[part 1 of 2: package /STELLANTIS/EPT/COMSWCs]
AUTOSAR XML (schema 4-2-2)
package /STELLANTIS/EPT/COMSWCs
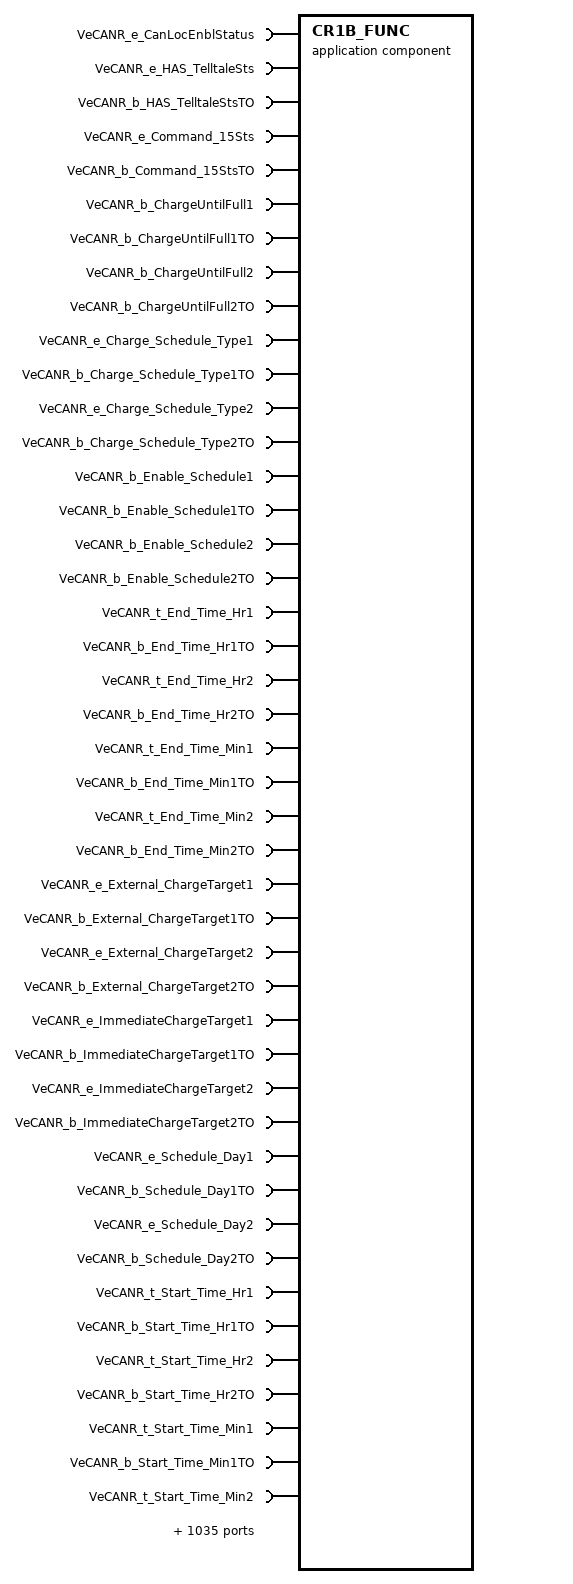
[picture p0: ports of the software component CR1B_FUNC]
  application sw component type CR1B_FUNC
    1085 x require port:
      VeCANR_e_CanLocEnblStatus: nonqueued-receiver-com-spec{data-element=VeCANR_e_CanLocEnblStatus, init-value=0}, required-interface=VeCANR_e_CanLocEnblStatus
      VeCANR_e_HAS_TelltaleSts: nonqueued-receiver-com-spec{data-element=VeCANR_e_HAS_TelltaleSts, handle-never-received=true, init-value=0}, required-interface=VeCANR_e_HAS_TelltaleSts
      VeCANR_b_HAS_TelltaleStsTO: nonqueued-receiver-com-spec{data-element=VeCANR_b_HAS_TelltaleStsTO, init-value=0}, required-interface=VeCANR_b_HAS_TelltaleStsTO
      VeCANR_e_Command_15Sts: nonqueued-receiver-com-spec{data-element=VeCANR_e_Command_15Sts, handle-never-received=true, init-value=0}, required-interface=VeCANR_e_Command_15Sts
      VeCANR_b_Command_15StsTO: nonqueued-receiver-com-spec{data-element=VeCANR_b_Command_15StsTO, init-value=0}, required-interface=VeCANR_b_Command_15StsTO
      VeCANR_b_ChargeUntilFull1: nonqueued-receiver-com-spec{data-element=VeCANR_b_ChargeUntilFull1, handle-never-received=true, init-value=0}, required-interface=VeCANR_b_ChargeUntilFull1
      VeCANR_b_ChargeUntilFull1TO: nonqueued-receiver-com-spec{data-element=VeCANR_b_ChargeUntilFull1TO, init-value=0}, required-interface=VeCANR_b_ChargeUntilFull1TO
      VeCANR_b_ChargeUntilFull2: nonqueued-receiver-com-spec{data-element=VeCANR_b_ChargeUntilFull2, handle-never-received=true, init-value=0}, required-interface=VeCANR_b_ChargeUntilFull2
      VeCANR_b_ChargeUntilFull2TO: nonqueued-receiver-com-spec{data-element=VeCANR_b_ChargeUntilFull2TO, init-value=0}, required-interface=VeCANR_b_ChargeUntilFull2TO
      VeCANR_e_Charge_Schedule_Type1: nonqueued-receiver-com-spec{data-element=VeCANR_e_Charge_Schedule_Type1, handle-never-received=true, init-value=0}, required-interface=VeCANR_e_Charge_Schedule_Type1
      VeCANR_b_Charge_Schedule_Type1TO: nonqueued-receiver-com-spec{data-element=VeCANR_b_Charge_Schedule_Type1TO, init-value=0}, required-interface=VeCANR_b_Charge_Schedule_Type1TO
      VeCANR_e_Charge_Schedule_Type2: nonqueued-receiver-com-spec{data-element=VeCANR_e_Charge_Schedule_Type2, handle-never-received=true, init-value=0}, required-interface=VeCANR_e_Charge_Schedule_Type2
      VeCANR_b_Charge_Schedule_Type2TO: nonqueued-receiver-com-spec{data-element=VeCANR_b_Charge_Schedule_Type2TO, init-value=0}, required-interface=VeCANR_b_Charge_Schedule_Type2TO
      VeCANR_b_Enable_Schedule1: nonqueued-receiver-com-spec{data-element=VeCANR_b_Enable_Schedule1, handle-never-received=true, init-value=0}, required-interface=VeCANR_b_Enable_Schedule1
      VeCANR_b_Enable_Schedule1TO: nonqueued-receiver-com-spec{data-element=VeCANR_b_Enable_Schedule1TO, init-value=0}, required-interface=VeCANR_b_Enable_Schedule1TO
      VeCANR_b_Enable_Schedule2: nonqueued-receiver-com-spec{data-element=VeCANR_b_Enable_Schedule2, handle-never-received=true, init-value=0}, required-interface=VeCANR_b_Enable_Schedule2
      VeCANR_b_Enable_Schedule2TO: nonqueued-receiver-com-spec{data-element=VeCANR_b_Enable_Schedule2TO, init-value=0}, required-interface=VeCANR_b_Enable_Schedule2TO
      VeCANR_t_End_Time_Hr1: nonqueued-receiver-com-spec{data-element=VeCANR_t_End_Time_Hr1, handle-never-received=true, init-value=0}, required-interface=VeCANR_t_End_Time_Hr1
      VeCANR_b_End_Time_Hr1TO: nonqueued-receiver-com-spec{data-element=VeCANR_b_End_Time_Hr1TO, init-value=0}, required-interface=VeCANR_b_End_Time_Hr1TO
      VeCANR_t_End_Time_Hr2: nonqueued-receiver-com-spec{data-element=VeCANR_t_End_Time_Hr2, handle-never-received=true, init-value=0}, required-interface=VeCANR_t_End_Time_Hr2
      VeCANR_b_End_Time_Hr2TO: nonqueued-receiver-com-spec{data-element=VeCANR_b_End_Time_Hr2TO, init-value=0}, required-interface=VeCANR_b_End_Time_Hr2TO
      VeCANR_t_End_Time_Min1: nonqueued-receiver-com-spec{data-element=VeCANR_t_End_Time_Min1, handle-never-received=true, init-value=0}, required-interface=VeCANR_t_End_Time_Min1
      VeCANR_b_End_Time_Min1TO: nonqueued-receiver-com-spec{data-element=VeCANR_b_End_Time_Min1TO, init-value=0}, required-interface=VeCANR_b_End_Time_Min1TO
      VeCANR_t_End_Time_Min2: nonqueued-receiver-com-spec{data-element=VeCANR_t_End_Time_Min2, handle-never-received=true, init-value=0}, required-interface=VeCANR_t_End_Time_Min2
      VeCANR_b_End_Time_Min2TO: nonqueued-receiver-com-spec{data-element=VeCANR_b_End_Time_Min2TO, init-value=0}, required-interface=VeCANR_b_End_Time_Min2TO
      VeCANR_e_External_ChargeTarget1: nonqueued-receiver-com-spec{data-element=VeCANR_e_External_ChargeTarget1, handle-never-received=true, init-value=0}, required-interface=VeCANR_e_External_ChargeTarget1
      VeCANR_b_External_ChargeTarget1TO: nonqueued-receiver-com-spec{data-element=VeCANR_b_External_ChargeTarget1TO, init-value=0}, required-interface=VeCANR_b_External_ChargeTarget1TO
      VeCANR_e_External_ChargeTarget2: nonqueued-receiver-com-spec{data-element=VeCANR_e_External_ChargeTarget2, handle-never-received=true, init-value=0}, required-interface=VeCANR_e_External_ChargeTarget2
      VeCANR_b_External_ChargeTarget2TO: nonqueued-receiver-com-spec{data-element=VeCANR_b_External_ChargeTarget2TO, init-value=0}, required-interface=VeCANR_b_External_ChargeTarget2TO
      VeCANR_e_ImmediateChargeTarget1: nonqueued-receiver-com-spec{data-element=VeCANR_e_ImmediateChargeTarget1, handle-never-received=true, init-value=0}, required-interface=VeCANR_e_ImmediateChargeTarget1
      VeCANR_b_ImmediateChargeTarget1TO: nonqueued-receiver-com-spec{data-element=VeCANR_b_ImmediateChargeTarget1TO, init-value=0}, required-interface=VeCANR_b_ImmediateChargeTarget1TO
      VeCANR_e_ImmediateChargeTarget2: nonqueued-receiver-com-spec{data-element=VeCANR_e_ImmediateChargeTarget2, handle-never-received=true, init-value=0}, required-interface=VeCANR_e_ImmediateChargeTarget2
      VeCANR_b_ImmediateChargeTarget2TO: nonqueued-receiver-com-spec{data-element=VeCANR_b_ImmediateChargeTarget2TO, init-value=0}, required-interface=VeCANR_b_ImmediateChargeTarget2TO
      VeCANR_e_Schedule_Day1: nonqueued-receiver-com-spec{data-element=VeCANR_e_Schedule_Day1, handle-never-received=true, init-value=0}, required-interface=VeCANR_e_Schedule_Day1
      VeCANR_b_Schedule_Day1TO: nonqueued-receiver-com-spec{data-element=VeCANR_b_Schedule_Day1TO, init-value=0}, required-interface=VeCANR_b_Schedule_Day1TO
      VeCANR_e_Schedule_Day2: nonqueued-receiver-com-spec{data-element=VeCANR_e_Schedule_Day2, handle-never-received=true, init-value=0}, required-interface=VeCANR_e_Schedule_Day2
      VeCANR_b_Schedule_Day2TO: nonqueued-receiver-com-spec{data-element=VeCANR_b_Schedule_Day2TO, init-value=0}, required-interface=VeCANR_b_Schedule_Day2TO
      VeCANR_t_Start_Time_Hr1: nonqueued-receiver-com-spec{data-element=VeCANR_t_Start_Time_Hr1, handle-never-received=true, init-value=0}, required-interface=VeCANR_t_Start_Time_Hr1
      VeCANR_b_Start_Time_Hr1TO: nonqueued-receiver-com-spec{data-element=VeCANR_b_Start_Time_Hr1TO, init-value=0}, required-interface=VeCANR_b_Start_Time_Hr1TO
      VeCANR_t_Start_Time_Hr2: nonqueued-receiver-com-spec{data-element=VeCANR_t_Start_Time_Hr2, handle-never-received=true, init-value=0}, required-interface=VeCANR_t_Start_Time_Hr2
      VeCANR_b_Start_Time_Hr2TO: nonqueued-receiver-com-spec{data-element=VeCANR_b_Start_Time_Hr2TO, init-value=0}, required-interface=VeCANR_b_Start_Time_Hr2TO
      VeCANR_t_Start_Time_Min1: nonqueued-receiver-com-spec{data-element=VeCANR_t_Start_Time_Min1, handle-never-received=true, init-value=0}, required-interface=VeCANR_t_Start_Time_Min1
      VeCANR_b_Start_Time_Min1TO: nonqueued-receiver-com-spec{data-element=VeCANR_b_Start_Time_Min1TO, init-value=0}, required-interface=VeCANR_b_Start_Time_Min1TO
      VeCANR_t_Start_Time_Min2: nonqueued-receiver-com-spec{data-element=VeCANR_t_Start_Time_Min2, handle-never-received=true, init-value=0}, required-interface=VeCANR_t_Start_Time_Min2
      VeCANR_b_Start_Time_Min2TO: nonqueued-receiver-com-spec{data-element=VeCANR_b_Start_Time_Min2TO, init-value=0}, required-interface=VeCANR_b_Start_Time_Min2TO
      VeCANR_b_Submit_Schedule1: nonqueued-receiver-com-spec{data-element=VeCANR_b_Submit_Schedule1, handle-never-received=true, init-value=0}, required-interface=VeCANR_b_Submit_Schedule1
      VeCANR_b_Submit_Schedule1TO: nonqueued-receiver-com-spec{data-element=VeCANR_b_Submit_Schedule1TO, init-value=0}, required-interface=VeCANR_b_Submit_Schedule1TO
      VeCANR_b_Submit_Schedule2: nonqueued-receiver-com-spec{data-element=VeCANR_b_Submit_Schedule2, handle-never-received=true, init-value=0}, required-interface=VeCANR_b_Submit_Schedule2
      VeCANR_b_Submit_Schedule2TO: nonqueued-receiver-com-spec{data-element=VeCANR_b_Submit_Schedule2TO, init-value=0}, required-interface=VeCANR_b_Submit_Schedule2TO
      VeCANR_e_AllowClimateSchd1: nonqueued-receiver-com-spec{data-element=VeCANR_e_AllowClimateSchd1, handle-never-received=true, init-value=0}, required-interface=VeCANR_e_AllowClimateSchd1
      VeCANR_b_AllowClimateSchd1TO: nonqueued-receiver-com-spec{data-element=VeCANR_b_AllowClimateSchd1TO, init-value=0}, required-interface=VeCANR_b_AllowClimateSchd1TO
      VeCANR_e_AllowClimateSchd2: nonqueued-receiver-com-spec{data-element=VeCANR_e_AllowClimateSchd2, handle-never-received=true, init-value=0}, required-interface=VeCANR_e_AllowClimateSchd2
      VeCANR_b_AllowClimateSchd2TO: nonqueued-receiver-com-spec{data-element=VeCANR_b_AllowClimateSchd2TO, init-value=0}, required-interface=VeCANR_b_AllowClimateSchd2TO
      VeCANR_e_ClimateSchd1_Day: nonqueued-receiver-com-spec{data-element=VeCANR_e_ClimateSchd1_Day, handle-never-received=true, init-value=0}, required-interface=VeCANR_e_ClimateSchd1_Day
      VeCANR_b_ClimateSchd1_DayTO: nonqueued-receiver-com-spec{data-element=VeCANR_b_ClimateSchd1_DayTO, init-value=0}, required-interface=VeCANR_b_ClimateSchd1_DayTO
      VeCANR_t_ClimateSchd1_Dprtr_Hr: nonqueued-receiver-com-spec{data-element=VeCANR_t_ClimateSchd1_Dprtr_Hr, handle-never-received=true, init-value=0}, required-interface=VeCANR_t_ClimateSchd1_Dprtr_Hr
      VeCANR_b_ClimateSchd1_Dprtr_HrTO: nonqueued-receiver-com-spec{data-element=VeCANR_b_ClimateSchd1_Dprtr_HrTO, init-value=0}, required-interface=VeCANR_b_ClimateSchd1_Dprtr_HrTO
      VeCANR_t_ClimateSchd1_Dprtr_Min: nonqueued-receiver-com-spec{data-element=VeCANR_t_ClimateSchd1_Dprtr_Min, handle-never-received=true, init-value=0}, required-interface=VeCANR_t_ClimateSchd1_Dprtr_Min
      VeCANR_b_ClimateSchd1_Dprtr_MinTO: nonqueued-receiver-com-spec{data-element=VeCANR_b_ClimateSchd1_Dprtr_MinTO, init-value=0}, required-interface=VeCANR_b_ClimateSchd1_Dprtr_MinTO
      VeCANR_e_ClimateSchd2_Day: nonqueued-receiver-com-spec{data-element=VeCANR_e_ClimateSchd2_Day, handle-never-received=true, init-value=0}, required-interface=VeCANR_e_ClimateSchd2_Day
      VeCANR_b_ClimateSchd2_DayTO: nonqueued-receiver-com-spec{data-element=VeCANR_b_ClimateSchd2_DayTO, init-value=0}, required-interface=VeCANR_b_ClimateSchd2_DayTO
      VeCANR_t_ClimateSchd2_Dprtr_Hr: nonqueued-receiver-com-spec{data-element=VeCANR_t_ClimateSchd2_Dprtr_Hr, handle-never-received=true, init-value=0}, required-interface=VeCANR_t_ClimateSchd2_Dprtr_Hr
      VeCANR_b_ClimateSchd2_Dprtr_HrTO: nonqueued-receiver-com-spec{data-element=VeCANR_b_ClimateSchd2_Dprtr_HrTO, init-value=0}, required-interface=VeCANR_b_ClimateSchd2_Dprtr_HrTO
      VeCANR_t_ClimateSchd2_Dprtr_Min: nonqueued-receiver-com-spec{data-element=VeCANR_t_ClimateSchd2_Dprtr_Min, handle-never-received=true, init-value=0}, required-interface=VeCANR_t_ClimateSchd2_Dprtr_Min
      VeCANR_b_ClimateSchd2_Dprtr_MinTO: nonqueued-receiver-com-spec{data-element=VeCANR_b_ClimateSchd2_Dprtr_MinTO, init-value=0}, required-interface=VeCANR_b_ClimateSchd2_Dprtr_MinTO
      VeCANR_T_Climate_Cabin_Temp1: nonqueued-receiver-com-spec{data-element=VeCANR_T_Climate_Cabin_Temp1, handle-never-received=true, init-value=0}, required-interface=VeCANR_T_Climate_Cabin_Temp1
      VeCANR_b_Climate_Cabin_Temp1TO: nonqueued-receiver-com-spec{data-element=VeCANR_b_Climate_Cabin_Temp1TO, init-value=0}, required-interface=VeCANR_b_Climate_Cabin_Temp1TO
      VeCANR_T_Climate_Cabin_Temp2: nonqueued-receiver-com-spec{data-element=VeCANR_T_Climate_Cabin_Temp2, handle-never-received=true, init-value=0}, required-interface=VeCANR_T_Climate_Cabin_Temp2
      VeCANR_b_Climate_Cabin_Temp2TO: nonqueued-receiver-com-spec{data-element=VeCANR_b_Climate_Cabin_Temp2TO, init-value=0}, required-interface=VeCANR_b_Climate_Cabin_Temp2TO
      VeCANR_b_Enable_ClimateSchd1: nonqueued-receiver-com-spec{data-element=VeCANR_b_Enable_ClimateSchd1, handle-never-received=true, init-value=0}, required-interface=VeCANR_b_Enable_ClimateSchd1
      VeCANR_b_Enable_ClimateSchd1TO: nonqueued-receiver-com-spec{data-element=VeCANR_b_Enable_ClimateSchd1TO, init-value=0}, required-interface=VeCANR_b_Enable_ClimateSchd1TO
      VeCANR_b_Enable_ClimateSchd2: nonqueued-receiver-com-spec{data-element=VeCANR_b_Enable_ClimateSchd2, handle-never-received=true, init-value=0}, required-interface=VeCANR_b_Enable_ClimateSchd2
      VeCANR_b_Enable_ClimateSchd2TO: nonqueued-receiver-com-spec{data-element=VeCANR_b_Enable_ClimateSchd2TO, init-value=0}, required-interface=VeCANR_b_Enable_ClimateSchd2TO
      VeCANR_b_Submit_ClimateSchd1: nonqueued-receiver-com-spec{data-element=VeCANR_b_Submit_ClimateSchd1, handle-never-received=true, init-value=0}, required-interface=VeCANR_b_Submit_ClimateSchd1
      VeCANR_b_Submit_ClimateSchd1TO: nonqueued-receiver-com-spec{data-element=VeCANR_b_Submit_ClimateSchd1TO, init-value=0}, required-interface=VeCANR_b_Submit_ClimateSchd1TO
      VeCANR_b_Submit_ClimateSchd2: nonqueued-receiver-com-spec{data-element=VeCANR_b_Submit_ClimateSchd2, handle-never-received=true, init-value=0}, required-interface=VeCANR_b_Submit_ClimateSchd2
      VeCANR_b_Submit_ClimateSchd2TO: nonqueued-receiver-com-spec{data-element=VeCANR_b_Submit_ClimateSchd2TO, init-value=0}, required-interface=VeCANR_b_Submit_ClimateSchd2TO
      VeCANR_T_Climate_TBM_CabinTemp1: nonqueued-receiver-com-spec{data-element=VeCANR_T_Climate_TBM_CabinTemp1, handle-never-received=true, init-value=0}, required-interface=VeCANR_T_Climate_TBM_CabinTemp1
      VeCANR_b_Climate_TBM_CabinTemp1TO: nonqueued-receiver-com-spec{data-element=VeCANR_b_Climate_TBM_CabinTemp1TO, init-value=0}, required-interface=VeCANR_b_Climate_TBM_CabinTemp1TO
      VeCANR_T_Climate_TBM_CabinTemp2: nonqueued-receiver-com-spec{data-element=VeCANR_T_Climate_TBM_CabinTemp2, handle-never-received=true, init-value=0}, required-interface=VeCANR_T_Climate_TBM_CabinTemp2
      VeCANR_b_Climate_TBM_CabinTemp2TO: nonqueued-receiver-com-spec{data-element=VeCANR_b_Climate_TBM_CabinTemp2TO, init-value=0}, required-interface=VeCANR_b_Climate_TBM_CabinTemp2TO
      VeCANR_e_TBM_AllowClimateSchd1: nonqueued-receiver-com-spec{data-element=VeCANR_e_TBM_AllowClimateSchd1, handle-never-received=true, init-value=0}, required-interface=VeCANR_e_TBM_AllowClimateSchd1
      VeCANR_b_TBM_AllowClimateSchd1TO: nonqueued-receiver-com-spec{data-element=VeCANR_b_TBM_AllowClimateSchd1TO, init-value=0}, required-interface=VeCANR_b_TBM_AllowClimateSchd1TO
      VeCANR_e_TBM_AllowClimateSchd2: nonqueued-receiver-com-spec{data-element=VeCANR_e_TBM_AllowClimateSchd2, handle-never-received=true, init-value=0}, required-interface=VeCANR_e_TBM_AllowClimateSchd2
      VeCANR_b_TBM_AllowClimateSchd2TO: nonqueued-receiver-com-spec{data-element=VeCANR_b_TBM_AllowClimateSchd2TO, init-value=0}, required-interface=VeCANR_b_TBM_AllowClimateSchd2TO
      VeCANR_e_TBM_ClimateSchd1_Day: nonqueued-receiver-com-spec{data-element=VeCANR_e_TBM_ClimateSchd1_Day, handle-never-received=true, init-value=0}, required-interface=VeCANR_e_TBM_ClimateSchd1_Day
      VeCANR_b_TBM_ClimateSchd1_DayTO: nonqueued-receiver-com-spec{data-element=VeCANR_b_TBM_ClimateSchd1_DayTO, init-value=0}, required-interface=VeCANR_b_TBM_ClimateSchd1_DayTO
      VeCANR_t_TBM_ClimSchd1DprtrHr: nonqueued-receiver-com-spec{data-element=VeCANR_t_TBM_ClimSchd1DprtrHr, handle-never-received=true, init-value=0}, required-interface=VeCANR_t_TBM_ClimSchd1DprtrHr
      VeCANR_b_TBM_ClimSchd1DprtrHrTO: nonqueued-receiver-com-spec{data-element=VeCANR_b_TBM_ClimSchd1DprtrHrTO, init-value=0}, required-interface=VeCANR_b_TBM_ClimSchd1DprtrHrTO
      VeCANR_t_TBM_ClimSchd1DprtrMin: nonqueued-receiver-com-spec{data-element=VeCANR_t_TBM_ClimSchd1DprtrMin, handle-never-received=true, init-value=0}, required-interface=VeCANR_t_TBM_ClimSchd1DprtrMin
      VeCANR_b_TBM_ClimSchd1DprtrMinTO: nonqueued-receiver-com-spec{data-element=VeCANR_b_TBM_ClimSchd1DprtrMinTO, init-value=0}, required-interface=VeCANR_b_TBM_ClimSchd1DprtrMinTO
      VeCANR_e_TBM_ClimateSchd2_Day: nonqueued-receiver-com-spec{data-element=VeCANR_e_TBM_ClimateSchd2_Day, handle-never-received=true, init-value=0}, required-interface=VeCANR_e_TBM_ClimateSchd2_Day
      VeCANR_b_TBM_ClimateSchd2_DayTO: nonqueued-receiver-com-spec{data-element=VeCANR_b_TBM_ClimateSchd2_DayTO, init-value=0}, required-interface=VeCANR_b_TBM_ClimateSchd2_DayTO
      VeCANR_t_TBM_ClimSchd2DprtrHr: nonqueued-receiver-com-spec{data-element=VeCANR_t_TBM_ClimSchd2DprtrHr, handle-never-received=true, init-value=0}, required-interface=VeCANR_t_TBM_ClimSchd2DprtrHr
      VeCANR_b_TBM_ClimSchd2DprtrHrTO: nonqueued-receiver-com-spec{data-element=VeCANR_b_TBM_ClimSchd2DprtrHrTO, init-value=0}, required-interface=VeCANR_b_TBM_ClimSchd2DprtrHrTO
      VeCANR_t_TBM_ClimSchd2DprtrMin: nonqueued-receiver-com-spec{data-element=VeCANR_t_TBM_ClimSchd2DprtrMin, handle-never-received=true, init-value=0}, required-interface=VeCANR_t_TBM_ClimSchd2DprtrMin
      VeCANR_b_TBM_ClimSchd2DprtrMinTO: nonqueued-receiver-com-spec{data-element=VeCANR_b_TBM_ClimSchd2DprtrMinTO, init-value=0}, required-interface=VeCANR_b_TBM_ClimSchd2DprtrMinTO
      VeCANR_b_TBM_EnableClimateSchd1: nonqueued-receiver-com-spec{data-element=VeCANR_b_TBM_EnableClimateSchd1, handle-never-received=true, init-value=0}, required-interface=VeCANR_b_TBM_EnableClimateSchd1
      VeCANR_b_TBM_EnableClimateSchd1TO: nonqueued-receiver-com-spec{data-element=VeCANR_b_TBM_EnableClimateSchd1TO, init-value=0}, required-interface=VeCANR_b_TBM_EnableClimateSchd1TO
      VeCANR_b_TBM_EnableClimateSchd2: nonqueued-receiver-com-spec{data-element=VeCANR_b_TBM_EnableClimateSchd2, handle-never-received=true, init-value=0}, required-interface=VeCANR_b_TBM_EnableClimateSchd2
      VeCANR_b_TBM_EnableClimateSchd2TO: nonqueued-receiver-com-spec{data-element=VeCANR_b_TBM_EnableClimateSchd2TO, init-value=0}, required-interface=VeCANR_b_TBM_EnableClimateSchd2TO
      VeCANR_b_TBM_SubmitClimateSchd1: nonqueued-receiver-com-spec{data-element=VeCANR_b_TBM_SubmitClimateSchd1, handle-never-received=true, init-value=0}, required-interface=VeCANR_b_TBM_SubmitClimateSchd1
      VeCANR_b_TBM_SubmitClimateSchd1TO: nonqueued-receiver-com-spec{data-element=VeCANR_b_TBM_SubmitClimateSchd1TO, init-value=0}, required-interface=VeCANR_b_TBM_SubmitClimateSchd1TO
      VeCANR_b_TBM_SubmitClimateSchd2: nonqueued-receiver-com-spec{data-element=VeCANR_b_TBM_SubmitClimateSchd2, handle-never-received=true, init-value=0}, required-interface=VeCANR_b_TBM_SubmitClimateSchd2
      VeCANR_b_TBM_SubmitClimateSchd2TO: nonqueued-receiver-com-spec{data-element=VeCANR_b_TBM_SubmitClimateSchd2TO, init-value=0}, required-interface=VeCANR_b_TBM_SubmitClimateSchd2TO
      VeCANR_b_CooperativeVehclLocatn: nonqueued-receiver-com-spec{data-element=VeCANR_b_CooperativeVehclLocatn, handle-never-received=true, init-value=0}, required-interface=VeCANR_b_CooperativeVehclLocatn
      VeCANR_b_CooperativeVehclLocatnTO: nonqueued-receiver-com-spec{data-element=VeCANR_b_CooperativeVehclLocatnTO, init-value=0}, required-interface=VeCANR_b_CooperativeVehclLocatnTO
      VeCANR_e_Remote_Chargeport_Cmnd: nonqueued-receiver-com-spec{data-element=VeCANR_e_Remote_Chargeport_Cmnd, handle-never-received=true, init-value=0}, required-interface=VeCANR_e_Remote_Chargeport_Cmnd
      VeCANR_b_Remote_Chargeport_CmndTO: nonqueued-receiver-com-spec{data-element=VeCANR_b_Remote_Chargeport_CmndTO, init-value=0}, required-interface=VeCANR_b_Remote_Chargeport_CmndTO
      VeCANR_e_TBMCooperativeChrgCmnd: nonqueued-receiver-com-spec{data-element=VeCANR_e_TBMCooperativeChrgCmnd, handle-never-received=true, init-value=0}, required-interface=VeCANR_e_TBMCooperativeChrgCmnd
      VeCANR_b_TBMCooperativeChrgCmndTO: nonqueued-receiver-com-spec{data-element=VeCANR_b_TBMCooperativeChrgCmndTO, init-value=0}, required-interface=VeCANR_b_TBMCooperativeChrgCmndTO
      VeCANR_b_TBM_StopCharge: nonqueued-receiver-com-spec{data-element=VeCANR_b_TBM_StopCharge, handle-never-received=true, init-value=0}, required-interface=VeCANR_b_TBM_StopCharge
      VeCANR_b_TBM_StopChargeTO: nonqueued-receiver-com-spec{data-element=VeCANR_b_TBM_StopChargeTO, init-value=0}, required-interface=VeCANR_b_TBM_StopChargeTO
      VeCANR_e_TBMChrgSchedulType1Req: nonqueued-receiver-com-spec{data-element=VeCANR_e_TBMChrgSchedulType1Req, handle-never-received=true, init-value=0}, required-interface=VeCANR_e_TBMChrgSchedulType1Req
      VeCANR_b_TBMChrgSchedulType1ReqTO: nonqueued-receiver-com-spec{data-element=VeCANR_b_TBMChrgSchedulType1ReqTO, init-value=0}, required-interface=VeCANR_b_TBMChrgSchedulType1ReqTO
      VeCANR_e_TBMChrgSchedulType2Req: nonqueued-receiver-com-spec{data-element=VeCANR_e_TBMChrgSchedulType2Req, handle-never-received=true, init-value=0}, required-interface=VeCANR_e_TBMChrgSchedulType2Req
      VeCANR_b_TBMChrgSchedulType2ReqTO: nonqueued-receiver-com-spec{data-element=VeCANR_b_TBMChrgSchedulType2ReqTO, init-value=0}, required-interface=VeCANR_b_TBMChrgSchedulType2ReqTO
      VeCANR_b_TBM_ChargeUntilFull1: nonqueued-receiver-com-spec{data-element=VeCANR_b_TBM_ChargeUntilFull1, handle-never-received=true, init-value=0}, required-interface=VeCANR_b_TBM_ChargeUntilFull1
      VeCANR_b_TBM_ChargeUntilFull1TO: nonqueued-receiver-com-spec{data-element=VeCANR_b_TBM_ChargeUntilFull1TO, init-value=0}, required-interface=VeCANR_b_TBM_ChargeUntilFull1TO
      VeCANR_b_TBM_ChargeUntilFull2: nonqueued-receiver-com-spec{data-element=VeCANR_b_TBM_ChargeUntilFull2, handle-never-received=true, init-value=0}, required-interface=VeCANR_b_TBM_ChargeUntilFull2
      VeCANR_b_TBM_ChargeUntilFull2TO: nonqueued-receiver-com-spec{data-element=VeCANR_b_TBM_ChargeUntilFull2TO, init-value=0}, required-interface=VeCANR_b_TBM_ChargeUntilFull2TO
      VeCANR_b_TBM_Charge_Now: nonqueued-receiver-com-spec{data-element=VeCANR_b_TBM_Charge_Now, handle-never-received=true, init-value=0}, required-interface=VeCANR_b_TBM_Charge_Now
      VeCANR_b_TBM_Charge_NowTO: nonqueued-receiver-com-spec{data-element=VeCANR_b_TBM_Charge_NowTO, init-value=0}, required-interface=VeCANR_b_TBM_Charge_NowTO
      VeCANR_b_TBM_Enable_Schedule1: nonqueued-receiver-com-spec{data-element=VeCANR_b_TBM_Enable_Schedule1, handle-never-received=true, init-value=0}, required-interface=VeCANR_b_TBM_Enable_Schedule1
      VeCANR_b_TBM_Enable_Schedule1TO: nonqueued-receiver-com-spec{data-element=VeCANR_b_TBM_Enable_Schedule1TO, init-value=0}, required-interface=VeCANR_b_TBM_Enable_Schedule1TO
      VeCANR_b_TBM_Enable_Schedule2: nonqueued-receiver-com-spec{data-element=VeCANR_b_TBM_Enable_Schedule2, handle-never-received=true, init-value=0}, required-interface=VeCANR_b_TBM_Enable_Schedule2
      VeCANR_b_TBM_Enable_Schedule2TO: nonqueued-receiver-com-spec{data-element=VeCANR_b_TBM_Enable_Schedule2TO, init-value=0}, required-interface=VeCANR_b_TBM_Enable_Schedule2TO
      VeCANR_t_TBM_End_Time_Hr1: nonqueued-receiver-com-spec{data-element=VeCANR_t_TBM_End_Time_Hr1, handle-never-received=true, init-value=0}, required-interface=VeCANR_t_TBM_End_Time_Hr1
      VeCANR_b_TBM_End_Time_Hr1TO: nonqueued-receiver-com-spec{data-element=VeCANR_b_TBM_End_Time_Hr1TO, init-value=0}, required-interface=VeCANR_b_TBM_End_Time_Hr1TO
      VeCANR_t_TBM_End_Time_Hr2: nonqueued-receiver-com-spec{data-element=VeCANR_t_TBM_End_Time_Hr2, handle-never-received=true, init-value=0}, required-interface=VeCANR_t_TBM_End_Time_Hr2
      VeCANR_b_TBM_End_Time_Hr2TO: nonqueued-receiver-com-spec{data-element=VeCANR_b_TBM_End_Time_Hr2TO, init-value=0}, required-interface=VeCANR_b_TBM_End_Time_Hr2TO
      VeCANR_t_TBM_End_Time_Min1: nonqueued-receiver-com-spec{data-element=VeCANR_t_TBM_End_Time_Min1, handle-never-received=true, init-value=0}, required-interface=VeCANR_t_TBM_End_Time_Min1
      VeCANR_b_TBM_End_Time_Min1TO: nonqueued-receiver-com-spec{data-element=VeCANR_b_TBM_End_Time_Min1TO, init-value=0}, required-interface=VeCANR_b_TBM_End_Time_Min1TO
      VeCANR_t_TBM_End_Time_Min2: nonqueued-receiver-com-spec{data-element=VeCANR_t_TBM_End_Time_Min2, handle-never-received=true, init-value=0}, required-interface=VeCANR_t_TBM_End_Time_Min2
      VeCANR_b_TBM_End_Time_Min2TO: nonqueued-receiver-com-spec{data-element=VeCANR_b_TBM_End_Time_Min2TO, init-value=0}, required-interface=VeCANR_b_TBM_End_Time_Min2TO
      VeCANR_e_TBMExtrnlChrgTarget1: nonqueued-receiver-com-spec{data-element=VeCANR_e_TBMExtrnlChrgTarget1, handle-never-received=true, init-value=0}, required-interface=VeCANR_e_TBMExtrnlChrgTarget1
      VeCANR_b_TBMExtrnlChrgTarget1TO: nonqueued-receiver-com-spec{data-element=VeCANR_b_TBMExtrnlChrgTarget1TO, init-value=0}, required-interface=VeCANR_b_TBMExtrnlChrgTarget1TO
      VeCANR_e_TBM_ExtrnlChargTarget2: nonqueued-receiver-com-spec{data-element=VeCANR_e_TBM_ExtrnlChargTarget2, handle-never-received=true, init-value=0}, required-interface=VeCANR_e_TBM_ExtrnlChargTarget2
      VeCANR_b_TBM_ExtrnlChargTarget2TO: nonqueued-receiver-com-spec{data-element=VeCANR_b_TBM_ExtrnlChargTarget2TO, init-value=0}, required-interface=VeCANR_b_TBM_ExtrnlChargTarget2TO
      VeCANR_e_TBMImmediatChrgTarget1: nonqueued-receiver-com-spec{data-element=VeCANR_e_TBMImmediatChrgTarget1, handle-never-received=true, init-value=0}, required-interface=VeCANR_e_TBMImmediatChrgTarget1
      VeCANR_b_TBMImmediatChrgTarget1TO: nonqueued-receiver-com-spec{data-element=VeCANR_b_TBMImmediatChrgTarget1TO, init-value=0}, required-interface=VeCANR_b_TBMImmediatChrgTarget1TO
      VeCANR_e_TBMImmediatChrgTarget2: nonqueued-receiver-com-spec{data-element=VeCANR_e_TBMImmediatChrgTarget2, handle-never-received=true, init-value=0}, required-interface=VeCANR_e_TBMImmediatChrgTarget2
      VeCANR_b_TBMImmediatChrgTarget2TO: nonqueued-receiver-com-spec{data-element=VeCANR_b_TBMImmediatChrgTarget2TO, init-value=0}, required-interface=VeCANR_b_TBMImmediatChrgTarget2TO
      VeCANR_e_TBM_Schedule_Day1: nonqueued-receiver-com-spec{data-element=VeCANR_e_TBM_Schedule_Day1, handle-never-received=true, init-value=0}, required-interface=VeCANR_e_TBM_Schedule_Day1
      VeCANR_b_TBM_Schedule_Day1TO: nonqueued-receiver-com-spec{data-element=VeCANR_b_TBM_Schedule_Day1TO, init-value=0}, required-interface=VeCANR_b_TBM_Schedule_Day1TO
      VeCANR_e_TBM_Schedule_Day2: nonqueued-receiver-com-spec{data-element=VeCANR_e_TBM_Schedule_Day2, handle-never-received=true, init-value=0}, required-interface=VeCANR_e_TBM_Schedule_Day2
      VeCANR_b_TBM_Schedule_Day2TO: nonqueued-receiver-com-spec{data-element=VeCANR_b_TBM_Schedule_Day2TO, init-value=0}, required-interface=VeCANR_b_TBM_Schedule_Day2TO
      VeCANR_t_TBM_Start_Time_Hr1: nonqueued-receiver-com-spec{data-element=VeCANR_t_TBM_Start_Time_Hr1, handle-never-received=true, init-value=0}, required-interface=VeCANR_t_TBM_Start_Time_Hr1
      VeCANR_b_TBM_Start_Time_Hr1TO: nonqueued-receiver-com-spec{data-element=VeCANR_b_TBM_Start_Time_Hr1TO, init-value=0}, required-interface=VeCANR_b_TBM_Start_Time_Hr1TO
      VeCANR_t_TBM_Start_Time_Hr2: nonqueued-receiver-com-spec{data-element=VeCANR_t_TBM_Start_Time_Hr2, handle-never-received=true, init-value=0}, required-interface=VeCANR_t_TBM_Start_Time_Hr2
      VeCANR_b_TBM_Start_Time_Hr2TO: nonqueued-receiver-com-spec{data-element=VeCANR_b_TBM_Start_Time_Hr2TO, init-value=0}, required-interface=VeCANR_b_TBM_Start_Time_Hr2TO
      VeCANR_t_TBM_Start_Time_Min1: nonqueued-receiver-com-spec{data-element=VeCANR_t_TBM_Start_Time_Min1, handle-never-received=true, init-value=0}, required-interface=VeCANR_t_TBM_Start_Time_Min1
      VeCANR_b_TBM_Start_Time_Min1TO: nonqueued-receiver-com-spec{data-element=VeCANR_b_TBM_Start_Time_Min1TO, init-value=0}, required-interface=VeCANR_b_TBM_Start_Time_Min1TO
      VeCANR_t_TBM_Start_Time_Min2: nonqueued-receiver-com-spec{data-element=VeCANR_t_TBM_Start_Time_Min2, handle-never-received=true, init-value=0}, required-interface=VeCANR_t_TBM_Start_Time_Min2
      VeCANR_b_TBM_Start_Time_Min2TO: nonqueued-receiver-com-spec{data-element=VeCANR_b_TBM_Start_Time_Min2TO, init-value=0}, required-interface=VeCANR_b_TBM_Start_Time_Min2TO
      VeCANR_b_TBM_Submit_Schedule1: nonqueued-receiver-com-spec{data-element=VeCANR_b_TBM_Submit_Schedule1, handle-never-received=true, init-value=0}, required-interface=VeCANR_b_TBM_Submit_Schedule1
      VeCANR_b_TBM_Submit_Schedule1TO: nonqueued-receiver-com-spec{data-element=VeCANR_b_TBM_Submit_Schedule1TO, init-value=0}, required-interface=VeCANR_b_TBM_Submit_Schedule1TO
      VeCANR_b_TBM_Submit_Schedule2: nonqueued-receiver-com-spec{data-element=VeCANR_b_TBM_Submit_Schedule2, handle-never-received=true, init-value=0}, required-interface=VeCANR_b_TBM_Submit_Schedule2
      VeCANR_b_TBM_Submit_Schedule2TO: nonqueued-receiver-com-spec{data-element=VeCANR_b_TBM_Submit_Schedule2TO, init-value=0}, required-interface=VeCANR_b_TBM_Submit_Schedule2TO
      VeCANR_y_Day1_TLM: nonqueued-receiver-com-spec{data-element=VeCANR_y_Day1_TLM, handle-never-received=true, init-value=0}, required-interface=VeCANR_y_Day1_TLM
      VeCANR_b_Day1_TLM_TO: nonqueued-receiver-com-spec{data-element=VeCANR_b_Day1_TLM_TO, init-value=0}, required-interface=VeCANR_b_Day1_TLM_TO
      VeCANR_y_Day2_TLM: nonqueued-receiver-com-spec{data-element=VeCANR_y_Day2_TLM, handle-never-received=true, init-value=0}, required-interface=VeCANR_y_Day2_TLM
      VeCANR_b_Day2_TLM_TO: nonqueued-receiver-com-spec{data-element=VeCANR_b_Day2_TLM_TO, init-value=0}, required-interface=VeCANR_b_Day2_TLM_TO
      VeCANR_t_GPS_Date_Day: nonqueued-receiver-com-spec{data-element=VeCANR_t_GPS_Date_Day, handle-never-received=true, init-value=0}, required-interface=VeCANR_t_GPS_Date_Day
      VeCANR_b_GPS_Date_DayTO: nonqueued-receiver-com-spec{data-element=VeCANR_b_GPS_Date_DayTO, init-value=0}, required-interface=VeCANR_b_GPS_Date_DayTO
      VeCANR_cmp_GPS_Date_Month: nonqueued-receiver-com-spec{data-element=VeCANR_cmp_GPS_Date_Month, handle-never-received=true, init-value=0}, required-interface=VeCANR_cmp_GPS_Date_Month
      VeCANR_b_GPS_Date_MonthTO: nonqueued-receiver-com-spec{data-element=VeCANR_b_GPS_Date_MonthTO, init-value=0}, required-interface=VeCANR_b_GPS_Date_MonthTO
      VeCANR_t_GPS_Date_Year: nonqueued-receiver-com-spec{data-element=VeCANR_t_GPS_Date_Year, handle-never-received=true, init-value=0}, required-interface=VeCANR_t_GPS_Date_Year
      VeCANR_b_GPS_Date_YearTO: nonqueued-receiver-com-spec{data-element=VeCANR_b_GPS_Date_YearTO, init-value=0}, required-interface=VeCANR_b_GPS_Date_YearTO
      VeCANR_t_GPS_UTC_Hour: nonqueued-receiver-com-spec{data-element=VeCANR_t_GPS_UTC_Hour, handle-never-received=true, init-value=0}, required-interface=VeCANR_t_GPS_UTC_Hour
      VeCANR_b_GPS_UTC_HourTO: nonqueued-receiver-com-spec{data-element=VeCANR_b_GPS_UTC_HourTO, init-value=0}, required-interface=VeCANR_b_GPS_UTC_HourTO
      VeCANR_t_GPS_UTC_Minute: nonqueued-receiver-com-spec{data-element=VeCANR_t_GPS_UTC_Minute, handle-never-received=true, init-value=0}, required-interface=VeCANR_t_GPS_UTC_Minute
      VeCANR_b_GPS_UTC_MinuteTO: nonqueued-receiver-com-spec{data-element=VeCANR_b_GPS_UTC_MinuteTO, init-value=0}, required-interface=VeCANR_b_GPS_UTC_MinuteTO
      VeCANR_t_GPS_UTC_Second: nonqueued-receiver-com-spec{data-element=VeCANR_t_GPS_UTC_Second, handle-never-received=true, init-value=0}, required-interface=VeCANR_t_GPS_UTC_Second
      VeCANR_b_GPS_UTC_SecondTO: nonqueued-receiver-com-spec{data-element=VeCANR_b_GPS_UTC_SecondTO, init-value=0}, required-interface=VeCANR_b_GPS_UTC_SecondTO
      VeCANR_y_Hour1_TLM: nonqueued-receiver-com-spec{data-element=VeCANR_y_Hour1_TLM, handle-never-received=true, init-value=0}, required-interface=VeCANR_y_Hour1_TLM
      VeCANR_b_Hour1_TLM_TO: nonqueued-receiver-com-spec{data-element=VeCANR_b_Hour1_TLM_TO, init-value=0}, required-interface=VeCANR_b_Hour1_TLM_TO
      VeCANR_y_Hour2_TLM: nonqueued-receiver-com-spec{data-element=VeCANR_y_Hour2_TLM, handle-never-received=true, init-value=0}, required-interface=VeCANR_y_Hour2_TLM
      VeCANR_b_Hour2_TLM_TO: nonqueued-receiver-com-spec{data-element=VeCANR_b_Hour2_TLM_TO, init-value=0}, required-interface=VeCANR_b_Hour2_TLM_TO
      VeCANR_y_Minute1_TLM: nonqueued-receiver-com-spec{data-element=VeCANR_y_Minute1_TLM, handle-never-received=true, init-value=0}, required-interface=VeCANR_y_Minute1_TLM
      VeCANR_b_Minute1_TLM_TO: nonqueued-receiver-com-spec{data-element=VeCANR_b_Minute1_TLM_TO, init-value=0}, required-interface=VeCANR_b_Minute1_TLM_TO
      VeCANR_y_Minute2_TLM: nonqueued-receiver-com-spec{data-element=VeCANR_y_Minute2_TLM, handle-never-received=true, init-value=0}, required-interface=VeCANR_y_Minute2_TLM
      VeCANR_b_Minute2_TLM_TO: nonqueued-receiver-com-spec{data-element=VeCANR_b_Minute2_TLM_TO, init-value=0}, required-interface=VeCANR_b_Minute2_TLM_TO
      VeCANR_y_Month1_TLM: nonqueued-receiver-com-spec{data-element=VeCANR_y_Month1_TLM, handle-never-received=true, init-value=0}, required-interface=VeCANR_y_Month1_TLM
      VeCANR_b_Month1_TLM_TO: nonqueued-receiver-com-spec{data-element=VeCANR_b_Month1_TLM_TO, init-value=0}, required-interface=VeCANR_b_Month1_TLM_TO
      VeCANR_y_Month2_TLM: nonqueued-receiver-com-spec{data-element=VeCANR_y_Month2_TLM, handle-never-received=true, init-value=0}, required-interface=VeCANR_y_Month2_TLM
      VeCANR_b_Month2_TLM_TO: nonqueued-receiver-com-spec{data-element=VeCANR_b_Month2_TLM_TO, init-value=0}, required-interface=VeCANR_b_Month2_TLM_TO
      VeCANR_y_Year1_TLM: nonqueued-receiver-com-spec{data-element=VeCANR_y_Year1_TLM, handle-never-received=true, init-value=0}, required-interface=VeCANR_y_Year1_TLM
      VeCANR_b_Year1_TLM_TO: nonqueued-receiver-com-spec{data-element=VeCANR_b_Year1_TLM_TO, init-value=0}, required-interface=VeCANR_b_Year1_TLM_TO
      VeCANR_y_Year2_TLM: nonqueued-receiver-com-spec{data-element=VeCANR_y_Year2_TLM, handle-never-received=true, init-value=0}, required-interface=VeCANR_y_Year2_TLM
      VeCANR_b_Year2_TLM_TO: nonqueued-receiver-com-spec{data-element=VeCANR_b_Year2_TLM_TO, init-value=0}, required-interface=VeCANR_b_Year2_TLM_TO
      VeCANR_y_Year3_TLM: nonqueued-receiver-com-spec{data-element=VeCANR_y_Year3_TLM, handle-never-received=true, init-value=0}, required-interface=VeCANR_y_Year3_TLM
      VeCANR_b_Year3_TLM_TO: nonqueued-receiver-com-spec{data-element=VeCANR_b_Year3_TLM_TO, init-value=0}, required-interface=VeCANR_b_Year3_TLM_TO
      VeCANR_y_Year4_TLM: nonqueued-receiver-com-spec{data-element=VeCANR_y_Year4_TLM, handle-never-received=true, init-value=0}, required-interface=VeCANR_y_Year4_TLM
      VeCANR_b_Year4_TLM_TO: nonqueued-receiver-com-spec{data-element=VeCANR_b_Year4_TLM_TO, init-value=0}, required-interface=VeCANR_b_Year4_TLM_TO
      VeCANR_y_AUD_LVL: nonqueued-receiver-com-spec{data-element=VeCANR_y_AUD_LVL, handle-never-received=true, init-value=0}, required-interface=VeCANR_y_AUD_LVL
      VeCANR_b_AUD_LVL_TO: nonqueued-receiver-com-spec{data-element=VeCANR_b_AUD_LVL_TO, init-value=0}, required-interface=VeCANR_b_AUD_LVL_TO
      VeCANR_b_RACE_CLDWN_ON_OFF_REQ: variation-point={short-label=vpVeCANR_b_RACE_CLDWN_ON_OFF_REQ, sw-syscond=1}, nonqueued-receiver-com-spec{data-element=VeCANR_b_RACE_CLDWN_ON_OFF_REQ, handle-never-received=true, init-value=0}, required-interface=VeCANR_b_RACE_CLDWN_ON_OFF_REQ
      VeCANR_b_RACE_CLDWN_ON_OFF_REQ_TO: variation-point={short-label=vpVeCANR_b_RACE_CLDWN_ON_OFF_REQ_TO, sw-syscond=1}, nonqueued-receiver-com-spec{data-element=VeCANR_b_RACE_CLDWN_ON_OFF_REQ_TO, init-value=0}, required-interface=VeCANR_b_RACE_CLDWN_ON_OFF_REQ_TO
      VeCANR_e_Trns_DrvMdReq: nonqueued-receiver-com-spec{data-element=VeCANR_e_Trns_DrvMdReq, handle-never-received=true, init-value=0}, required-interface=VeCANR_e_Trns_DrvMdReq
      VeCANR_b_Trns_DrvMdReqTO: nonqueued-receiver-com-spec{data-element=VeCANR_b_Trns_DrvMdReqTO, init-value=0}, required-interface=VeCANR_b_Trns_DrvMdReqTO
      VeCANR_b_V2H_Mode_Req: nonqueued-receiver-com-spec{data-element=VeCANR_b_V2H_Mode_Req, handle-never-received=true, init-value=0}, required-interface=VeCANR_b_V2H_Mode_Req
      VeCANR_b_V2H_Mode_ReqTO: nonqueued-receiver-com-spec{data-element=VeCANR_b_V2H_Mode_ReqTO, init-value=0}, required-interface=VeCANR_b_V2H_Mode_ReqTO
      VeCANR_b_V2H_Req: nonqueued-receiver-com-spec{data-element=VeCANR_b_V2H_Req, handle-never-received=true, init-value=0}, required-interface=VeCANR_b_V2H_Req
      VeCANR_b_V2H_ReqTO: nonqueued-receiver-com-spec{data-element=VeCANR_b_V2H_ReqTO, init-value=0}, required-interface=VeCANR_b_V2H_ReqTO
      VeCANR_Pct_V2H_Reserve_Battery: nonqueued-receiver-com-spec{data-element=VeCANR_Pct_V2H_Reserve_Battery, handle-never-received=true, init-value=0}, required-interface=VeCANR_Pct_V2H_Reserve_Battery
      VeCANR_b_V2H_Reserve_BatteryTO: nonqueued-receiver-com-spec{data-element=VeCANR_b_V2H_Reserve_BatteryTO, init-value=0}, required-interface=VeCANR_b_V2H_Reserve_BatteryTO
      VeCANR_b_V2H_Submit: nonqueued-receiver-com-spec{data-element=VeCANR_b_V2H_Submit, handle-never-received=true, init-value=0}, required-interface=VeCANR_b_V2H_Submit
      VeCANR_b_V2H_SubmitTO: nonqueued-receiver-com-spec{data-element=VeCANR_b_V2H_SubmitTO, init-value=0}, required-interface=VeCANR_b_V2H_SubmitTO
      VeCANR_b_V2L_All_Req: nonqueued-receiver-com-spec{data-element=VeCANR_b_V2L_All_Req, handle-never-received=true, init-value=0}, required-interface=VeCANR_b_V2L_All_Req
      VeCANR_b_V2L_All_ReqTO: nonqueued-receiver-com-spec{data-element=VeCANR_b_V2L_All_ReqTO, init-value=0}, required-interface=VeCANR_b_V2L_All_ReqTO
      VeCANR_b_V2L_Frunk_Req: nonqueued-receiver-com-spec{data-element=VeCANR_b_V2L_Frunk_Req, handle-never-received=true, init-value=0}, required-interface=VeCANR_b_V2L_Frunk_Req
      VeCANR_b_V2L_Frunk_ReqTO: nonqueued-receiver-com-spec{data-element=VeCANR_b_V2L_Frunk_ReqTO, init-value=0}, required-interface=VeCANR_b_V2L_Frunk_ReqTO
      VeCANR_b_V2L_Mode_Req: nonqueued-receiver-com-spec{data-element=VeCANR_b_V2L_Mode_Req, handle-never-received=true, init-value=0}, required-interface=VeCANR_b_V2L_Mode_Req
      VeCANR_b_V2L_Mode_ReqTO: nonqueued-receiver-com-spec{data-element=VeCANR_b_V2L_Mode_ReqTO, init-value=0}, required-interface=VeCANR_b_V2L_Mode_ReqTO
      VeCANR_Pct_V2L_Reserve_Battery: nonqueued-receiver-com-spec{data-element=VeCANR_Pct_V2L_Reserve_Battery, handle-never-received=true, init-value=0}, required-interface=VeCANR_Pct_V2L_Reserve_Battery
      VeCANR_b_V2L_Reserve_BatteryTO: nonqueued-receiver-com-spec{data-element=VeCANR_b_V2L_Reserve_BatteryTO, init-value=0}, required-interface=VeCANR_b_V2L_Reserve_BatteryTO
      VeCANR_b_V2L_Submit: nonqueued-receiver-com-spec{data-element=VeCANR_b_V2L_Submit, handle-never-received=true, init-value=0}, required-interface=VeCANR_b_V2L_Submit
      VeCANR_b_V2L_SubmitTO: nonqueued-receiver-com-spec{data-element=VeCANR_b_V2L_SubmitTO, init-value=0}, required-interface=VeCANR_b_V2L_SubmitTO
      VeCANR_b_V2L_Trunk_Req: nonqueued-receiver-com-spec{data-element=VeCANR_b_V2L_Trunk_Req, handle-never-received=true, init-value=0}, required-interface=VeCANR_b_V2L_Trunk_Req
      VeCANR_b_V2L_Trunk_ReqTO: nonqueued-receiver-com-spec{data-element=VeCANR_b_V2L_Trunk_ReqTO, init-value=0}, required-interface=VeCANR_b_V2L_Trunk_ReqTO
      VeCANR_b_V2V_Mode_Req: nonqueued-receiver-com-spec{data-element=VeCANR_b_V2V_Mode_Req, handle-never-received=true, init-value=0}, required-interface=VeCANR_b_V2V_Mode_Req
      VeCANR_b_V2V_Mode_ReqTO: nonqueued-receiver-com-spec{data-element=VeCANR_b_V2V_Mode_ReqTO, init-value=0}, required-interface=VeCANR_b_V2V_Mode_ReqTO
      VeCANR_b_V2V_Req: nonqueued-receiver-com-spec{data-element=VeCANR_b_V2V_Req, handle-never-received=true, init-value=0}, required-interface=VeCANR_b_V2V_Req
      VeCANR_b_V2V_ReqTO: nonqueued-receiver-com-spec{data-element=VeCANR_b_V2V_ReqTO, init-value=0}, required-interface=VeCANR_b_V2V_ReqTO
      VeCANR_Pct_V2V_Reserve_Battery: nonqueued-receiver-com-spec{data-element=VeCANR_Pct_V2V_Reserve_Battery, handle-never-received=true, init-value=0}, required-interface=VeCANR_Pct_V2V_Reserve_Battery
      VeCANR_b_V2V_Reserve_BatteryTO: nonqueued-receiver-com-spec{data-element=VeCANR_b_V2V_Reserve_BatteryTO, init-value=0}, required-interface=VeCANR_b_V2V_Reserve_BatteryTO
      VeCANR_b_V2V_Submit: nonqueued-receiver-com-spec{data-element=VeCANR_b_V2V_Submit, handle-never-received=true, init-value=0}, required-interface=VeCANR_b_V2V_Submit
      VeCANR_b_V2V_SubmitTO: nonqueued-receiver-com-spec{data-element=VeCANR_b_V2V_SubmitTO, init-value=0}, required-interface=VeCANR_b_V2V_SubmitTO
      VeSR1B_y_AEB_Systemsts: nonqueued-receiver-com-spec{data-element=Value, handle-never-received=true, init-value=0}, required-interface=VeSR1B_y_AEB_Systemsts
      VeSR1B_y_AEB_Systemsts_SigSts: nonqueued-receiver-com-spec{data-element=Value, init-value=0}, required-interface=VeSR1B_y_AEB_Systemsts_SigSts
      VeSR1B_y_MRM_STATUS_FD3: nonqueued-receiver-com-spec{data-element=Value, handle-never-received=true, init-value=0}, required-interface=VeSR1B_y_MRM_STATUS_FD3
      VeSR1B_y_MRM_STATUS_FD3_SigSts: nonqueued-receiver-com-spec{data-element=Value, init-value=0}, required-interface=VeSR1B_y_MRM_STATUS_FD3_SigSts
      VeSR1B_y_TSRSts: nonqueued-receiver-com-spec{data-element=Value, handle-never-received=true, init-value=0}, required-interface=VeSR1B_y_TSRSts
      VeSR1B_y_TSRSts_SigSts: nonqueued-receiver-com-spec{data-element=Value, init-value=0}, required-interface=VeSR1B_y_TSRSts_SigSts
      VeSR1B_y_MRM_STATUS_C2: nonqueued-receiver-com-spec{data-element=Value, handle-never-received=true, init-value=0}, required-interface=VeSR1B_y_MRM_STATUS_C2
      VeSR1B_y_MRM_STATUS_C2_SigSts: nonqueued-receiver-com-spec{data-element=Value, init-value=0}, required-interface=VeSR1B_y_MRM_STATUS_C2_SigSts
      VeSR1B_y_APCM_Stat_FD3: nonqueued-receiver-com-spec{data-element=Value, handle-never-received=true, init-value=0}, required-interface=VeSR1B_y_APCM_Stat_FD3
      VeSR1B_y_APCM_Stat_FD3_SigSts: nonqueued-receiver-com-spec{data-element=Value, init-value=0}, required-interface=VeSR1B_y_APCM_Stat_FD3_SigSts
      VeSR1B_b_PRNDFailSts_FD3: nonqueued-receiver-com-spec{data-element=Value, handle-never-received=true, init-value=0}, required-interface=VeSR1B_b_PRNDFailSts_FD3
      VeSR1B_y_PRNDFailSts_FD3_SigSts: nonqueued-receiver-com-spec{data-element=Value, init-value=0}, required-interface=VeSR1B_y_PRNDFailSts_FD3_SigSts
      VeSR1B_b_PRNDdisplayFailSts_FD3: nonqueued-receiver-com-spec{data-element=Value, handle-never-received=true, init-value=0}, required-interface=VeSR1B_b_PRNDdisplayFailSts_FD3
      VeSR1B_y_PRNDdisplayFailSts_FD3_SigSts: nonqueued-receiver-com-spec{data-element=Value, init-value=0}, required-interface=VeSR1B_y_PRNDdisplayFailSts_FD3_SigSts
      VeSR1B_y_ShiftLeverPositionReq_FD3: nonqueued-receiver-com-spec{data-element=Value, handle-never-received=true, init-value=0}, required-interface=VeSR1B_y_ShiftLeverPositionReq_FD3
      VeSR1B_y_ShiftLeverPositionReq_FD3_SigSts: nonqueued-receiver-com-spec{data-element=Value, init-value=0}, required-interface=VeSR1B_y_ShiftLeverPositionReq_FD3_SigSts
      VeSR1B_b_ShiftLockFailSts: nonqueued-receiver-com-spec{data-element=Value, handle-never-received=true, init-value=0}, required-interface=VeSR1B_b_ShiftLockFailSts
      VeSR1B_y_ShiftLockFailSts_SigSts: nonqueued-receiver-com-spec{data-element=Value, init-value=0}, required-interface=VeSR1B_y_ShiftLockFailSts_SigSts
      VeSR1B_y_CmdIgnSts: nonqueued-receiver-com-spec{data-element=Value, handle-never-received=true, init-value=0}, required-interface=VeSR1B_y_CmdIgnSts
      VeSR1B_y_CmdIgnSts_SigSts: nonqueued-receiver-com-spec{data-element=Value, init-value=0}, required-interface=VeSR1B_y_CmdIgnSts_SigSts
      VeSR1B_b_CompressorACReqSts: nonqueued-receiver-com-spec{data-element=Value, handle-never-received=true, init-value=0}, required-interface=VeSR1B_b_CompressorACReqSts
      VeSR1B_y_CompressorACReqSts_SigSts: nonqueued-receiver-com-spec{data-element=Value, init-value=0}, required-interface=VeSR1B_y_CompressorACReqSts_SigSts
      VeSR1B_b_DAY_LGT_MD: nonqueued-receiver-com-spec{data-element=Value, handle-never-received=true, init-value=0}, required-interface=VeSR1B_b_DAY_LGT_MD
      VeSR1B_y_DAY_LGT_MD_SigSts: nonqueued-receiver-com-spec{data-element=Value, init-value=0}, required-interface=VeSR1B_y_DAY_LGT_MD_SigSts
      VeSR1B_b_PN14_LS_Actv: nonqueued-receiver-com-spec{data-element=Value, handle-never-received=true, init-value=0}, required-interface=VeSR1B_b_PN14_LS_Actv
      VeSR1B_y_PN14_LS_Actv_SigSts: nonqueued-receiver-com-spec{data-element=Value, init-value=0}, required-interface=VeSR1B_y_PN14_LS_Actv_SigSts
      VeSR1B_y_StopStartClimateInfo: nonqueued-receiver-com-spec{data-element=Value, handle-never-received=true, init-value=0}, required-interface=VeSR1B_y_StopStartClimateInfo
      VeSR1B_y_StopStartClimateInfo_SigSts: nonqueued-receiver-com-spec{data-element=Value, init-value=0}, required-interface=VeSR1B_y_StopStartClimateInfo_SigSts
      VeSR1B_b_DrvSeatDPFaultSts: nonqueued-receiver-com-spec{data-element=Value, handle-never-received=true, init-value=0}, required-interface=VeSR1B_b_DrvSeatDPFaultSts
      VeSR1B_y_DrvSeatDPFaultSts_SigSts: nonqueued-receiver-com-spec{data-element=Value, init-value=0}, required-interface=VeSR1B_y_DrvSeatDPFaultSts_SigSts
      VeSR1B_y_DrvSeatDPSts: nonqueued-receiver-com-spec{data-element=Value, handle-never-received=true, init-value=0}, required-interface=VeSR1B_y_DrvSeatDPSts
      VeSR1B_y_DrvSeatDPSts_SigSts: nonqueued-receiver-com-spec{data-element=Value, init-value=0}, required-interface=VeSR1B_y_DrvSeatDPSts_SigSts
      VeSR1B_y_GlobDrvMdRq_BCM: nonqueued-receiver-com-spec{data-element=Value, handle-never-received=true, init-value=0}, required-interface=VeSR1B_y_GlobDrvMdRq_BCM
      VeSR1B_y_GlobDrvMdRq_BCM_SigSts: nonqueued-receiver-com-spec{data-element=Value, init-value=0}, required-interface=VeSR1B_y_GlobDrvMdRq_BCM_SigSts
      VeSR1B_y_Launch_Hard_Btn: variation-point={short-label=vpVeSR1B_y_Launch_Hard_Btn, sw-syscond=1}, nonqueued-receiver-com-spec{data-element=Value, handle-never-received=true, init-value=0}, required-interface=VeSR1B_y_Launch_Hard_Btn
      VeSR1B_y_Launch_Hard_Btn_SigSts: variation-point={short-label=vpVeSR1B_y_Launch_Hard_Btn_SigSts, sw-syscond=1}, nonqueued-receiver-com-spec{data-element=Value, init-value=0}, required-interface=VeSR1B_y_Launch_Hard_Btn_SigSts
      VeSR1B_y_Left_Button_BCM: nonqueued-receiver-com-spec{data-element=Value, handle-never-received=true, init-value=0}, required-interface=VeSR1B_y_Left_Button_BCM
      VeSR1B_y_Left_Button_BCM_SigSts: nonqueued-receiver-com-spec{data-element=Value, init-value=0}, required-interface=VeSR1B_y_Left_Button_BCM_SigSts
      VeSR1B_y_PowerShot_BCM: variation-point={short-label=vpVeSR1B_y_PowerShot_BCM, sw-syscond=1}, nonqueued-receiver-com-spec{data-element=Value, handle-never-received=true, init-value=0}, required-interface=VeSR1B_y_PowerShot_BCM
      VeSR1B_y_PowerShot_BCM_SigSts: variation-point={short-label=vpVeSR1B_y_PowerShot_BCM_SigSts, sw-syscond=1}, nonqueued-receiver-com-spec{data-element=Value, init-value=0}, required-interface=VeSR1B_y_PowerShot_BCM_SigSts
      VeSR1B_y_PreCondCabinSts: nonqueued-receiver-com-spec{data-element=Value, handle-never-received=true, init-value=0}, required-interface=VeSR1B_y_PreCondCabinSts
      VeSR1B_y_PreCondCabinSts_SigSts: nonqueued-receiver-com-spec{data-element=Value, init-value=0}, required-interface=VeSR1B_y_PreCondCabinSts_SigSts
      VeSR1B_y_RearHVACBlower_Sts: nonqueued-receiver-com-spec{data-element=Value, handle-never-received=true, init-value=0}, required-interface=VeSR1B_y_RearHVACBlower_Sts
      VeSR1B_y_RearHVACBlower_Sts_SigSts: nonqueued-receiver-com-spec{data-element=Value, init-value=0}, required-interface=VeSR1B_y_RearHVACBlower_Sts_SigSts
      VeSR1B_y_Right_Button_BCM: nonqueued-receiver-com-spec{data-element=Value, handle-never-received=true, init-value=0}, required-interface=VeSR1B_y_Right_Button_BCM
      VeSR1B_y_Right_Button_BCM_SigSts: nonqueued-receiver-com-spec{data-element=Value, init-value=0}, required-interface=VeSR1B_y_Right_Button_BCM_SigSts
      VeSR1B_y_Switch_2WD_Rq: variation-point={short-label=vpVeSR1B_y_Switch_2WD_Rq, sw-syscond=1}, nonqueued-receiver-com-spec{data-element=Value, handle-never-received=true, init-value=0}, required-interface=VeSR1B_y_Switch_2WD_Rq
      VeSR1B_y_Switch_2WD_Rq_SigSts: variation-point={short-label=vpVeSR1B_y_Switch_2WD_Rq_SigSts, sw-syscond=1}, nonqueued-receiver-com-spec{data-element=Value, init-value=0}, required-interface=VeSR1B_y_Switch_2WD_Rq_SigSts
      VeSR1B_y_TerrModIntrfcButnBCM: variation-point={short-label=vpVeSR1B_y_TerrModIntrfcButnBCM, sw-syscond=1}, nonqueued-receiver-com-spec{data-element=Value, handle-never-received=true, init-value=0}, required-interface=VeSR1B_y_TerrModIntrfcButnBCM
      VeSR1B_y_TerrModIntrfcButnBCM_SigSts: variation-point={short-label=vpVeSR1B_y_TerrModIntrfcButnBCM_SigSts, sw-syscond=1}, nonqueued-receiver-com-spec{data-element=Value, init-value=0}, required-interface=VeSR1B_y_TerrModIntrfcButnBCM_SigSts
      VeSR1B_y_TerrainSwStat: nonqueued-receiver-com-spec{data-element=Value, handle-never-received=true, init-value=0}, required-interface=VeSR1B_y_TerrainSwStat
      VeSR1B_y_TerrainSwStat_SigSts: nonqueued-receiver-com-spec{data-element=Value, init-value=0}, required-interface=VeSR1B_y_TerrainSwStat_SigSts
      VeSR1B_b_ACC_On: nonqueued-receiver-com-spec{data-element=Value, handle-never-received=true, init-value=0}, required-interface=VeSR1B_b_ACC_On
      VeSR1B_y_ACC_On_SigSts: nonqueued-receiver-com-spec{data-element=Value, init-value=0}, required-interface=VeSR1B_y_ACC_On_SigSts
      VeSR1B_b_AcceleratorSts: nonqueued-receiver-com-spec{data-element=Value, handle-never-received=true, init-value=0}, required-interface=VeSR1B_b_AcceleratorSts
      VeSR1B_y_AcceleratorSts_SigSts: nonqueued-receiver-com-spec{data-element=Value, init-value=0}, required-interface=VeSR1B_y_AcceleratorSts_SigSts
      VeSR1B_b_CruiseControlFailSts: nonqueued-receiver-com-spec{data-element=Value, handle-never-received=true, init-value=0}, required-interface=VeSR1B_b_CruiseControlFailSts
      VeSR1B_y_CruiseControlFailSts_SigSts: nonqueued-receiver-com-spec{data-element=Value, init-value=0}, required-interface=VeSR1B_y_CruiseControlFailSts_SigSts
      VeSR1B_b_CruiseControlOnOffSts: nonqueued-receiver-com-spec{data-element=Value, handle-never-received=true, init-value=0}, required-interface=VeSR1B_b_CruiseControlOnOffSts
      VeSR1B_y_CruiseControlOnOffSts_SigSts: nonqueued-receiver-com-spec{data-element=Value, init-value=0}, required-interface=VeSR1B_y_CruiseControlOnOffSts_SigSts
      VeSR1B_b_CrusCnclSwitch: nonqueued-receiver-com-spec{data-element=Value, handle-never-received=true, init-value=0}, required-interface=VeSR1B_b_CrusCnclSwitch
      VeSR1B_y_CrusCnclSwitch_SigSts: nonqueued-receiver-com-spec{data-element=Value, init-value=0}, required-interface=VeSR1B_y_CrusCnclSwitch_SigSts
      VeSR1B_b_DeceleratorSts: nonqueued-receiver-com-spec{data-element=Value, handle-never-received=true, init-value=0}, required-interface=VeSR1B_b_DeceleratorSts
      VeSR1B_y_DeceleratorSts_SigSts: nonqueued-receiver-com-spec{data-element=Value, init-value=0}, required-interface=VeSR1B_y_DeceleratorSts_SigSts
      VeSR1B_b_ResumeSwitch: nonqueued-receiver-com-spec{data-element=Value, handle-never-received=true, init-value=0}, required-interface=VeSR1B_b_ResumeSwitch
      VeSR1B_y_ResumeSwitch_SigSts: nonqueued-receiver-com-spec{data-element=Value, init-value=0}, required-interface=VeSR1B_y_ResumeSwitch_SigSts
      VeSR1B_b_SpeedLimiterOnOffSts: nonqueued-receiver-com-spec{data-element=Value, handle-never-received=true, init-value=0}, required-interface=VeSR1B_b_SpeedLimiterOnOffSts
      VeSR1B_y_SpeedLimiterOnOffSts_SigSts: nonqueued-receiver-com-spec{data-element=Value, init-value=0}, required-interface=VeSR1B_y_SpeedLimiterOnOffSts_SigSts
      VeSR1B_U_BonnetAjarRawValSts_8: nonqueued-receiver-com-spec{data-element=Value, handle-never-received=true, init-value=0}, required-interface=VeSR1B_U_BonnetAjarRawValSts_8
      VeSR1B_y_BonnetAjarRawValSts_8_SigSts: nonqueued-receiver-com-spec{data-element=Value, init-value=0}, required-interface=VeSR1B_y_BonnetAjarRawValSts_8_SigSts
      VeSR1B_b_DRV_DR_UNLOCKING: nonqueued-receiver-com-spec{data-element=Value, handle-never-received=true, init-value=0}, required-interface=VeSR1B_b_DRV_DR_UNLOCKING
      VeSR1B_y_DRV_DR_UNLOCKING_SigSts: nonqueued-receiver-com-spec{data-element=Value, init-value=0}, required-interface=VeSR1B_y_DRV_DR_UNLOCKING_SigSts
      VeSR1B_y_KeyInIgnSts: nonqueued-receiver-com-spec{data-element=Value, handle-never-received=true, init-value=0}, required-interface=VeSR1B_y_KeyInIgnSts
      VeSR1B_y_KeyInIgnSts_SigSts: nonqueued-receiver-com-spec{data-element=Value, init-value=0}, required-interface=VeSR1B_y_KeyInIgnSts_SigSts
      VeSR1B_b_RemStActvSts_R: nonqueued-receiver-com-spec{data-element=Value, handle-never-received=true, init-value=0}, required-interface=VeSR1B_b_RemStActvSts_R
      VeSR1B_y_RemStActvSts_R_SigSts: nonqueued-receiver-com-spec{data-element=Value, init-value=0}, required-interface=VeSR1B_y_RemStActvSts_R_SigSts
      VeSR1B_b_SCCActvSts: nonqueued-receiver-com-spec{data-element=Value, handle-never-received=true, init-value=0}, required-interface=VeSR1B_b_SCCActvSts
      VeSR1B_y_SCCActvSts_SigSts: nonqueued-receiver-com-spec{data-element=Value, init-value=0}, required-interface=VeSR1B_y_SCCActvSts_SigSts
      VeSR1B_b_FL_HS_STATFailSts: nonqueued-receiver-com-spec{data-element=Value, handle-never-received=true, init-value=0}, required-interface=VeSR1B_b_FL_HS_STATFailSts
      VeSR1B_y_FL_HS_STATFailSts_SigSts: nonqueued-receiver-com-spec{data-element=Value, init-value=0}, required-interface=VeSR1B_y_FL_HS_STATFailSts_SigSts
      VeSR1B_y_FL_HS_STATSts: nonqueued-receiver-com-spec{data-element=Value, handle-never-received=true, init-value=0}, required-interface=VeSR1B_y_FL_HS_STATSts
      VeSR1B_y_FL_HS_STATSts_SigSts: nonqueued-receiver-com-spec{data-element=Value, init-value=0}, required-interface=VeSR1B_y_FL_HS_STATSts_SigSts
      VeSR1B_b_FR_HS_STATFailSts: nonqueued-receiver-com-spec{data-element=Value, handle-never-received=true, init-value=0}, required-interface=VeSR1B_b_FR_HS_STATFailSts
      VeSR1B_y_FR_HS_STATFailSts_SigSts: nonqueued-receiver-com-spec{data-element=Value, init-value=0}, required-interface=VeSR1B_y_FR_HS_STATFailSts_SigSts
      VeSR1B_y_FR_HS_STATSts: nonqueued-receiver-com-spec{data-element=Value, handle-never-received=true, init-value=0}, required-interface=VeSR1B_y_FR_HS_STATSts
      VeSR1B_y_FR_HS_STATSts_SigSts: nonqueued-receiver-com-spec{data-element=Value, init-value=0}, required-interface=VeSR1B_y_FR_HS_STATSts_SigSts
      VeSR1B_y_HiBmLvr_Stat: nonqueued-receiver-com-spec{data-element=Value, handle-never-received=true, init-value=0}, required-interface=VeSR1B_y_HiBmLvr_Stat
      VeSR1B_y_HiBmLvr_Stat_SigSts: nonqueued-receiver-com-spec{data-element=Value, init-value=0}, required-interface=VeSR1B_y_HiBmLvr_Stat_SigSts
      VeSR1B_y_AHP_EnblReq: nonqueued-receiver-com-spec{data-element=Value, handle-never-received=true, init-value=0}, required-interface=VeSR1B_y_AHP_EnblReq
      VeSR1B_y_AHP_EnblReq_SigSts: nonqueued-receiver-com-spec{data-element=Value, init-value=0}, required-interface=VeSR1B_y_AHP_EnblReq_SigSts
      VeSR1B_b_DEFROST_SEL: nonqueued-receiver-com-spec{data-element=Value, handle-never-received=true, init-value=0}, required-interface=VeSR1B_b_DEFROST_SEL
      VeSR1B_y_DEFROST_SEL_SigSts: nonqueued-receiver-com-spec{data-element=Value, init-value=0}, required-interface=VeSR1B_y_DEFROST_SEL_SigSts
      VeSR1B_Pct_DRV_TEMP_DR_POS: nonqueued-receiver-com-spec{data-element=Value, handle-never-received=true, init-value=0}, required-interface=VeSR1B_Pct_DRV_TEMP_DR_POS
      VeSR1B_y_DRV_TEMP_DR_POS_SigSts: nonqueued-receiver-com-spec{data-element=Value, init-value=0}, required-interface=VeSR1B_y_DRV_TEMP_DR_POS_SigSts
      VeSR1B_T_EvapTempTar: nonqueued-receiver-com-spec{data-element=Value, handle-never-received=true, init-value=0}, required-interface=VeSR1B_T_EvapTempTar
      VeSR1B_y_EvapTempTar_SigSts: nonqueued-receiver-com-spec{data-element=Value, init-value=0}, required-interface=VeSR1B_y_EvapTempTar_SigSts
      VeSR1B_b_HAS_OnOffSts: nonqueued-receiver-com-spec{data-element=Value, handle-never-received=true, init-value=0}, required-interface=VeSR1B_b_HAS_OnOffSts
      VeSR1B_y_HAS_OnOffSts_SigSts: nonqueued-receiver-com-spec{data-element=Value, init-value=0}, required-interface=VeSR1B_y_HAS_OnOffSts_SigSts
      VeSR1B_Pct_HVAC_Blwr_Perct: nonqueued-receiver-com-spec{data-element=Value, handle-never-received=true, init-value=0}, required-interface=VeSR1B_Pct_HVAC_Blwr_Perct
      VeSR1B_y_HVAC_Blwr_Perct_SigSts: nonqueued-receiver-com-spec{data-element=Value, init-value=0}, required-interface=VeSR1B_y_HVAC_Blwr_Perct_SigSts
      VeSR1B_T_HtrCorTmp_InTgt: nonqueued-receiver-com-spec{data-element=Value, handle-never-received=true, init-value=0}, required-interface=VeSR1B_T_HtrCorTmp_InTgt
      VeSR1B_y_HtrCorTmp_InTgt_SigSts: nonqueued-receiver-com-spec{data-element=Value, init-value=0}, required-interface=VeSR1B_y_HtrCorTmp_InTgt_SigSts
      VeSR1B_Pct_PAS_TEMP_DR_POS: nonqueued-receiver-com-spec{data-element=Value, handle-never-received=true, init-value=0}, required-interface=VeSR1B_Pct_PAS_TEMP_DR_POS
      VeSR1B_y_PAS_TEMP_DR_POS_SigSts: nonqueued-receiver-com-spec{data-element=Value, init-value=0}, required-interface=VeSR1B_y_PAS_TEMP_DR_POS_SigSts
      VeSR1B_Pct_RearAirHtrPwrTgt: nonqueued-receiver-com-spec{data-element=Value, handle-never-received=true, init-value=0}, required-interface=VeSR1B_Pct_RearAirHtrPwrTgt
      VeSR1B_y_RearAirHtrPwrTgt_SigSts: nonqueued-receiver-com-spec{data-element=Value, init-value=0}, required-interface=VeSR1B_y_RearAirHtrPwrTgt_SigSts
      VeSR1B_y_Tri_Level_HSW_StatSts: nonqueued-receiver-com-spec{data-element=Value, handle-never-received=true, init-value=0}, required-interface=VeSR1B_y_Tri_Level_HSW_StatSts
      VeSR1B_y_Tri_Level_HSW_StatSts_SigSts: nonqueued-receiver-com-spec{data-element=Value, init-value=0}, required-interface=VeSR1B_y_Tri_Level_HSW_StatSts_SigSts
      VeSR1B_T_VEH_INT_TEMP: nonqueued-receiver-com-spec{data-element=Value, handle-never-received=true, init-value=0}, required-interface=VeSR1B_T_VEH_INT_TEMP
      VeSR1B_y_VEH_INT_TEMP_SigSts: nonqueued-receiver-com-spec{data-element=Value, init-value=0}, required-interface=VeSR1B_y_VEH_INT_TEMP_SigSts
      VeSR1B_y_EBL_Stat: nonqueued-receiver-com-spec{data-element=Value, handle-never-received=true, init-value=0}, required-interface=VeSR1B_y_EBL_Stat
      VeSR1B_y_EBL_Stat_SigSts: nonqueued-receiver-com-spec{data-element=Value, init-value=0}, required-interface=VeSR1B_y_EBL_Stat_SigSts
      VeSR1B_T_EVAP_TEMP_P1C: nonqueued-receiver-com-spec{data-element=Value, handle-never-received=true, init-value=0}, required-interface=VeSR1B_T_EVAP_TEMP_P1C
      VeSR1B_y_EVAP_TEMP_P1C_SigSts: nonqueued-receiver-com-spec{data-element=Value, init-value=0}, required-interface=VeSR1B_y_EVAP_TEMP_P1C_SigSts
      VeSR1B_U_ExtTemperatureAD_Volt: nonqueued-receiver-com-spec{data-element=Value, handle-never-received=true, init-value=0}, required-interface=VeSR1B_U_ExtTemperatureAD_Volt
      VeSR1B_y_ExtTemperatureAD_Volt_SigSts: nonqueued-receiver-com-spec{data-element=Value, init-value=0}, required-interface=VeSR1B_y_ExtTemperatureAD_Volt_SigSts
      VeSR1B_b_FL_VS_STATFailSts: nonqueued-receiver-com-spec{data-element=Value, handle-never-received=true, init-value=0}, required-interface=VeSR1B_b_FL_VS_STATFailSts
      VeSR1B_y_FL_VS_STATFailSts_SigSts: nonqueued-receiver-com-spec{data-element=Value, init-value=0}, required-interface=VeSR1B_y_FL_VS_STATFailSts_SigSts
      VeSR1B_y_FL_VS_STATSts: nonqueued-receiver-com-spec{data-element=Value, handle-never-received=true, init-value=0}, required-interface=VeSR1B_y_FL_VS_STATSts
      VeSR1B_y_FL_VS_STATSts_SigSts: nonqueued-receiver-com-spec{data-element=Value, init-value=0}, required-interface=VeSR1B_y_FL_VS_STATSts_SigSts
      VeSR1B_b_FR_VS_STATFailSts: nonqueued-receiver-com-spec{data-element=Value, handle-never-received=true, init-value=0}, required-interface=VeSR1B_b_FR_VS_STATFailSts
      VeSR1B_y_FR_VS_STATFailSts_SigSts: nonqueued-receiver-com-spec{data-element=Value, init-value=0}, required-interface=VeSR1B_y_FR_VS_STATFailSts_SigSts
      VeSR1B_y_FR_VS_STATSts: nonqueued-receiver-com-spec{data-element=Value, handle-never-received=true, init-value=0}, required-interface=VeSR1B_y_FR_VS_STATSts
      VeSR1B_y_FR_VS_STATSts_SigSts: nonqueued-receiver-com-spec{data-element=Value, init-value=0}, required-interface=VeSR1B_y_FR_VS_STATSts_SigSts
      VeSR1B_b_HSW_StatFailSts: nonqueued-receiver-com-spec{data-element=Value, handle-never-received=true, init-value=0}, required-interface=VeSR1B_b_HSW_StatFailSts
      VeSR1B_y_HSW_StatFailSts_SigSts: nonqueued-receiver-com-spec{data-element=Value, init-value=0}, required-interface=VeSR1B_y_HSW_StatFailSts_SigSts
      VeSR1B_y_RL_HS_STAT: nonqueued-receiver-com-spec{data-element=Value, handle-never-received=true, init-value=0}, required-interface=VeSR1B_y_RL_HS_STAT
      VeSR1B_y_RL_HS_STAT_SigSts: nonqueued-receiver-com-spec{data-element=Value, init-value=0}, required-interface=VeSR1B_y_RL_HS_STAT_SigSts
      VeSR1B_b_RL_HS_STATFailSts: nonqueued-receiver-com-spec{data-element=Value, handle-never-received=true, init-value=0}, required-interface=VeSR1B_b_RL_HS_STATFailSts
      VeSR1B_y_RL_HS_STATFailSts_SigSts: nonqueued-receiver-com-spec{data-element=Value, init-value=0}, required-interface=VeSR1B_y_RL_HS_STATFailSts_SigSts
      VeSR1B_y_RL_VS_STAT: nonqueued-receiver-com-spec{data-element=Value, handle-never-received=true, init-value=0}, required-interface=VeSR1B_y_RL_VS_STAT
      VeSR1B_y_RL_VS_STAT_SigSts: nonqueued-receiver-com-spec{data-element=Value, init-value=0}, required-interface=VeSR1B_y_RL_VS_STAT_SigSts
      VeSR1B_b_RL_VS_STATFailSts: nonqueued-receiver-com-spec{data-element=Value, handle-never-received=true, init-value=0}, required-interface=VeSR1B_b_RL_VS_STATFailSts
      VeSR1B_y_RL_VS_STATFailSts_SigSts: nonqueued-receiver-com-spec{data-element=Value, init-value=0}, required-interface=VeSR1B_y_RL_VS_STATFailSts_SigSts
      VeSR1B_y_RR_HS_STAT: nonqueued-receiver-com-spec{data-element=Value, handle-never-received=true, init-value=0}, required-interface=VeSR1B_y_RR_HS_STAT
      VeSR1B_y_RR_HS_STAT_SigSts: nonqueued-receiver-com-spec{data-element=Value, init-value=0}, required-interface=VeSR1B_y_RR_HS_STAT_SigSts
      VeSR1B_b_RR_HS_STATFailSts: nonqueued-receiver-com-spec{data-element=Value, handle-never-received=true, init-value=0}, required-interface=VeSR1B_b_RR_HS_STATFailSts
      VeSR1B_y_RR_HS_STATFailSts_SigSts: nonqueued-receiver-com-spec{data-element=Value, init-value=0}, required-interface=VeSR1B_y_RR_HS_STATFailSts_SigSts
      VeSR1B_y_RR_VS_STAT: nonqueued-receiver-com-spec{data-element=Value, handle-never-received=true, init-value=0}, required-interface=VeSR1B_y_RR_VS_STAT
      VeSR1B_y_RR_VS_STAT_SigSts: nonqueued-receiver-com-spec{data-element=Value, init-value=0}, required-interface=VeSR1B_y_RR_VS_STAT_SigSts
      VeSR1B_b_RR_VS_STATFailSts: nonqueued-receiver-com-spec{data-element=Value, handle-never-received=true, init-value=0}, required-interface=VeSR1B_b_RR_VS_STATFailSts
      VeSR1B_y_RR_VS_STATFailSts_SigSts: nonqueued-receiver-com-spec{data-element=Value, init-value=0}, required-interface=VeSR1B_y_RR_VS_STATFailSts_SigSts
      VeSR1B_y_DriverDoorOnOffSts: nonqueued-receiver-com-spec{data-element=Value, handle-never-received=true, init-value=0}, required-interface=VeSR1B_y_DriverDoorOnOffSts
      VeSR1B_y_DriverDoorOnOffSts_SigSts: nonqueued-receiver-com-spec{data-element=Value, init-value=0}, required-interface=VeSR1B_y_DriverDoorOnOffSts_SigSts
      VeSR1B_b_BonnetSts: nonqueued-receiver-com-spec{data-element=Value, handle-never-received=true, init-value=0}, required-interface=VeSR1B_b_BonnetSts
      VeSR1B_y_BonnetSts_SigSts: nonqueued-receiver-com-spec{data-element=Value, init-value=0}, required-interface=VeSR1B_y_BonnetSts_SigSts
      VeSR1B_y_DoorLockLastElSts: nonqueued-receiver-com-spec{data-element=Value, handle-never-received=true, init-value=0}, required-interface=VeSR1B_y_DoorLockLastElSts
      VeSR1B_y_DoorLockLastElSts_SigSts: nonqueued-receiver-com-spec{data-element=Value, init-value=0}, required-interface=VeSR1B_y_DoorLockLastElSts_SigSts
      VeSR1B_b_DriverDoorSts: nonqueued-receiver-com-spec{data-element=Value, handle-never-received=true, init-value=0}, required-interface=VeSR1B_b_DriverDoorSts
      VeSR1B_y_DriverDoorSts_SigSts: nonqueued-receiver-com-spec{data-element=Value, init-value=0}, required-interface=VeSR1B_y_DriverDoorSts_SigSts
      VeSR1B_b_LHRDoorSts: nonqueued-receiver-com-spec{data-element=Value, handle-never-received=true, init-value=0}, required-interface=VeSR1B_b_LHRDoorSts
      VeSR1B_y_LHRDoorSts_SigSts: nonqueued-receiver-com-spec{data-element=Value, init-value=0}, required-interface=VeSR1B_y_LHRDoorSts_SigSts
      VeSR1B_b_ParkBrakeSts: nonqueued-receiver-com-spec{data-element=Value, handle-never-received=true, init-value=0}, required-interface=VeSR1B_b_ParkBrakeSts
      VeSR1B_y_ParkBrakeSts_SigSts: nonqueued-receiver-com-spec{data-element=Value, init-value=0}, required-interface=VeSR1B_y_ParkBrakeSts_SigSts
      VeSR1B_y_PowerModeSts: nonqueued-receiver-com-spec{data-element=Value, handle-never-received=true, init-value=0}, required-interface=VeSR1B_y_PowerModeSts
      VeSR1B_y_PowerModeSts_SigSts: nonqueued-receiver-com-spec{data-element=Value, init-value=0}, required-interface=VeSR1B_y_PowerModeSts_SigSts
      VeSR1B_b_PsngrDoorSts: nonqueued-receiver-com-spec{data-element=Value, handle-never-received=true, init-value=0}, required-interface=VeSR1B_b_PsngrDoorSts
      VeSR1B_y_PsngrDoorSts_SigSts: nonqueued-receiver-com-spec{data-element=Value, init-value=0}, required-interface=VeSR1B_y_PsngrDoorSts_SigSts
      VeSR1B_b_RHRDoorSts: nonqueued-receiver-com-spec{data-element=Value, handle-never-received=true, init-value=0}, required-interface=VeSR1B_b_RHRDoorSts
      VeSR1B_y_RHRDoorSts_SigSts: nonqueued-receiver-com-spec{data-element=Value, init-value=0}, required-interface=VeSR1B_y_RHRDoorSts_SigSts
      VeSR1B_b_RHatchSts: nonqueued-receiver-com-spec{data-element=Value, handle-never-received=true, init-value=0}, required-interface=VeSR1B_b_RHatchSts
      VeSR1B_y_RHatchSts_SigSts: nonqueued-receiver-com-spec{data-element=Value, init-value=0}, required-interface=VeSR1B_y_RHatchSts_SigSts
      VeSR1B_b_RearFogLightSts: nonqueued-receiver-com-spec{data-element=Value, handle-never-received=true, init-value=0}, required-interface=VeSR1B_b_RearFogLightSts
      VeSR1B_y_RearFogLightSts_SigSts: nonqueued-receiver-com-spec{data-element=Value, init-value=0}, required-interface=VeSR1B_y_RearFogLightSts_SigSts
      VeSR1B_M_BrkTrq_FD3: nonqueued-receiver-com-spec{data-element=Value, handle-never-received=true, init-value=0}, required-interface=VeSR1B_M_BrkTrq_FD3
      VeSR1B_y_BrkTrq_FD3_SigSts: nonqueued-receiver-com-spec{data-element=Value, init-value=0}, required-interface=VeSR1B_y_BrkTrq_FD3_SigSts
      VeSR1B_M_BrkTrq_Driver_FD3: nonqueued-receiver-com-spec{data-element=Value, handle-never-received=true, init-value=0}, required-interface=VeSR1B_M_BrkTrq_Driver_FD3
      VeSR1B_y_BrkTrq_Driver_FD3_SigSts: nonqueued-receiver-com-spec{data-element=Value, init-value=0}, required-interface=VeSR1B_y_BrkTrq_Driver_FD3_SigSts
      VeSR1B_b_Brk_Thermdl: variation-point={short-label=vpVeSR1B_b_Brk_Thermdl, sw-syscond=1}, nonqueued-receiver-com-spec{data-element=Value, handle-never-received=true, init-value=0}, required-interface=VeSR1B_b_Brk_Thermdl
      VeSR1B_y_Brk_Thermdl_SigSts: variation-point={short-label=vpVeSR1B_y_Brk_Thermdl_SigSts, sw-syscond=1}, nonqueued-receiver-com-spec{data-element=Value, init-value=0}, required-interface=VeSR1B_y_Brk_Thermdl_SigSts
      VeSR1B_y_ExternalBrkReqsDsbld: nonqueued-receiver-com-spec{data-element=Value, handle-never-received=true, init-value=0}, required-interface=VeSR1B_y_ExternalBrkReqsDsbld
      VeSR1B_y_ExternalBrkReqsDsbld_SigSts: nonqueued-receiver-com-spec{data-element=Value, init-value=0}, required-interface=VeSR1B_y_ExternalBrkReqsDsbld_SigSts
      VeSR1B_y_HILL_DES_STAT: nonqueued-receiver-com-spec{data-element=Value, handle-never-received=true, init-value=0}, required-interface=VeSR1B_y_HILL_DES_STAT
      VeSR1B_y_HILL_DES_STAT_SigSts: nonqueued-receiver-com-spec{data-element=Value, init-value=0}, required-interface=VeSR1B_y_HILL_DES_STAT_SigSts
      VeSR1B_y_SelectSpdSts: nonqueued-receiver-com-spec{data-element=Value, handle-never-received=true, init-value=0}, required-interface=VeSR1B_y_SelectSpdSts
      VeSR1B_y_SelectSpdSts_SigSts: nonqueued-receiver-com-spec{data-element=Value, init-value=0}, required-interface=VeSR1B_y_SelectSpdSts_SigSts
      VeSR1B_y_VehicleStandStillSts: variation-point={short-label=vpVeSR1B_y_VehicleStandStillSts, sw-syscond=1}, nonqueued-receiver-com-spec{data-element=Value, handle-never-received=true, init-value=0}, required-interface=VeSR1B_y_VehicleStandStillSts
      VeSR1B_y_VehicleStandStillSts_SigSts: variation-point={short-label=vpVeSR1B_y_VehicleStandStillSts_SigSts, sw-syscond=1}, nonqueued-receiver-com-spec{data-element=Value, init-value=0}, required-interface=VeSR1B_y_VehicleStandStillSts_SigSts
      VeSR1B_y_eBurn_Stages: nonqueued-receiver-com-spec{data-element=Value, handle-never-received=true, init-value=0}, required-interface=VeSR1B_y_eBurn_Stages
      VeSR1B_y_eBurn_Stages_SigSts: nonqueued-receiver-com-spec{data-element=Value, init-value=0}, required-interface=VeSR1B_y_eBurn_Stages_SigSts
      VeSR1B_b_ABSActive_FD3: nonqueued-receiver-com-spec{data-element=Value, handle-never-received=true, init-value=0}, required-interface=VeSR1B_b_ABSActive_FD3
      VeSR1B_y_ABSActive_FD3_SigSts: nonqueued-receiver-com-spec{data-element=Value, init-value=0}, required-interface=VeSR1B_y_ABSActive_FD3_SigSts
      VeSR1B_y_AHH_Ready_Status: nonqueued-receiver-com-spec{data-element=Value, handle-never-received=true, init-value=0}, required-interface=VeSR1B_y_AHH_Ready_Status
      VeSR1B_y_AHH_Ready_Status_SigSts: nonqueued-receiver-com-spec{data-element=Value, init-value=0}, required-interface=VeSR1B_y_AHH_Ready_Status_SigSts
      VeSR1B_pbar_BrakeBoostPressureFD3: nonqueued-receiver-com-spec{data-element=Value, handle-never-received=true, init-value=0}, required-interface=VeSR1B_pbar_BrakeBoostPressureFD3
      VeSR1B_y_BrakeBoostPressureFD3_SigSts: nonqueued-receiver-com-spec{data-element=Value, init-value=0}, required-interface=VeSR1B_y_BrakeBoostPressureFD3_SigSts
      VeSR1B_b_BrakeInterventionSts: nonqueued-receiver-com-spec{data-element=Value, handle-never-received=true, init-value=0}, required-interface=VeSR1B_b_BrakeInterventionSts
      VeSR1B_y_BrakeInterventionSts_SigSts: nonqueued-receiver-com-spec{data-element=Value, init-value=0}, required-interface=VeSR1B_y_BrakeInterventionSts_SigSts
      VeSR1B_pbar_BrakePedalPressure_FD3: nonqueued-receiver-com-spec{data-element=Value, handle-never-received=true, init-value=0}, required-interface=VeSR1B_pbar_BrakePedalPressure_FD3
      VeSR1B_y_BrakePedalPressure_FD3_SigSts: nonqueued-receiver-com-spec{data-element=Value, init-value=0}, required-interface=VeSR1B_y_BrakePedalPressure_FD3_SigSts
      VeSR1B_y_Brake_MaxRegen_Ready_FD3: nonqueued-receiver-com-spec{data-element=Value, handle-never-received=true, init-value=0}, required-interface=VeSR1B_y_Brake_MaxRegen_Ready_FD3
      VeSR1B_y_Brake_MaxRegen_Ready_FD3_SigSts: nonqueued-receiver-com-spec{data-element=Value, init-value=0}, required-interface=VeSR1B_y_Brake_MaxRegen_Ready_FD3_SigSts
      VeSR1B_b_ESCActive_FD3: nonqueued-receiver-com-spec{data-element=Value, handle-never-received=true, init-value=0}, required-interface=VeSR1B_b_ESCActive_FD3
      VeSR1B_y_ESCActive_FD3_SigSts: nonqueued-receiver-com-spec{data-element=Value, init-value=0}, required-interface=VeSR1B_y_ESCActive_FD3_SigSts
      VeSR1B_b_ImpendingSkid: nonqueued-receiver-com-spec{data-element=Value, handle-never-received=true, init-value=0}, required-interface=VeSR1B_b_ImpendingSkid
      VeSR1B_y_ImpendingSkid_SigSts: nonqueued-receiver-com-spec{data-element=Value, init-value=0}, required-interface=VeSR1B_y_ImpendingSkid_SigSts
      VeSR1B_a_LatAcceleration_BSM_FD3: nonqueued-receiver-com-spec{data-element=Value, handle-never-received=true, init-value=0}, required-interface=VeSR1B_a_LatAcceleration_BSM_FD3
      VeSR1B_y_LatAcceleration_BSM_FD3_SigSts: nonqueued-receiver-com-spec{data-element=Value, init-value=0}, required-interface=VeSR1B_y_LatAcceleration_BSM_FD3_SigSts
      VeSR1B_a_LongAcceleration_BSM_FD3: nonqueued-receiver-com-spec{data-element=Value, handle-never-received=true, init-value=0}, required-interface=VeSR1B_a_LongAcceleration_BSM_FD3
      VeSR1B_y_LongAcceleration_BSM_FD3_SigSts: nonqueued-receiver-com-spec{data-element=Value, init-value=0}, required-interface=VeSR1B_y_LongAcceleration_BSM_FD3_SigSts
      VeSR1B_y_ParkingGearShiftReq_BSM: nonqueued-receiver-com-spec{data-element=Value, handle-never-received=true, init-value=0}, required-interface=VeSR1B_y_ParkingGearShiftReq_BSM
      VeSR1B_y_ParkingGearShiftReq_BSM_SigSts: nonqueued-receiver-com-spec{data-element=Value, init-value=0}, required-interface=VeSR1B_y_ParkingGearShiftReq_BSM_SigSts
      VeSR1B_Pct_Slope: nonqueued-receiver-com-spec{data-element=Value, handle-never-received=true, init-value=0}, required-interface=VeSR1B_Pct_Slope
      VeSR1B_y_Slope_SigSts: nonqueued-receiver-com-spec{data-element=Value, init-value=0}, required-interface=VeSR1B_y_Slope_SigSts
      VeSR1B_v_VehicleSpeedVSOSig_FD3: nonqueued-receiver-com-spec{data-element=Value, handle-never-received=true, init-value=0}, required-interface=VeSR1B_v_VehicleSpeedVSOSig_FD3
      VeSR1B_y_VehicleSpeedVSOSig_FD3_SigSts: nonqueued-receiver-com-spec{data-element=Value, init-value=0}, required-interface=VeSR1B_y_VehicleSpeedVSOSig_FD3_SigSts
      VeSR1B_v_LHFWheelSpeed_FD3: nonqueued-receiver-com-spec{data-element=Value, handle-never-received=true, init-value=0}, required-interface=VeSR1B_v_LHFWheelSpeed_FD3
      VeSR1B_y_LHFWheelSpeed_FD3_SigSts: nonqueued-receiver-com-spec{data-element=Value, init-value=0}, required-interface=VeSR1B_y_LHFWheelSpeed_FD3_SigSts
      VeSR1B_y_LHF_Spin_FD3: nonqueued-receiver-com-spec{data-element=Value, handle-never-received=true, init-value=0}, required-interface=VeSR1B_y_LHF_Spin_FD3
      VeSR1B_y_LHF_Spin_FD3_SigSts: nonqueued-receiver-com-spec{data-element=Value, init-value=0}, required-interface=VeSR1B_y_LHF_Spin_FD3_SigSts
      VeSR1B_b_LHFWhlSnsrFailSts_FD3: nonqueued-receiver-com-spec{data-element=Value, handle-never-received=true, init-value=0}, required-interface=VeSR1B_b_LHFWhlSnsrFailSts_FD3
      VeSR1B_y_LHFWhlSnsrFailSts_FD3_SigSts: nonqueued-receiver-com-spec{data-element=Value, init-value=0}, required-interface=VeSR1B_y_LHFWhlSnsrFailSts_FD3_SigSts
      VeSR1B_v_LHRWheelSpeed_FD3: nonqueued-receiver-com-spec{data-element=Value, handle-never-received=true, init-value=0}, required-interface=VeSR1B_v_LHRWheelSpeed_FD3
      VeSR1B_y_LHRWheelSpeed_FD3_SigSts: nonqueued-receiver-com-spec{data-element=Value, init-value=0}, required-interface=VeSR1B_y_LHRWheelSpeed_FD3_SigSts
      VeSR1B_y_LHR_Spin_FD3: nonqueued-receiver-com-spec{data-element=Value, handle-never-received=true, init-value=0}, required-interface=VeSR1B_y_LHR_Spin_FD3
      VeSR1B_y_LHR_Spin_FD3_SigSts: nonqueued-receiver-com-spec{data-element=Value, init-value=0}, required-interface=VeSR1B_y_LHR_Spin_FD3_SigSts
      VeSR1B_b_LHR_WhlSnsrFailStsFD3: nonqueued-receiver-com-spec{data-element=Value, handle-never-received=true, init-value=0}, required-interface=VeSR1B_b_LHR_WhlSnsrFailStsFD3
      VeSR1B_y_LHR_WhlSnsrFailStsFD3_SigSts: nonqueued-receiver-com-spec{data-element=Value, init-value=0}, required-interface=VeSR1B_y_LHR_WhlSnsrFailStsFD3_SigSts
      VeSR1B_v_RHFWheelSpeed_FD3: nonqueued-receiver-com-spec{data-element=Value, handle-never-received=true, init-value=0}, required-interface=VeSR1B_v_RHFWheelSpeed_FD3
      VeSR1B_y_RHFWheelSpeed_FD3_SigSts: nonqueued-receiver-com-spec{data-element=Value, init-value=0}, required-interface=VeSR1B_y_RHFWheelSpeed_FD3_SigSts
      VeSR1B_y_RHF_Spin_FD3: nonqueued-receiver-com-spec{data-element=Value, handle-never-received=true, init-value=0}, required-interface=VeSR1B_y_RHF_Spin_FD3
      VeSR1B_y_RHF_Spin_FD3_SigSts: nonqueued-receiver-com-spec{data-element=Value, init-value=0}, required-interface=VeSR1B_y_RHF_Spin_FD3_SigSts
      VeSR1B_b_RHF_WhlSnsrFailStsFD3: nonqueued-receiver-com-spec{data-element=Value, handle-never-received=true, init-value=0}, required-interface=VeSR1B_b_RHF_WhlSnsrFailStsFD3
      VeSR1B_y_RHF_WhlSnsrFailStsFD3_SigSts: nonqueued-receiver-com-spec{data-element=Value, init-value=0}, required-interface=VeSR1B_y_RHF_WhlSnsrFailStsFD3_SigSts
      VeSR1B_v_RHRWheelSpeed_FD3: nonqueued-receiver-com-spec{data-element=Value, handle-never-received=true, init-value=0}, required-interface=VeSR1B_v_RHRWheelSpeed_FD3
      VeSR1B_y_RHRWheelSpeed_FD3_SigSts: nonqueued-receiver-com-spec{data-element=Value, init-value=0}, required-interface=VeSR1B_y_RHRWheelSpeed_FD3_SigSts
      VeSR1B_y_RHR_Spin_FD3: nonqueued-receiver-com-spec{data-element=Value, handle-never-received=true, init-value=0}, required-interface=VeSR1B_y_RHR_Spin_FD3
      VeSR1B_y_RHR_Spin_FD3_SigSts: nonqueued-receiver-com-spec{data-element=Value, init-value=0}, required-interface=VeSR1B_y_RHR_Spin_FD3_SigSts
      VeSR1B_b_RHR_WhlSnsrFailStsFD3: nonqueued-receiver-com-spec{data-element=Value, handle-never-received=true, init-value=0}, required-interface=VeSR1B_b_RHR_WhlSnsrFailStsFD3
      VeSR1B_y_RHR_WhlSnsrFailStsFD3_SigSts: nonqueued-receiver-com-spec{data-element=Value, init-value=0}, required-interface=VeSR1B_y_RHR_WhlSnsrFailStsFD3_SigSts
      VeSR1B_b_ASRActive_FD3: nonqueued-receiver-com-spec{data-element=Value, handle-never-received=true, init-value=0}, required-interface=VeSR1B_b_ASRActive_FD3
      VeSR1B_y_ASRActive_FD3_SigSts: nonqueued-receiver-com-spec{data-element=Value, init-value=0}, required-interface=VeSR1B_y_ASRActive_FD3_SigSts
      VeSR1B_y_EPBSts_FD3: nonqueued-receiver-com-spec{data-element=Value, handle-never-received=true, init-value=0}, required-interface=VeSR1B_y_EPBSts_FD3
      VeSR1B_y_EPBSts_FD3_SigSts: nonqueued-receiver-com-spec{data-element=Value, init-value=0}, required-interface=VeSR1B_y_EPBSts_FD3_SigSts
      VeSR1B_l_TravelDistance: nonqueued-receiver-com-spec{data-element=Value, handle-never-received=true, init-value=0}, required-interface=VeSR1B_l_TravelDistance
      VeSR1B_y_TravelDistance_SigSts: nonqueued-receiver-com-spec{data-element=Value, init-value=0}, required-interface=VeSR1B_y_TravelDistance_SigSts
      VeSR1B_b_ABSFailSts_FD3: nonqueued-receiver-com-spec{data-element=Value, handle-never-received=true, init-value=0}, required-interface=VeSR1B_b_ABSFailSts_FD3
      VeSR1B_y_ABSFailSts_FD3_SigSts: nonqueued-receiver-com-spec{data-element=Value, init-value=0}, required-interface=VeSR1B_y_ABSFailSts_FD3_SigSts
      VeSR1B_b_ESCFailSts_FD3: nonqueued-receiver-com-spec{data-element=Value, handle-never-received=true, init-value=0}, required-interface=VeSR1B_b_ESCFailSts_FD3
      VeSR1B_y_ESCFailSts_FD3_SigSts: nonqueued-receiver-com-spec{data-element=Value, init-value=0}, required-interface=VeSR1B_y_ESCFailSts_FD3_SigSts
      VeSR1B_b_ESCIntervention: nonqueued-receiver-com-spec{data-element=Value, handle-never-received=true, init-value=0}, required-interface=VeSR1B_b_ESCIntervention
      VeSR1B_y_ESCIntervention_SigSts: nonqueued-receiver-com-spec{data-element=Value, init-value=0}, required-interface=VeSR1B_y_ESCIntervention_SigSts
      VeSR1B_b_Function2Sts_FD3: nonqueued-receiver-com-spec{data-element=Value, handle-never-received=true, init-value=0}, required-interface=VeSR1B_b_Function2Sts_FD3
      VeSR1B_y_Function2Sts_FD3_SigSts: nonqueued-receiver-com-spec{data-element=Value, init-value=0}, required-interface=VeSR1B_y_Function2Sts_FD3_SigSts
      VeSR1B_M_CmdTotBrkFricAxTrqFD3: nonqueued-receiver-com-spec{data-element=Value, handle-never-received=true, init-value=0}, required-interface=VeSR1B_M_CmdTotBrkFricAxTrqFD3
      VeSR1B_y_CmdTotBrkFricAxTrqFD3_SigSts: nonqueued-receiver-com-spec{data-element=Value, init-value=0}, required-interface=VeSR1B_y_CmdTotBrkFricAxTrqFD3_SigSts
      VeSR1B_y_DrvrRqAxlTqEnbdBSMFD3: nonqueued-receiver-com-spec{data-element=Value, handle-never-received=true, init-value=0}, required-interface=VeSR1B_y_DrvrRqAxlTqEnbdBSMFD3
      VeSR1B_y_DrvrRqAxlTqEnbdBSMFD3_SigSts: nonqueued-receiver-com-spec{data-element=Value, init-value=0}, required-interface=VeSR1B_y_DrvrRqAxlTqEnbdBSMFD3_SigSts
      VeSR1B_M_DrvrRquestdAxlTqBSMFD3: nonqueued-receiver-com-spec{data-element=Value, handle-never-received=true, init-value=0}, required-interface=VeSR1B_M_DrvrRquestdAxlTqBSMFD3
      VeSR1B_y_DrvrRquestdAxlTqBSMFD3_SigSts: nonqueued-receiver-com-spec{data-element=Value, init-value=0}, required-interface=VeSR1B_y_DrvrRquestdAxlTqBSMFD3_SigSts
      VeSR1B_b_FrontAxleMax_Rq_BSMFD3: nonqueued-receiver-com-spec{data-element=Value, handle-never-received=true, init-value=0}, required-interface=VeSR1B_b_FrontAxleMax_Rq_BSMFD3
      VeSR1B_y_FrontAxleMax_Rq_BSMFD3_SigSts: nonqueued-receiver-com-spec{data-element=Value, init-value=0}, required-interface=VeSR1B_y_FrontAxleMax_Rq_BSMFD3_SigSts
      VeSR1B_b_FrontAxleMin_Rq_BSMFD3: nonqueued-receiver-com-spec{data-element=Value, handle-never-received=true, init-value=0}, required-interface=VeSR1B_b_FrontAxleMin_Rq_BSMFD3
      VeSR1B_y_FrontAxleMin_Rq_BSMFD3_SigSts: nonqueued-receiver-com-spec{data-element=Value, init-value=0}, required-interface=VeSR1B_y_FrontAxleMin_Rq_BSMFD3_SigSts
      VeSR1B_M_FrontAxle_Rq_BSM_FD3: nonqueued-receiver-com-spec{data-element=Value, handle-never-received=true, init-value=0}, required-interface=VeSR1B_M_FrontAxle_Rq_BSM_FD3
      VeSR1B_y_FrontAxle_Rq_BSM_FD3_SigSts: nonqueued-receiver-com-spec{data-element=Value, init-value=0}, required-interface=VeSR1B_y_FrontAxle_Rq_BSM_FD3_SigSts
      VeSR1B_y_Not_OK_To_Race: variation-point={short-label=vpVeSR1B_y_Not_OK_To_Race, sw-syscond=1}, nonqueued-receiver-com-spec{data-element=Value, handle-never-received=true, init-value=0}, required-interface=VeSR1B_y_Not_OK_To_Race
      VeSR1B_y_Not_OK_To_Race_SigSts: variation-point={short-label=vpVeSR1B_y_Not_OK_To_Race_SigSts, sw-syscond=1}, nonqueued-receiver-com-spec{data-element=Value, init-value=0}, required-interface=VeSR1B_y_Not_OK_To_Race_SigSts
      VeSR1B_y_OPD_Hold_Status: nonqueued-receiver-com-spec{data-element=Value, handle-never-received=true, init-value=0}, required-interface=VeSR1B_y_OPD_Hold_Status
      VeSR1B_y_OPD_Hold_Status_SigSts: nonqueued-receiver-com-spec{data-element=Value, init-value=0}, required-interface=VeSR1B_y_OPD_Hold_Status_SigSts
      VeSR1B_b_RearAxle_Max_Rq_BSMFD3: nonqueued-receiver-com-spec{data-element=Value, handle-never-received=true, init-value=0}, required-interface=VeSR1B_b_RearAxle_Max_Rq_BSMFD3
      VeSR1B_y_RearAxle_Max_Rq_BSMFD3_SigSts: nonqueued-receiver-com-spec{data-element=Value, init-value=0}, required-interface=VeSR1B_y_RearAxle_Max_Rq_BSMFD3_SigSts
      VeSR1B_b_RearAxle_Min_Rq_BSMFD3: nonqueued-receiver-com-spec{data-element=Value, handle-never-received=true, init-value=0}, required-interface=VeSR1B_b_RearAxle_Min_Rq_BSMFD3
      VeSR1B_y_RearAxle_Min_Rq_BSMFD3_SigSts: nonqueued-receiver-com-spec{data-element=Value, init-value=0}, required-interface=VeSR1B_y_RearAxle_Min_Rq_BSMFD3_SigSts
      VeSR1B_M_RearAxle_Rq_BSM_FD3: nonqueued-receiver-com-spec{data-element=Value, handle-never-received=true, init-value=0}, required-interface=VeSR1B_M_RearAxle_Rq_BSM_FD3
      VeSR1B_y_RearAxle_Rq_BSM_FD3_SigSts: nonqueued-receiver-com-spec{data-element=Value, init-value=0}, required-interface=VeSR1B_y_RearAxle_Rq_BSM_FD3_SigSts
      VeSR1B_M_Regen_AxleTorque_Req: nonqueued-receiver-com-spec{data-element=Value, handle-never-received=true, init-value=0}, required-interface=VeSR1B_M_Regen_AxleTorque_Req
      VeSR1B_y_Regen_AxleTorque_Req_SigSts: nonqueued-receiver-com-spec{data-element=Value, init-value=0}, required-interface=VeSR1B_y_Regen_AxleTorque_Req_SigSts
      VeSR1B_y_WED_MODE_RQ: nonqueued-receiver-com-spec{data-element=Value, handle-never-received=true, init-value=0}, required-interface=VeSR1B_y_WED_MODE_RQ
      VeSR1B_y_WED_MODE_RQ_SigSts: nonqueued-receiver-com-spec{data-element=Value, init-value=0}, required-interface=VeSR1B_y_WED_MODE_RQ_SigSts
      VeSR1B_Pct_BrakePdlPosn_FD3: nonqueued-receiver-com-spec{data-element=Value, handle-never-received=true, init-value=0}, required-interface=VeSR1B_Pct_BrakePdlPosn_FD3
      VeSR1B_y_BrakePdlPosn_FD3_SigSts: nonqueued-receiver-com-spec{data-element=Value, init-value=0}, required-interface=VeSR1B_y_BrakePdlPosn_FD3_SigSts
      VeSR1B_b_BrkPdl_Flt_FD3: nonqueued-receiver-com-spec{data-element=Value, handle-never-received=true, init-value=0}, required-interface=VeSR1B_b_BrkPdl_Flt_FD3
      VeSR1B_y_BrkPdl_Flt_FD3_SigSts: nonqueued-receiver-com-spec{data-element=Value, init-value=0}, required-interface=VeSR1B_y_BrkPdl_Flt_FD3_SigSts
      VeSR1B_y_BrkPdl_Stat_FD3: nonqueued-receiver-com-spec{data-element=Value, handle-never-received=true, init-value=0}, required-interface=VeSR1B_y_BrkPdl_Stat_FD3
      VeSR1B_y_BrkPdl_Stat_FD3_SigSts: nonqueued-receiver-com-spec{data-element=Value, init-value=0}, required-interface=VeSR1B_y_BrkPdl_Stat_FD3_SigSts
      VeSR1B_y_FOTA_Install_Type: nonqueued-receiver-com-spec{data-element=Value, handle-never-received=true, init-value=0}, required-interface=VeSR1B_y_FOTA_Install_Type
      VeSR1B_y_FOTA_Install_Type_SigSts: nonqueued-receiver-com-spec{data-element=Value, init-value=0}, required-interface=VeSR1B_y_FOTA_Install_Type_SigSts
      VeSR1B_y_FOTA_Installation_Sts: nonqueued-receiver-com-spec{data-element=Value, handle-never-received=true, init-value=0}, required-interface=VeSR1B_y_FOTA_Installation_Sts
      VeSR1B_y_FOTA_Installation_Sts_SigSts: nonqueued-receiver-com-spec{data-element=Value, init-value=0}, required-interface=VeSR1B_y_FOTA_Installation_Sts_SigSts
      VeSR1B_b_CurrBattFailStatus: nonqueued-receiver-com-spec{data-element=Value, handle-never-received=true, init-value=0}, required-interface=VeSR1B_b_CurrBattFailStatus
      VeSR1B_y_CurrBattFailStatus_SigSts: nonqueued-receiver-com-spec{data-element=Value, init-value=0}, required-interface=VeSR1B_y_CurrBattFailStatus_SigSts
      VeSR1B_I_IBS3_Ibatt: nonqueued-receiver-com-spec{data-element=Value, handle-never-received=true, init-value=0}, required-interface=VeSR1B_I_IBS3_Ibatt
      VeSR1B_y_IBS3_Ibatt_SigSts: nonqueued-receiver-com-spec{data-element=Value, init-value=0}, required-interface=VeSR1B_y_IBS3_Ibatt_SigSts
      VeSR1B_U_IBS3_Vbatt: nonqueued-receiver-com-spec{data-element=Value, handle-never-received=true, init-value=0}, required-interface=VeSR1B_U_IBS3_Vbatt
      VeSR1B_y_IBS3_Vbatt_SigSts: nonqueued-receiver-com-spec{data-element=Value, init-value=0}, required-interface=VeSR1B_y_IBS3_Vbatt_SigSts
      VeSR1B_b_VoltBattFailStatus: nonqueued-receiver-com-spec{data-element=Value, handle-never-received=true, init-value=0}, required-interface=VeSR1B_b_VoltBattFailStatus
      VeSR1B_y_VoltBattFailStatus_SigSts: nonqueued-receiver-com-spec{data-element=Value, init-value=0}, required-interface=VeSR1B_y_VoltBattFailStatus_SigSts
      VeSR1B_Pct_IBS3_SOC: nonqueued-receiver-com-spec{data-element=Value, handle-never-received=true, init-value=0}, required-interface=VeSR1B_Pct_IBS3_SOC
      VeSR1B_y_IBS3_SOC_SigSts: nonqueued-receiver-com-spec{data-element=Value, init-value=0}, required-interface=VeSR1B_y_IBS3_SOC_SigSts
      VeSR1B_b_IBS3_SOC_Accuracy: nonqueued-receiver-com-spec{data-element=Value, handle-never-received=true, init-value=0}, required-interface=VeSR1B_b_IBS3_SOC_Accuracy
      VeSR1B_y_IBS3_SOC_Accuracy_SigSts: nonqueued-receiver-com-spec{data-element=Value, init-value=0}, required-interface=VeSR1B_y_IBS3_SOC_Accuracy_SigSts
      VeSR1B_T_IBS3_T_BATT: nonqueued-receiver-com-spec{data-element=Value, handle-never-received=true, init-value=0}, required-interface=VeSR1B_T_IBS3_T_BATT
      VeSR1B_y_IBS3_T_BATT_SigSts: nonqueued-receiver-com-spec{data-element=Value, init-value=0}, required-interface=VeSR1B_y_IBS3_T_BATT_SigSts
      VeSR1B_b_IBS3_TempFailStatus: nonqueued-receiver-com-spec{data-element=Value, handle-never-received=true, init-value=0}, required-interface=VeSR1B_b_IBS3_TempFailStatus
      VeSR1B_y_IBS3_TempFailStatus_SigSts: nonqueued-receiver-com-spec{data-element=Value, init-value=0}, required-interface=VeSR1B_y_IBS3_TempFailStatus_SigSts
      VeSR1B_b_IMPACTCommand_FD3: nonqueued-receiver-com-spec{data-element=Value, handle-never-received=true, init-value=0}, required-interface=VeSR1B_b_IMPACTCommand_FD3
      VeSR1B_y_IMPACTCommand_FD3_SigSts: nonqueued-receiver-com-spec{data-element=Value, init-value=0}, required-interface=VeSR1B_y_IMPACTCommand_FD3_SigSts
      VeSR1B_b_IMPACTConfirm_FD3: nonqueued-receiver-com-spec{data-element=Value, handle-never-received=true, init-value=0}, required-interface=VeSR1B_b_IMPACTConfirm_FD3
      VeSR1B_y_IMPACTConfirm_FD3_SigSts: nonqueued-receiver-com-spec{data-element=Value, init-value=0}, required-interface=VeSR1B_y_IMPACTConfirm_FD3_SigSts
      VeSR1B_kl_TotalOdometer: nonqueued-receiver-com-spec{data-element=Value, handle-never-received=true, init-value=0}, required-interface=VeSR1B_kl_TotalOdometer
      VeSR1B_y_TotalOdometer_SigSts: nonqueued-receiver-com-spec{data-element=Value, init-value=0}, required-interface=VeSR1B_y_TotalOdometer_SigSts
      VeSR1B_y_DisplayedSpeedLimSts: nonqueued-receiver-com-spec{data-element=Value, handle-never-received=true, init-value=0}, required-interface=VeSR1B_y_DisplayedSpeedLimSts
      VeSR1B_y_DisplayedSpeedLimSts_SigSts: nonqueued-receiver-com-spec{data-element=Value, init-value=0}, required-interface=VeSR1B_y_DisplayedSpeedLimSts_SigSts
      VeSR1B_b_DC_PwrLev: variation-point={short-label=vpVeSR1B_b_DC_PwrLev, sw-syscond=1}, nonqueued-receiver-com-spec{data-element=Value, handle-never-received=true, init-value=0}, required-interface=VeSR1B_b_DC_PwrLev
      VeSR1B_y_DC_PwrLev_SigSts: variation-point={short-label=vpVeSR1B_y_DC_PwrLev_SigSts, sw-syscond=1}, nonqueued-receiver-com-spec{data-element=Value, init-value=0}, required-interface=VeSR1B_y_DC_PwrLev_SigSts
      VeSR1B_y_PwrLev: nonqueued-receiver-com-spec{data-element=Value, handle-never-received=true, init-value=0}, required-interface=VeSR1B_y_PwrLev
      VeSR1B_y_PwrLev_SigSts: nonqueued-receiver-com-spec{data-element=Value, init-value=0}, required-interface=VeSR1B_y_PwrLev_SigSts
      VeSR1B_b_SOC_Max_Lev: nonqueued-receiver-com-spec{data-element=Value, handle-never-received=true, init-value=0}, required-interface=VeSR1B_b_SOC_Max_Lev
      VeSR1B_y_SOC_Max_Lev_SigSts: nonqueued-receiver-com-spec{data-element=Value, init-value=0}, required-interface=VeSR1B_y_SOC_Max_Lev_SigSts
      VeSR1B_b_Speed_Unit: nonqueued-receiver-com-spec{data-element=Value, handle-never-received=true, init-value=0}, required-interface=VeSR1B_b_Speed_Unit
      VeSR1B_y_Speed_Unit_SigSts: nonqueued-receiver-com-spec{data-element=Value, init-value=0}, required-interface=VeSR1B_y_Speed_Unit_SigSts
      VeSR1B_b_Traffic_Sign_Info: nonqueued-receiver-com-spec{data-element=Value, handle-never-received=true, init-value=0}, required-interface=VeSR1B_b_Traffic_Sign_Info
      VeSR1B_y_Traffic_Sign_Info_SigSts: nonqueued-receiver-com-spec{data-element=Value, init-value=0}, required-interface=VeSR1B_y_Traffic_Sign_Info_SigSts
      VeSR1B_b_Creep: variation-point={short-label=vpVeSR1B_b_Creep, sw-syscond=1}, nonqueued-receiver-com-spec{data-element=Value, handle-never-received=true, init-value=0}, required-interface=VeSR1B_b_Creep
      VeSR1B_y_Creep_SigSts: variation-point={short-label=vpVeSR1B_y_Creep_SigSts, sw-syscond=1}, nonqueued-receiver-com-spec{data-element=Value, init-value=0}, required-interface=VeSR1B_y_Creep_SigSts
      VeSR1B_y_SBR1RowDrvrSeatStsFD3: nonqueued-receiver-com-spec{data-element=Value, handle-never-received=true, init-value=0}, required-interface=VeSR1B_y_SBR1RowDrvrSeatStsFD3
      VeSR1B_y_SBR1RowDrvrSeatStsFD3_SigSts: nonqueued-receiver-com-spec{data-element=Value, init-value=0}, required-interface=VeSR1B_y_SBR1RowDrvrSeatStsFD3_SigSts
      VeSR1B_b_DriverEngineOffRequest: nonqueued-receiver-com-spec{data-element=Value, handle-never-received=true, init-value=0}, required-interface=VeSR1B_b_DriverEngineOffRequest
      VeSR1B_y_DriverEngineOffRequest_SigSts: nonqueued-receiver-com-spec{data-element=Value, init-value=0}, required-interface=VeSR1B_y_DriverEngineOffRequest_SigSts
      VeSR1B_y_FobSearchResult: nonqueued-receiver-com-spec{data-element=Value, handle-never-received=true, init-value=0}, required-interface=VeSR1B_y_FobSearchResult
      VeSR1B_y_FobSearchResult_SigSts: nonqueued-receiver-com-spec{data-element=Value, init-value=0}, required-interface=VeSR1B_y_FobSearchResult_SigSts
      VeSR1B_y_ETM_PaddlesModeReq: nonqueued-receiver-com-spec{data-element=Value, handle-never-received=true, init-value=0}, required-interface=VeSR1B_y_ETM_PaddlesModeReq
      VeSR1B_y_ETM_PaddlesModeReq_SigSts: nonqueued-receiver-com-spec{data-element=Value, init-value=0}, required-interface=VeSR1B_y_ETM_PaddlesModeReq_SigSts
      VeSR1B_b_ChargeNow: nonqueued-receiver-com-spec{data-element=Value, handle-never-received=true, init-value=0}, required-interface=VeSR1B_b_ChargeNow
      VeSR1B_y_ChargeNow_SigSts: nonqueued-receiver-com-spec{data-element=Value, init-value=0}, required-interface=VeSR1B_y_ChargeNow_SigSts
      VeSR1B_y_Launch_Torque_Sft_Btn_Req: variation-point={short-label=vpVeSR1B_y_Launch_Torque_Sft_Btn_Req, sw-syscond=1}, nonqueued-receiver-com-spec{data-element=Value, handle-never-received=true, init-value=0}, required-interface=VeSR1B_y_Launch_Torque_Sft_Btn_Req
      VeSR1B_y_Launch_Torque_Sft_Btn_Req_SigSts: variation-point={short-label=vpVeSR1B_y_Launch_Torque_Sft_Btn_Req_SigSts, sw-syscond=1}, nonqueued-receiver-com-spec{data-element=Value, init-value=0}, required-interface=VeSR1B_y_Launch_Torque_Sft_Btn_Req_SigSts
      VeSR1B_b_RACE_PREP_RACE_TYPE_REQ: variation-point={short-label=vpVeSR1B_b_RACE_PREP_RACE_TYPE_REQ, sw-syscond=1}, nonqueued-receiver-com-spec{data-element=Value, handle-never-received=true, init-value=0}, required-interface=VeSR1B_b_RACE_PREP_RACE_TYPE_REQ
      VeSR1B_y_RACE_PREP_RACE_TYPE_REQ_SigSts: variation-point={short-label=vpVeSR1B_y_RACE_PREP_RACE_TYPE_REQ_SigSts, sw-syscond=1}, nonqueued-receiver-com-spec{data-element=Value, init-value=0}, required-interface=VeSR1B_y_RACE_PREP_RACE_TYPE_REQ_SigSts
      VeSR1B_y_E_Coasting_Req: nonqueued-receiver-com-spec{data-element=Value, handle-never-received=true, init-value=0}, required-interface=VeSR1B_y_E_Coasting_Req
      VeSR1B_y_E_Coasting_Req_SigSts: nonqueued-receiver-com-spec{data-element=Value, init-value=0}, required-interface=VeSR1B_y_E_Coasting_Req_SigSts
      VeSR1B_b_PlugAndChargeReq: nonqueued-receiver-com-spec{data-element=Value, handle-never-received=true, init-value=0}, required-interface=VeSR1B_b_PlugAndChargeReq
      VeSR1B_y_PlugAndChargeReq_SigSts: nonqueued-receiver-com-spec{data-element=Value, init-value=0}, required-interface=VeSR1B_y_PlugAndChargeReq_SigSts
      VeSR1B_b_Secure_Idle_Req: nonqueued-receiver-com-spec{data-element=Value, handle-never-received=true, init-value=0}, required-interface=VeSR1B_b_Secure_Idle_Req
      VeSR1B_y_Secure_Idle_Req_SigSts: nonqueued-receiver-com-spec{data-element=Value, init-value=0}, required-interface=VeSR1B_y_Secure_Idle_Req_SigSts
      VeSR1B_y_GlobDrvMdRq: nonqueued-receiver-com-spec{data-element=Value, handle-never-received=true, init-value=0}, required-interface=VeSR1B_y_GlobDrvMdRq
      VeSR1B_y_GlobDrvMdRq_SigSts: nonqueued-receiver-com-spec{data-element=Value, init-value=0}, required-interface=VeSR1B_y_GlobDrvMdRq_SigSts
      VeSR1B_b_IMMO_CODE_RESPONSE_NewEvent: nonqueued-receiver-com-spec{data-element=Value, init-value=0}, required-interface=VeSR1B_b_IMMO_CODE_RESPONSE_NewEvent
      VeSR1B_y_ControlEncodingRsp: nonqueued-receiver-com-spec{data-element=Value, handle-never-received=true, init-value=0}, required-interface=VeSR1B_y_ControlEncodingRsp
      VeSR1B_y_ControlEncodingRsp_SigSts: nonqueued-receiver-com-spec{data-element=Value, init-value=0}, required-interface=VeSR1B_y_ControlEncodingRsp_SigSts
      VeSR1B_y_MKKey1org21: nonqueued-receiver-com-spec{data-element=Value, handle-never-received=true, init-value=0}, required-interface=VeSR1B_y_MKKey1org21
      VeSR1B_y_MKKey1org21_SigSts: nonqueued-receiver-com-spec{data-element=Value, init-value=0}, required-interface=VeSR1B_y_MKKey1org21_SigSts
      VeSR1B_y_MKKey2org22: nonqueued-receiver-com-spec{data-element=Value, handle-never-received=true, init-value=0}, required-interface=VeSR1B_y_MKKey2org22
      VeSR1B_y_MKKey2org22_SigSts: nonqueued-receiver-com-spec{data-element=Value, init-value=0}, required-interface=VeSR1B_y_MKKey2org22_SigSts
      VeSR1B_y_MKKey_3: nonqueued-receiver-com-spec{data-element=Value, handle-never-received=true, init-value=0}, required-interface=VeSR1B_y_MKKey_3
      VeSR1B_y_MKKey_3_SigSts: nonqueued-receiver-com-spec{data-element=Value, init-value=0}, required-interface=VeSR1B_y_MKKey_3_SigSts
      VeSR1B_y_MKKey_4: nonqueued-receiver-com-spec{data-element=Value, handle-never-received=true, init-value=0}, required-interface=VeSR1B_y_MKKey_4
      VeSR1B_y_MKKey_4_SigSts: nonqueued-receiver-com-spec{data-element=Value, init-value=0}, required-interface=VeSR1B_y_MKKey_4_SigSts
      VeSR1B_y_MKKey_5: nonqueued-receiver-com-spec{data-element=Value, handle-never-received=true, init-value=0}, required-interface=VeSR1B_y_MKKey_5
      VeSR1B_y_MKKey_5_SigSts: nonqueued-receiver-com-spec{data-element=Value, init-value=0}, required-interface=VeSR1B_y_MKKey_5_SigSts
      VeSR1B_y_MKKey_6: nonqueued-receiver-com-spec{data-element=Value, handle-never-received=true, init-value=0}, required-interface=VeSR1B_y_MKKey_6
      VeSR1B_y_MKKey_6_SigSts: nonqueued-receiver-com-spec{data-element=Value, init-value=0}, required-interface=VeSR1B_y_MKKey_6_SigSts
      VeSR1B_b_ImmoParkReq: nonqueued-receiver-com-spec{data-element=Value, handle-never-received=true, init-value=0}, required-interface=VeSR1B_b_ImmoParkReq
      VeSR1B_y_ImmoParkReq_SigSts: nonqueued-receiver-com-spec{data-element=Value, init-value=0}, required-interface=VeSR1B_y_ImmoParkReq_SigSts
      FsftPLTR_e_HAS_TelltaleSts: client-com-spec=FsftPLTR_e_HAS_TelltaleSts, required-interface=FsftPLTR_e_HAS_TelltaleSts
      PokePLTR_e_HAS_TelltaleSts: client-com-spec=PokePLTR_e_HAS_TelltaleSts, required-interface=PokePLTR_e_HAS_TelltaleSts
      FsftPLTR_e_AEBSystemSts: client-com-spec=FsftPLTR_e_AEBSystemSts, required-interface=FsftPLTR_e_AEBSystemSts
      PokePLTR_e_AEBSystemSts: client-com-spec=PokePLTR_e_AEBSystemSts, required-interface=PokePLTR_e_AEBSystemSts
      FsftPLTR_e_MRM_Status: client-com-spec=FsftPLTR_e_MRM_Status, required-interface=FsftPLTR_e_MRM_Status
      PokePLTR_e_MRM_Status: client-com-spec=PokePLTR_e_MRM_Status, required-interface=PokePLTR_e_MRM_Status
      FsftASLR_b_TSRSts: client-com-spec=FsftASLR_b_TSRSts, required-interface=FsftASLR_b_TSRSts
      PokeASLR_e_TSRSts: client-com-spec=PokeASLR_e_TSRSts, required-interface=PokeASLR_e_TSRSts
      FsftPLTR_e_MRM_Status_C2: client-com-spec=FsftPLTR_e_MRM_Status_C2, required-interface=FsftPLTR_e_MRM_Status_C2
      PokePLTR_e_MRM_Status_C2: client-com-spec=PokePLTR_e_MRM_Status_C2, required-interface=PokePLTR_e_MRM_Status_C2
      FsftPLTR_b_Prmry_AutoPosCorrMd: client-com-spec=FsftPLTR_b_Prmry_AutoPosCorrMd, required-interface=FsftPLTR_b_Prmry_AutoPosCorrMd
      PokePLTR_e_Prmry_AutoPosCorrMd: client-com-spec=PokePLTR_e_Prmry_AutoPosCorrMd, required-interface=PokePLTR_e_Prmry_AutoPosCorrMd
      FsftPLTR_b_Prmry_ShiftSnsFA: client-com-spec=FsftPLTR_b_Prmry_ShiftSnsFA, required-interface=FsftPLTR_b_Prmry_ShiftSnsFA
      PokePLTR_b_Prmry_ShiftSnsFA: client-com-spec=PokePLTR_b_Prmry_ShiftSnsFA, required-interface=PokePLTR_b_Prmry_ShiftSnsFA
      FsftPLTR_b_Prmry_ShifterDispFA: client-com-spec=FsftPLTR_b_Prmry_ShifterDispFA, required-interface=FsftPLTR_b_Prmry_ShifterDispFA
      PokePLTR_b_Prmry_ShifterDispFA: client-com-spec=PokePLTR_b_Prmry_ShifterDispFA, required-interface=PokePLTR_b_Prmry_ShifterDispFA
      FsftPLTR_b_Prmry_TransShiftPstn: client-com-spec=FsftPLTR_b_Prmry_TransShiftPstn, required-interface=FsftPLTR_b_Prmry_TransShiftPstn
      PokePLTR_e_Prmry_TransShiftPstn: client-com-spec=PokePLTR_e_Prmry_TransShiftPstn, required-interface=PokePLTR_e_Prmry_TransShiftPstn
      FsftPLTR_b_Prmry_ShiftLockFA: client-com-spec=FsftPLTR_b_Prmry_ShiftLockFA, required-interface=FsftPLTR_b_Prmry_ShiftLockFA
      PokePLTR_b_Prmry_ShiftLockFA: client-com-spec=PokePLTR_b_Prmry_ShiftLockFA, required-interface=PokePLTR_b_Prmry_ShiftLockFA
      FsftPMDR_e_PowerModeRaw: client-com-spec=FsftPMDR_e_PowerModeRaw, required-interface=FsftPMDR_e_PowerModeRaw
      PokePMDR_e_PowerModeRaw: client-com-spec=PokePMDR_e_PowerModeRaw, required-interface=PokePMDR_e_PowerModeRaw
      PokeTAIR_b_ACCompReq: client-com-spec=PokeTAIR_b_ACCompReq, required-interface=PokeTAIR_b_ACCompReq
      PokePLTR_b_InternalLightSts: client-com-spec=PokePLTR_b_InternalLightSts, required-interface=PokePLTR_b_InternalLightSts
      FsftTRIR_b_LoadShed: client-com-spec=FsftTRIR_b_LoadShed, required-interface=FsftTRIR_b_LoadShed
      PokeTRIR_b_LoadShed: client-com-spec=PokeTRIR_b_LoadShed, required-interface=PokeTRIR_b_LoadShed
      FsftTRIR_b_ClimateInfo: client-com-spec=FsftTRIR_b_ClimateInfo, required-interface=FsftTRIR_b_ClimateInfo
      PokeTRIR_e_ClimateInfo: client-com-spec=PokeTRIR_e_ClimateInfo, required-interface=PokeTRIR_e_ClimateInfo
      PokePLTR_b_DrvrSeatSnsrFailSts: client-com-spec=PokePLTR_b_DrvrSeatSnsrFailSts, required-interface=PokePLTR_b_DrvrSeatSnsrFailSts
      FsftPLTR_e_DrvrSeatSnsrSts: client-com-spec=FsftPLTR_e_DrvrSeatSnsrSts, required-interface=FsftPLTR_e_DrvrSeatSnsrSts
      PokePLTR_e_DrvrSeatSnsrSts: client-com-spec=PokePLTR_e_DrvrSeatSnsrSts, required-interface=PokePLTR_e_DrvrSeatSnsrSts
      PokeTIMR_e_GlobalDrvMdRq_BCM: client-com-spec=PokeTIMR_e_GlobalDrvMdRq_BCM, required-interface=PokeTIMR_e_GlobalDrvMdRq_BCM
      PokeTIMR_e_LaunchModeSwitch: variation-point={short-label=vpPokeTIMR_e_LaunchModeSwitch, sw-syscond=1}, client-com-spec=PokeTIMR_e_LaunchModeSwitch, required-interface=PokeTIMR_e_LaunchModeSwitch
      PokeTIMR_e_LeftSwitchReq: client-com-spec=PokeTIMR_e_LeftSwitchReq, required-interface=PokeTIMR_e_LeftSwitchReq
      PokeDMIR_e_PowershotSts: variation-point={short-label=vpPokeDMIR_e_PowershotSts, sw-syscond=1}, client-com-spec=PokeDMIR_e_PowershotSts, required-interface=PokeDMIR_e_PowershotSts
      FsftTRIR_b_HVACPrecCondSts: client-com-spec=FsftTRIR_b_HVACPrecCondSts, required-interface=FsftTRIR_b_HVACPrecCondSts
      PokeTRIR_e_HVACPrecCondSts: client-com-spec=PokeTRIR_e_HVACPrecCondSts, required-interface=PokeTRIR_e_HVACPrecCondSts
      TmotTRIR_b_HVACPrecCondSts: client-com-spec=TmotTRIR_b_HVACPrecCondSts, required-interface=TmotTRIR_b_HVACPrecCondSts
      FsftTAIR_b_RearCabinFanSts: client-com-spec=FsftTAIR_b_RearCabinFanSts, required-interface=FsftTAIR_b_RearCabinFanSts
      PokeTAIR_y_RearCabinFanSts: client-com-spec=PokeTAIR_y_RearCabinFanSts, required-interface=PokeTAIR_y_RearCabinFanSts
      PokeTIMR_e_RightSwitchReq: client-com-spec=PokeTIMR_e_RightSwitchReq, required-interface=PokeTIMR_e_RightSwitchReq
      PokeTIMR_e_CustomInterfaceBtn: variation-point={short-label=vpPokeTIMR_e_CustomInterfaceBtn, sw-syscond=1}, client-com-spec=PokeTIMR_e_CustomInterfaceBtn, required-interface=PokeTIMR_e_CustomInterfaceBtn
      PokeTIMR_e_TrrnToggleMdSwitch: client-com-spec=PokeTIMR_e_TrrnToggleMdSwitch, required-interface=PokeTIMR_e_TrrnToggleMdSwitch
      FsftPLTR_e_Command_15Sts: client-com-spec=FsftPLTR_e_Command_15Sts, required-interface=FsftPLTR_e_Command_15Sts
      PokePLTR_e_Command_15Sts: client-com-spec=PokePLTR_e_Command_15Sts, required-interface=PokePLTR_e_Command_15Sts
      FsftHSWR_b_CBC_BntAjrRwVlStsVolt: client-com-spec=FsftHSWR_b_CBC_BntAjrRwVlStsVolt, required-interface=FsftHSWR_b_CBC_BntAjrRwVlStsVolt
      PokeHSWR_U_CBC_BntAjrRwVlStsVolt: client-com-spec=PokeHSWR_U_CBC_BntAjrRwVlStsVolt, required-interface=PokeHSWR_U_CBC_BntAjrRwVlStsVolt
      PokeCITR_b_Drv_Dr_Unlocking: client-com-spec=PokeCITR_b_Drv_Dr_Unlocking, required-interface=PokeCITR_b_Drv_Dr_Unlocking
      FsftPMDR_e_KeyInIgn: client-com-spec=FsftPMDR_e_KeyInIgn, required-interface=FsftPMDR_e_KeyInIgn
      PokePMDR_e_KeyInIgn: client-com-spec=PokePMDR_e_KeyInIgn, required-interface=PokePMDR_e_KeyInIgn
      FsftPLTR_b_RmtVehStartReq: client-com-spec=FsftPLTR_b_RmtVehStartReq, required-interface=FsftPLTR_b_RmtVehStartReq
      PokePLTR_b_RmtVehStartReq: client-com-spec=PokePLTR_b_RmtVehStartReq, required-interface=PokePLTR_b_RmtVehStartReq
      FsftTRIR_b_SCCActv: client-com-spec=FsftTRIR_b_SCCActv, required-interface=FsftTRIR_b_SCCActv
      PokeTRIR_b_SCCActv: client-com-spec=PokeTRIR_b_SCCActv, required-interface=PokeTRIR_b_SCCActv
      PokeTRIR_b_FL_HS_Fail: client-com-spec=PokeTRIR_b_FL_HS_Fail, required-interface=PokeTRIR_b_FL_HS_Fail
      PokeTRIR_e_FL_HS_Sts: client-com-spec=PokeTRIR_e_FL_HS_Sts, required-interface=PokeTRIR_e_FL_HS_Sts
      PokeTRIR_b_FR_HS_Fail: client-com-spec=PokeTRIR_b_FR_HS_Fail, required-interface=PokeTRIR_b_FR_HS_Fail
      PokeTRIR_e_FR_HS_Sts: client-com-spec=PokeTRIR_e_FR_HS_Sts, required-interface=PokeTRIR_e_FR_HS_Sts
      FsftPLTR_e_HiBmLvr_Stat: client-com-spec=FsftPLTR_e_HiBmLvr_Stat, required-interface=FsftPLTR_e_HiBmLvr_Stat
      PokePLTR_e_HiBmLvr_Stat: client-com-spec=PokePLTR_e_HiBmLvr_Stat, required-interface=PokePLTR_e_HiBmLvr_Stat
      FsftTAIR_b_EBL_Stat: client-com-spec=FsftTAIR_b_EBL_Stat, required-interface=FsftTAIR_b_EBL_Stat
      PokeTAIR_e_RearDefrostSts: client-com-spec=PokeTAIR_e_RearDefrostSts, required-interface=PokeTAIR_e_RearDefrostSts
      FsftTAIR_T_FtEvapTmp: client-com-spec=FsftTAIR_T_FtEvapTmp, required-interface=FsftTAIR_T_FtEvapTmp
      PokeTAIR_T_FtEvapTmp: client-com-spec=PokeTAIR_T_FtEvapTmp, required-interface=PokeTAIR_T_FtEvapTmp
      FsftAATR_U_CBC_AmbientAirVolt: client-com-spec=FsftAATR_U_CBC_AmbientAirVolt, required-interface=FsftAATR_U_CBC_AmbientAirVolt
      PokeAATR_U_CBC_AmbientAirVolt: client-com-spec=PokeAATR_U_CBC_AmbientAirVolt, required-interface=PokeAATR_U_CBC_AmbientAirVolt
      TmotAATR_U_CBC_AmbientAirVolt: client-com-spec=TmotAATR_U_CBC_AmbientAirVolt, required-interface=TmotAATR_U_CBC_AmbientAirVolt
      PokeTRIR_b_FL_VS_Fail: client-com-spec=PokeTRIR_b_FL_VS_Fail, required-interface=PokeTRIR_b_FL_VS_Fail
      PokeTRIR_e_FL_VS_Sts: client-com-spec=PokeTRIR_e_FL_VS_Sts, required-interface=PokeTRIR_e_FL_VS_Sts
      PokeTRIR_b_FR_VS_Fail: client-com-spec=PokeTRIR_b_FR_VS_Fail, required-interface=PokeTRIR_b_FR_VS_Fail
      PokeTRIR_e_FR_VS_Sts: client-com-spec=PokeTRIR_e_FR_VS_Sts, required-interface=PokeTRIR_e_FR_VS_Sts
      PokeTRIR_b_HSW_Fail: client-com-spec=PokeTRIR_b_HSW_Fail, required-interface=PokeTRIR_b_HSW_Fail
      PokeTRIR_e_RL_HS_Sts: client-com-spec=PokeTRIR_e_RL_HS_Sts, required-interface=PokeTRIR_e_RL_HS_Sts
      PokeTRIR_b_RL_HS_Fail: client-com-spec=PokeTRIR_b_RL_HS_Fail, required-interface=PokeTRIR_b_RL_HS_Fail
      PokeTRIR_e_RL_VS_Sts: client-com-spec=PokeTRIR_e_RL_VS_Sts, required-interface=PokeTRIR_e_RL_VS_Sts
      PokeTRIR_b_RL_VS_Fail: client-com-spec=PokeTRIR_b_RL_VS_Fail, required-interface=PokeTRIR_b_RL_VS_Fail
      PokeTRIR_e_RR_HS_Sts: client-com-spec=PokeTRIR_e_RR_HS_Sts, required-interface=PokeTRIR_e_RR_HS_Sts
      PokeTRIR_b_RR_HS_Fail: client-com-spec=PokeTRIR_b_RR_HS_Fail, required-interface=PokeTRIR_b_RR_HS_Fail
      PokeTRIR_e_RR_VS_Sts: client-com-spec=PokeTRIR_e_RR_VS_Sts, required-interface=PokeTRIR_e_RR_VS_Sts
      PokeTRIR_b_RR_VS_Fail: client-com-spec=PokeTRIR_b_RR_VS_Fail, required-interface=PokeTRIR_b_RR_VS_Fail
      FsftPLTR_e_DriverDoorOnOffSts: client-com-spec=FsftPLTR_e_DriverDoorOnOffSts, required-interface=FsftPLTR_e_DriverDoorOnOffSts
      PokePLTR_e_DriverDoorOnOffSts: client-com-spec=PokePLTR_e_DriverDoorOnOffSts, required-interface=PokePLTR_e_DriverDoorOnOffSts
      FsftHSWR_e_RedntHdSwStat: client-com-spec=FsftHSWR_e_RedntHdSwStat, required-interface=FsftHSWR_e_RedntHdSwStat
      PokeHSWR_e_RedntHdSwStat: client-com-spec=PokeHSWR_e_RedntHdSwStat, required-interface=PokeHSWR_e_RedntHdSwStat
      FsftCITR_e_DoorLockLastElSts: client-com-spec=FsftCITR_e_DoorLockLastElSts, required-interface=FsftCITR_e_DoorLockLastElSts
      PokeCITR_e_DoorLockLastElSts: client-com-spec=PokeCITR_e_DoorLockLastElSts, required-interface=PokeCITR_e_DoorLockLastElSts
      TmotCITR_e_DoorLockLastElSts: client-com-spec=TmotCITR_e_DoorLockLastElSts, required-interface=TmotCITR_e_DoorLockLastElSts
      FsftPLTR_b_DrvDrAjar: client-com-spec=FsftPLTR_b_DrvDrAjar, required-interface=FsftPLTR_b_DrvDrAjar
      PokePLTR_b_DrvDrAjar: client-com-spec=PokePLTR_b_DrvDrAjar, required-interface=PokePLTR_b_DrvDrAjar
      FsftPLTR_b_LHRDoorSts: client-com-spec=FsftPLTR_b_LHRDoorSts, required-interface=FsftPLTR_b_LHRDoorSts
      PokePLTR_b_LHRDoorSts: client-com-spec=PokePLTR_b_LHRDoorSts, required-interface=PokePLTR_b_LHRDoorSts
      FsftPLTR_b_ParkBrakeSts: client-com-spec=FsftPLTR_b_ParkBrakeSts, required-interface=FsftPLTR_b_ParkBrakeSts
      PokePLTR_b_ParkBrakeSts: client-com-spec=PokePLTR_b_ParkBrakeSts, required-interface=PokePLTR_b_ParkBrakeSts
      PokePLTR_e_ShipingMode: client-com-spec=PokePLTR_e_ShipingMode, required-interface=PokePLTR_e_ShipingMode
      FsftPLTR_b_PsngrDoorSts: client-com-spec=FsftPLTR_b_PsngrDoorSts, required-interface=FsftPLTR_b_PsngrDoorSts
      PokePLTR_b_PsngrDoorSts: client-com-spec=PokePLTR_b_PsngrDoorSts, required-interface=PokePLTR_b_PsngrDoorSts
      FsftPLTR_b_RHRDoorSts: client-com-spec=FsftPLTR_b_RHRDoorSts, required-interface=FsftPLTR_b_RHRDoorSts
      PokePLTR_b_RHRDoorSts: client-com-spec=PokePLTR_b_RHRDoorSts, required-interface=PokePLTR_b_RHRDoorSts
      FsftTRIR_b_TrunkStatus: client-com-spec=FsftTRIR_b_TrunkStatus, required-interface=FsftTRIR_b_TrunkStatus
      FsftPLTR_b_RHatchSts: client-com-spec=FsftPLTR_b_RHatchSts, required-interface=FsftPLTR_b_RHatchSts
      PokeTRIR_b_TrunkStatus: client-com-spec=PokeTRIR_b_TrunkStatus, required-interface=PokeTRIR_b_TrunkStatus
      PokePLTR_b_RHatchSts: client-com-spec=PokePLTR_b_RHatchSts, required-interface=PokePLTR_b_RHatchSts
      PokePLTR_b_RearFogLightSts: client-com-spec=PokePLTR_b_RearFogLightSts, required-interface=PokePLTR_b_RearFogLightSts
      PokeCITR_b_HU_Sch1_ChargeUntilFull: client-com-spec=PokeCITR_b_HU_Sch1_ChargeUntilFull, required-interface=PokeCITR_b_HU_Sch1_ChargeUntilFull
      PokeCITR_b_HU_Sch2_ChargeUntilFull: client-com-spec=PokeCITR_b_HU_Sch2_ChargeUntilFull, required-interface=PokeCITR_b_HU_Sch2_ChargeUntilFull
      FsftCITR_e_HU_ChrgSchedType1: client-com-spec=FsftCITR_e_HU_ChrgSchedType1, required-interface=FsftCITR_e_HU_ChrgSchedType1
      PokeCITR_e_HU_ChrgSchedType1: client-com-spec=PokeCITR_e_HU_ChrgSchedType1, required-interface=PokeCITR_e_HU_ChrgSchedType1
      FsftCITR_e_HU_ChrgSchedType2: client-com-spec=FsftCITR_e_HU_ChrgSchedType2, required-interface=FsftCITR_e_HU_ChrgSchedType2
      PokeCITR_e_HU_ChrgSchedType2: client-com-spec=PokeCITR_e_HU_ChrgSchedType2, required-interface=PokeCITR_e_HU_ChrgSchedType2
      PokeCITR_b_HU_Sch1_Enbl: client-com-spec=PokeCITR_b_HU_Sch1_Enbl, required-interface=PokeCITR_b_HU_Sch1_Enbl
      PokeCITR_b_HU_Sch2_Enbl: client-com-spec=PokeCITR_b_HU_Sch2_Enbl, required-interface=PokeCITR_b_HU_Sch2_Enbl
      FsftCITR_b_HU_Sch1_End_Time_Hr: client-com-spec=FsftCITR_b_HU_Sch1_End_Time_Hr, required-interface=FsftCITR_b_HU_Sch1_End_Time_Hr
      PokeCITR_K_HU_Sch1_End_Time_Hr: client-com-spec=PokeCITR_K_HU_Sch1_End_Time_Hr, required-interface=PokeCITR_K_HU_Sch1_End_Time_Hr
      FsftCITR_b_HU_Sch2_End_Time_Hr: client-com-spec=FsftCITR_b_HU_Sch2_End_Time_Hr, required-interface=FsftCITR_b_HU_Sch2_End_Time_Hr
      PokeCITR_K_HU_Sch2_End_Time_Hr: client-com-spec=PokeCITR_K_HU_Sch2_End_Time_Hr, required-interface=PokeCITR_K_HU_Sch2_End_Time_Hr
      FsftCITR_b_HU_Sch1_End_Time_Min: client-com-spec=FsftCITR_b_HU_Sch1_End_Time_Min, required-interface=FsftCITR_b_HU_Sch1_End_Time_Min
      PokeCITR_K_HU_Sch1_End_Time_Min: client-com-spec=PokeCITR_K_HU_Sch1_End_Time_Min, required-interface=PokeCITR_K_HU_Sch1_End_Time_Min
      FsftCITR_b_HU_Sch2_End_Time_Min: client-com-spec=FsftCITR_b_HU_Sch2_End_Time_Min, required-interface=FsftCITR_b_HU_Sch2_End_Time_Min
      PokeCITR_K_HU_Sch2_End_Time_Min: client-com-spec=PokeCITR_K_HU_Sch2_End_Time_Min, required-interface=PokeCITR_K_HU_Sch2_End_Time_Min
      FsftCITR_Pct_HU_ExtChrgTarget1: client-com-spec=FsftCITR_Pct_HU_ExtChrgTarget1, required-interface=FsftCITR_Pct_HU_ExtChrgTarget1
      PokeCITR_Pct_HU_ExtChrgTarget1: client-com-spec=PokeCITR_Pct_HU_ExtChrgTarget1, required-interface=PokeCITR_Pct_HU_ExtChrgTarget1
      FsftCITR_Pct_HU_ExtChrgTarget2: client-com-spec=FsftCITR_Pct_HU_ExtChrgTarget2, required-interface=FsftCITR_Pct_HU_ExtChrgTarget2
      PokeCITR_Pct_HU_ExtChrgTarget2: client-com-spec=PokeCITR_Pct_HU_ExtChrgTarget2, required-interface=PokeCITR_Pct_HU_ExtChrgTarget2
      FsftCITR_Pct_HU_ImmChrgTarget1: client-com-spec=FsftCITR_Pct_HU_ImmChrgTarget1, required-interface=FsftCITR_Pct_HU_ImmChrgTarget1
      PokeCITR_Pct_HU_ImmChrgTarget1: client-com-spec=PokeCITR_Pct_HU_ImmChrgTarget1, required-interface=PokeCITR_Pct_HU_ImmChrgTarget1
      FsftCITR_Pct_HU_ImmChrgTarget2: client-com-spec=FsftCITR_Pct_HU_ImmChrgTarget2, required-interface=FsftCITR_Pct_HU_ImmChrgTarget2
      PokeCITR_Pct_HU_ImmChrgTarget2: client-com-spec=PokeCITR_Pct_HU_ImmChrgTarget2, required-interface=PokeCITR_Pct_HU_ImmChrgTarget2
      FsftCITR_b_HU_Sch1_Day: client-com-spec=FsftCITR_b_HU_Sch1_Day, required-interface=FsftCITR_b_HU_Sch1_Day
      PokeCITR_K_HU_Sch1_Day: client-com-spec=PokeCITR_K_HU_Sch1_Day, required-interface=PokeCITR_K_HU_Sch1_Day
      TmotCITR_b_HU_Sch1_Day: client-com-spec=TmotCITR_b_HU_Sch1_Day, required-interface=TmotCITR_b_HU_Sch1_Day
      FsftCITR_b_HU_Sch2_Day: client-com-spec=FsftCITR_b_HU_Sch2_Day, required-interface=FsftCITR_b_HU_Sch2_Day
      PokeCITR_K_HU_Sch2_Day: client-com-spec=PokeCITR_K_HU_Sch2_Day, required-interface=PokeCITR_K_HU_Sch2_Day
      TmotCITR_b_HU_Sch2_Day: client-com-spec=TmotCITR_b_HU_Sch2_Day, required-interface=TmotCITR_b_HU_Sch2_Day
      FsftCITR_b_HU_Sch1_Start_Time_Hr: client-com-spec=FsftCITR_b_HU_Sch1_Start_Time_Hr, required-interface=FsftCITR_b_HU_Sch1_Start_Time_Hr
      PokeCITR_K_HU_Sch1_Start_Time_Hr: client-com-spec=PokeCITR_K_HU_Sch1_Start_Time_Hr, required-interface=PokeCITR_K_HU_Sch1_Start_Time_Hr
      FsftCITR_b_HU_Sch2_Start_Time_Hr: client-com-spec=FsftCITR_b_HU_Sch2_Start_Time_Hr, required-interface=FsftCITR_b_HU_Sch2_Start_Time_Hr
      PokeCITR_K_HU_Sch2_Start_Time_Hr: client-com-spec=PokeCITR_K_HU_Sch2_Start_Time_Hr, required-interface=PokeCITR_K_HU_Sch2_Start_Time_Hr
      FsftCITR_b_HU_Sch1_Start_Time_Min: client-com-spec=FsftCITR_b_HU_Sch1_Start_Time_Min, required-interface=FsftCITR_b_HU_Sch1_Start_Time_Min
      PokeCITR_K_HU_Sch1_Start_Time_Min: client-com-spec=PokeCITR_K_HU_Sch1_Start_Time_Min, required-interface=PokeCITR_K_HU_Sch1_Start_Time_Min
      FsftCITR_b_HU_Sch2_Start_Time_Min: client-com-spec=FsftCITR_b_HU_Sch2_Start_Time_Min, required-interface=FsftCITR_b_HU_Sch2_Start_Time_Min
      PokeCITR_K_HU_Sch2_Start_Time_Min: client-com-spec=PokeCITR_K_HU_Sch2_Start_Time_Min, required-interface=PokeCITR_K_HU_Sch2_Start_Time_Min
      PokeCITR_b_HU_Sch1_Submit: client-com-spec=PokeCITR_b_HU_Sch1_Submit, required-interface=PokeCITR_b_HU_Sch1_Submit
      PokeCITR_b_HU_Sch2_Submit: client-com-spec=PokeCITR_b_HU_Sch2_Submit, required-interface=PokeCITR_b_HU_Sch2_Submit
      FsftCITR_b_HU_Sch3_Allow: client-com-spec=FsftCITR_b_HU_Sch3_Allow, required-interface=FsftCITR_b_HU_Sch3_Allow
      PokeCITR_e_HU_Sch3_Allow: client-com-spec=PokeCITR_e_HU_Sch3_Allow, required-interface=PokeCITR_e_HU_Sch3_Allow
      FsftCITR_b_HU_Sch4_Allow: client-com-spec=FsftCITR_b_HU_Sch4_Allow, required-interface=FsftCITR_b_HU_Sch4_Allow
      PokeCITR_e_HU_Sch4_Allow: client-com-spec=PokeCITR_e_HU_Sch4_Allow, required-interface=PokeCITR_e_HU_Sch4_Allow
      FsftCITR_b_HU_Sch3_Day: client-com-spec=FsftCITR_b_HU_Sch3_Day, required-interface=FsftCITR_b_HU_Sch3_Day
      PokeCITR_K_HU_Sch3_Day: client-com-spec=PokeCITR_K_HU_Sch3_Day, required-interface=PokeCITR_K_HU_Sch3_Day
      TmotCITR_b_HU_Sch3_Day: client-com-spec=TmotCITR_b_HU_Sch3_Day, required-interface=TmotCITR_b_HU_Sch3_Day
      FsftCITR_b_HU_Sch3_Start_Time_Hr: client-com-spec=FsftCITR_b_HU_Sch3_Start_Time_Hr, required-interface=FsftCITR_b_HU_Sch3_Start_Time_Hr
      PokeCITR_K_HU_Sch3_Start_Time_Hr: client-com-spec=PokeCITR_K_HU_Sch3_Start_Time_Hr, required-interface=PokeCITR_K_HU_Sch3_Start_Time_Hr
      FsftCITR_b_HU_Sch3_Start_Time_Min: client-com-spec=FsftCITR_b_HU_Sch3_Start_Time_Min, required-interface=FsftCITR_b_HU_Sch3_Start_Time_Min
      PokeCITR_K_HU_Sch3_Start_Time_Min: client-com-spec=PokeCITR_K_HU_Sch3_Start_Time_Min, required-interface=PokeCITR_K_HU_Sch3_Start_Time_Min
      FsftCITR_b_HU_Sch4_Day: client-com-spec=FsftCITR_b_HU_Sch4_Day, required-interface=FsftCITR_b_HU_Sch4_Day
      PokeCITR_K_HU_Sch4_Day: client-com-spec=PokeCITR_K_HU_Sch4_Day, required-interface=PokeCITR_K_HU_Sch4_Day
      TmotCITR_b_HU_Sch4_Day: client-com-spec=TmotCITR_b_HU_Sch4_Day, required-interface=TmotCITR_b_HU_Sch4_Day
      FsftCITR_b_HU_Sch4_Start_Time_Hr: client-com-spec=FsftCITR_b_HU_Sch4_Start_Time_Hr, required-interface=FsftCITR_b_HU_Sch4_Start_Time_Hr
      PokeCITR_K_HU_Sch4_Start_Time_Hr: client-com-spec=PokeCITR_K_HU_Sch4_Start_Time_Hr, required-interface=PokeCITR_K_HU_Sch4_Start_Time_Hr
      FsftCITR_b_HU_Sch4_Start_Time_Min: client-com-spec=FsftCITR_b_HU_Sch4_Start_Time_Min, required-interface=FsftCITR_b_HU_Sch4_Start_Time_Min
      PokeCITR_K_HU_Sch4_Start_Time_Min: client-com-spec=PokeCITR_K_HU_Sch4_Start_Time_Min, required-interface=PokeCITR_K_HU_Sch4_Start_Time_Min
      FsftCITR_b_HU_Sch3_CabTemp: client-com-spec=FsftCITR_b_HU_Sch3_CabTemp, required-interface=FsftCITR_b_HU_Sch3_CabTemp
      PokeCITR_T_HU_Sch3_CabTemp: client-com-spec=PokeCITR_T_HU_Sch3_CabTemp, required-interface=PokeCITR_T_HU_Sch3_CabTemp
      FsftCITR_b_HU_Sch4_CabTemp: client-com-spec=FsftCITR_b_HU_Sch4_CabTemp, required-interface=FsftCITR_b_HU_Sch4_CabTemp
      PokeCITR_T_HU_Sch4_CabTemp: client-com-spec=PokeCITR_T_HU_Sch4_CabTemp, required-interface=PokeCITR_T_HU_Sch4_CabTemp
      PokeCITR_b_HU_Sch3_Enbl: client-com-spec=PokeCITR_b_HU_Sch3_Enbl, required-interface=PokeCITR_b_HU_Sch3_Enbl
      PokeCITR_b_HU_Sch4_Enbl: client-com-spec=PokeCITR_b_HU_Sch4_Enbl, required-interface=PokeCITR_b_HU_Sch4_Enbl
      PokeCITR_b_HU_Sch3_Submit: client-com-spec=PokeCITR_b_HU_Sch3_Submit, required-interface=PokeCITR_b_HU_Sch3_Submit
      PokeCITR_b_HU_Sch4_Submit: client-com-spec=PokeCITR_b_HU_Sch4_Submit, required-interface=PokeCITR_b_HU_Sch4_Submit
      FsftCITR_b_TBM_Sch3_CabTemp: client-com-spec=FsftCITR_b_TBM_Sch3_CabTemp, required-interface=FsftCITR_b_TBM_Sch3_CabTemp
      PokeCITR_T_TBM_Sch3_CabTemp: client-com-spec=PokeCITR_T_TBM_Sch3_CabTemp, required-interface=PokeCITR_T_TBM_Sch3_CabTemp
      FsftCITR_b_TBM_Sch4_CabTemp: client-com-spec=FsftCITR_b_TBM_Sch4_CabTemp, required-interface=FsftCITR_b_TBM_Sch4_CabTemp
      PokeCITR_T_TBM_Sch4_CabTemp: client-com-spec=PokeCITR_T_TBM_Sch4_CabTemp, required-interface=PokeCITR_T_TBM_Sch4_CabTemp
      FsftCITR_b_TBM_Sch3_Allow: client-com-spec=FsftCITR_b_TBM_Sch3_Allow, required-interface=FsftCITR_b_TBM_Sch3_Allow
      PokeCITR_e_TBM_Sch3_Allow: client-com-spec=PokeCITR_e_TBM_Sch3_Allow, required-interface=PokeCITR_e_TBM_Sch3_Allow
      FsftCITR_b_TBM_Sch4_Allow: client-com-spec=FsftCITR_b_TBM_Sch4_Allow, required-interface=FsftCITR_b_TBM_Sch4_Allow
      PokeCITR_e_TBM_Sch4_Allow: client-com-spec=PokeCITR_e_TBM_Sch4_Allow, required-interface=PokeCITR_e_TBM_Sch4_Allow
      FsftCITR_b_TBM_Sch3_Day: client-com-spec=FsftCITR_b_TBM_Sch3_Day, required-interface=FsftCITR_b_TBM_Sch3_Day
      PokeCITR_K_TBM_Sch3_Day: client-com-spec=PokeCITR_K_TBM_Sch3_Day, required-interface=PokeCITR_K_TBM_Sch3_Day
      TmotCITR_b_TBM_Sch3_Day: client-com-spec=TmotCITR_b_TBM_Sch3_Day, required-interface=TmotCITR_b_TBM_Sch3_Day
      FsftCITR_b_TBM_Sch3_Start_Time_Hr: client-com-spec=FsftCITR_b_TBM_Sch3_Start_Time_Hr, required-interface=FsftCITR_b_TBM_Sch3_Start_Time_Hr
      PokeCITR_K_TBM_Sch3_Start_Time_Hr: client-com-spec=PokeCITR_K_TBM_Sch3_Start_Time_Hr, required-interface=PokeCITR_K_TBM_Sch3_Start_Time_Hr
      FsftCITR_b_TBM_Sch3_Start_Time_Min: client-com-spec=FsftCITR_b_TBM_Sch3_Start_Time_Min, required-interface=FsftCITR_b_TBM_Sch3_Start_Time_Min
      PokeCITR_K_TBM_Sch3_Start_Time_Min: client-com-spec=PokeCITR_K_TBM_Sch3_Start_Time_Min, required-interface=PokeCITR_K_TBM_Sch3_Start_Time_Min
      FsftCITR_b_TBM_Sch4_Day: client-com-spec=FsftCITR_b_TBM_Sch4_Day, required-interface=FsftCITR_b_TBM_Sch4_Day
      PokeCITR_K_TBM_Sch4_Day: client-com-spec=PokeCITR_K_TBM_Sch4_Day, required-interface=PokeCITR_K_TBM_Sch4_Day
      TmotCITR_b_TBM_Sch4_Day: client-com-spec=TmotCITR_b_TBM_Sch4_Day, required-interface=TmotCITR_b_TBM_Sch4_Day
      FsftCITR_b_TBM_Sch4_Start_Time_Hr: client-com-spec=FsftCITR_b_TBM_Sch4_Start_Time_Hr, required-interface=FsftCITR_b_TBM_Sch4_Start_Time_Hr
      PokeCITR_K_TBM_Sch4_Start_Time_Hr: client-com-spec=PokeCITR_K_TBM_Sch4_Start_Time_Hr, required-interface=PokeCITR_K_TBM_Sch4_Start_Time_Hr
      FsftCITR_b_TBM_Sch4_Start_Time_Min: client-com-spec=FsftCITR_b_TBM_Sch4_Start_Time_Min, required-interface=FsftCITR_b_TBM_Sch4_Start_Time_Min
      PokeCITR_K_TBM_Sch4_Start_Time_Min: client-com-spec=PokeCITR_K_TBM_Sch4_Start_Time_Min, required-interface=PokeCITR_K_TBM_Sch4_Start_Time_Min
      PokeCITR_b_TBM_Sch3_Enbl: client-com-spec=PokeCITR_b_TBM_Sch3_Enbl, required-interface=PokeCITR_b_TBM_Sch3_Enbl
      PokeCITR_b_TBM_Sch4_Enbl: client-com-spec=PokeCITR_b_TBM_Sch4_Enbl, required-interface=PokeCITR_b_TBM_Sch4_Enbl
      PokeCITR_b_TBM_Sch3_Submit: client-com-spec=PokeCITR_b_TBM_Sch3_Submit, required-interface=PokeCITR_b_TBM_Sch3_Submit
      PokeCITR_b_TBM_Sch4_Submit: client-com-spec=PokeCITR_b_TBM_Sch4_Submit, required-interface=PokeCITR_b_TBM_Sch4_Submit
      FsftCITR_e_FOTA_Install_Type: client-com-spec=FsftCITR_e_FOTA_Install_Type, required-interface=FsftCITR_e_FOTA_Install_Type
      PokeCITR_e_FOTA_Install_Type: client-com-spec=PokeCITR_e_FOTA_Install_Type, required-interface=PokeCITR_e_FOTA_Install_Type
      PokeCITR_e_FOTA_Installation_Status: client-com-spec=PokeCITR_e_FOTA_Installation_Status, required-interface=PokeCITR_e_FOTA_Installation_Status
      FsftIDCR_e_IBS_Current_Status: client-com-spec=FsftIDCR_e_IBS_Current_Status, required-interface=FsftIDCR_e_IBS_Current_Status
      PokeIDCR_e_IBS_Current_Status: client-com-spec=PokeIDCR_e_IBS_Current_Status, required-interface=PokeIDCR_e_IBS_Current_Status
      FsftIDCR_b_IBS_b_Batt: client-com-spec=FsftIDCR_b_IBS_b_Batt, required-interface=FsftIDCR_b_IBS_b_Batt
      PokeIDCR_I_IBS_I_Batt: client-com-spec=PokeIDCR_I_IBS_I_Batt, required-interface=PokeIDCR_I_IBS_I_Batt
      TmotIDCR_I_IBS_I_Batt: client-com-spec=TmotIDCR_I_IBS_I_Batt, required-interface=TmotIDCR_I_IBS_I_Batt
      FsftIDCR_U_IBS_BattVolt: client-com-spec=FsftIDCR_U_IBS_BattVolt, required-interface=FsftIDCR_U_IBS_BattVolt
      PokeIDCR_U_IBS_BattVolt: client-com-spec=PokeIDCR_U_IBS_BattVolt, required-interface=PokeIDCR_U_IBS_BattVolt
      PokeIDCR_e_IBS_BattVoltSts: client-com-spec=PokeIDCR_e_IBS_BattVoltSts, required-interface=PokeIDCR_e_IBS_BattVoltSts
      FsftIDCR_Pct_IBS_BattSOC: client-com-spec=FsftIDCR_Pct_IBS_BattSOC, required-interface=FsftIDCR_Pct_IBS_BattSOC
      PokeIDCR_Pct_IBS_BattSOC: client-com-spec=PokeIDCR_Pct_IBS_BattSOC, required-interface=PokeIDCR_Pct_IBS_BattSOC
      PokeIDCR_e_IBS_BattSocAcc: client-com-spec=PokeIDCR_e_IBS_BattSocAcc, required-interface=PokeIDCR_e_IBS_BattSocAcc
      FsftIDCR_b_IBS_BattTemp: client-com-spec=FsftIDCR_b_IBS_BattTemp, required-interface=FsftIDCR_b_IBS_BattTemp
      PokeIDCR_t_IBS_BattTemp: client-com-spec=PokeIDCR_t_IBS_BattTemp, required-interface=PokeIDCR_t_IBS_BattTemp
      TmotIDCR_b_IBS_BattTemp: client-com-spec=TmotIDCR_b_IBS_BattTemp, required-interface=TmotIDCR_b_IBS_BattTemp
      PokeIDCR_e_IBS_BattTempSts: client-com-spec=PokeIDCR_e_IBS_BattTempSts, required-interface=PokeIDCR_e_IBS_BattTempSts
      FsftIMPR_b_VehImpactDetected_C2: client-com-spec=FsftIMPR_b_VehImpactDetected_C2, required-interface=FsftIMPR_b_VehImpactDetected_C2
      PokeIMPR_b_VehImpactDetected_C2: client-com-spec=PokeIMPR_b_VehImpactDetected_C2, required-interface=PokeIMPR_b_VehImpactDetected_C2
      FsftIMPR_b_ImpactToggle_C2: client-com-spec=FsftIMPR_b_ImpactToggle_C2, required-interface=FsftIMPR_b_ImpactToggle_C2
      PokeIMPR_b_ImpactToggle_C2: client-com-spec=PokeIMPR_b_ImpactToggle_C2, required-interface=PokeIMPR_b_ImpactToggle_C2
      FsftPLTR_l_Odometer_Km: client-com-spec=FsftPLTR_l_Odometer_Km, required-interface=FsftPLTR_l_Odometer_Km
      PokePLTR_l_Odometer_Km: client-com-spec=PokePLTR_l_Odometer_Km, required-interface=PokePLTR_l_Odometer_Km
      FsftASLR_b_DsplydSpdLimSts: client-com-spec=FsftASLR_b_DsplydSpdLimSts, required-interface=FsftASLR_b_DsplydSpdLimSts
      PokeASLR_e_DsplydSpdLimSts: client-com-spec=PokeASLR_e_DsplydSpdLimSts, required-interface=PokeASLR_e_DsplydSpdLimSts
      FsftCITR_b_DC_PwrLev: variation-point={short-label=vpFsftCITR_b_DC_PwrLev, sw-syscond=1}, client-com-spec=FsftCITR_b_DC_PwrLev, required-interface=FsftCITR_b_DC_PwrLev
      PokeCITR_b_DC_PwrLev: variation-point={short-label=vpPokeCITR_b_DC_PwrLev, sw-syscond=1}, client-com-spec=PokeCITR_b_DC_PwrLev, required-interface=PokeCITR_b_DC_PwrLev
      TmotCITR_b_DC_PwrLev: variation-point={short-label=vpTmotCITR_b_DC_PwrLev, sw-syscond=1}, client-com-spec=TmotCITR_b_DC_PwrLev, required-interface=TmotCITR_b_DC_PwrLev
      FsftCITR_e_PowerLimitReq: client-com-spec=FsftCITR_e_PowerLimitReq, required-interface=FsftCITR_e_PowerLimitReq
      PokeCITR_e_PowerLimit_Req: client-com-spec=PokeCITR_e_PowerLimit_Req, required-interface=PokeCITR_e_PowerLimit_Req
      TmotCITR_e_PowerLimitReq: client-com-spec=TmotCITR_e_PowerLimitReq, required-interface=TmotCITR_e_PowerLimitReq
      FsftCITR_b_SOC_Max_Lev: client-com-spec=FsftCITR_b_SOC_Max_Lev, required-interface=FsftCITR_b_SOC_Max_Lev
      PokeCITR_b_SOC_Max_Lev: client-com-spec=PokeCITR_b_SOC_Max_Lev, required-interface=PokeCITR_b_SOC_Max_Lev
      PokePLTR_b_SpeedUnit: client-com-spec=PokePLTR_b_SpeedUnit, required-interface=PokePLTR_b_SpeedUnit
      PokeASLR_b_TSR_Req: client-com-spec=PokeASLR_b_TSR_Req, required-interface=PokeASLR_b_TSR_Req
      PokeDMIR_e_CreepSts: variation-point={short-label=vpPokeDMIR_e_CreepSts, sw-syscond=1}, client-com-spec=PokeDMIR_e_CreepSts, required-interface=PokeDMIR_e_CreepSts
      FsftPLTR_e_DriverSeatBeltSts: client-com-spec=FsftPLTR_e_DriverSeatBeltSts, required-interface=FsftPLTR_e_DriverSeatBeltSts
      PokePLTR_b_DriverSeatBeltSts: client-com-spec=PokePLTR_b_DriverSeatBeltSts, required-interface=PokePLTR_b_DriverSeatBeltSts
      FsftPMDR_b_EngOffRq_C: client-com-spec=FsftPMDR_b_EngOffRq_C, required-interface=FsftPMDR_b_EngOffRq_C
      PokePMDR_b_EngOffRq_C: client-com-spec=PokePMDR_b_EngOffRq_C, required-interface=PokePMDR_b_EngOffRq_C
      FsftPLTR_y_FobSearchResult: client-com-spec=FsftPLTR_y_FobSearchResult, required-interface=FsftPLTR_y_FobSearchResult
      PokePLTR_y_FobSearchResult: client-com-spec=PokePLTR_y_FobSearchResult, required-interface=PokePLTR_y_FobSearchResult
      FsftCITR_b_CoopCh_VehLocation: client-com-spec=FsftCITR_b_CoopCh_VehLocation, required-interface=FsftCITR_b_CoopCh_VehLocation
      PokeCITR_b_CoopCh_VehLocation: client-com-spec=PokeCITR_b_CoopCh_VehLocation, required-interface=PokeCITR_b_CoopCh_VehLocation
      FsftCITR_e_RmtChrgPortLkCmd: client-com-spec=FsftCITR_e_RmtChrgPortLkCmd, required-interface=FsftCITR_e_RmtChrgPortLkCmd
      PokeCITR_e_RmtChrgPortLkCmd: client-com-spec=PokeCITR_e_RmtChrgPortLkCmd, required-interface=PokeCITR_e_RmtChrgPortLkCmd
      TmotCITR_e_RmtChrgPortLkCmd: client-com-spec=TmotCITR_e_RmtChrgPortLkCmd, required-interface=TmotCITR_e_RmtChrgPortLkCmd
      FsftCITR_e_CoopCh_ChrgCmd: client-com-spec=FsftCITR_e_CoopCh_ChrgCmd, required-interface=FsftCITR_e_CoopCh_ChrgCmd
      PokeCITR_e_CoopCh_ChrgCmd: client-com-spec=PokeCITR_e_CoopCh_ChrgCmd, required-interface=PokeCITR_e_CoopCh_ChrgCmd
      FsftCITR_b_TBMStopChrg: client-com-spec=FsftCITR_b_TBMStopChrg, required-interface=FsftCITR_b_TBMStopChrg
      PokeCITR_b_TBMStopChrg: client-com-spec=PokeCITR_b_TBMStopChrg, required-interface=PokeCITR_b_TBMStopChrg
      FsftCITR_e_TBM_ChrgSchedType1: client-com-spec=FsftCITR_e_TBM_ChrgSchedType1, required-interface=FsftCITR_e_TBM_ChrgSchedType1
      PokeCITR_e_TBM_ChrgSchedType1: client-com-spec=PokeCITR_e_TBM_ChrgSchedType1, required-interface=PokeCITR_e_TBM_ChrgSchedType1
      FsftCITR_e_TBM_ChrgSchedType2: client-com-spec=FsftCITR_e_TBM_ChrgSchedType2, required-interface=FsftCITR_e_TBM_ChrgSchedType2
      PokeCITR_e_TBM_ChrgSchedType2: client-com-spec=PokeCITR_e_TBM_ChrgSchedType2, required-interface=PokeCITR_e_TBM_ChrgSchedType2
      PokeCITR_b_TBM_Sch1_ChargeUntilFull: client-com-spec=PokeCITR_b_TBM_Sch1_ChargeUntilFull, required-interface=PokeCITR_b_TBM_Sch1_ChargeUntilFull
      PokeCITR_b_TBM_Sch2_ChargeUntilFull: client-com-spec=PokeCITR_b_TBM_Sch2_ChargeUntilFull, required-interface=PokeCITR_b_TBM_Sch2_ChargeUntilFull
      PokeCITR_b_TBM_Charge_Now: client-com-spec=PokeCITR_b_TBM_Charge_Now, required-interface=PokeCITR_b_TBM_Charge_Now
      PokeCITR_b_TBM_Sch1_Enbl: client-com-spec=PokeCITR_b_TBM_Sch1_Enbl, required-interface=PokeCITR_b_TBM_Sch1_Enbl
      PokeCITR_b_TBM_Sch2_Enbl: client-com-spec=PokeCITR_b_TBM_Sch2_Enbl, required-interface=PokeCITR_b_TBM_Sch2_Enbl
      FsftCITR_b_TBM_Sch1_End_Time_Hr: client-com-spec=FsftCITR_b_TBM_Sch1_End_Time_Hr, required-interface=FsftCITR_b_TBM_Sch1_End_Time_Hr
      PokeCITR_K_TBM_Sch1_End_Time_Hr: client-com-spec=PokeCITR_K_TBM_Sch1_End_Time_Hr, required-interface=PokeCITR_K_TBM_Sch1_End_Time_Hr
      FsftCITR_b_TBM_Sch2_End_Time_Hr: client-com-spec=FsftCITR_b_TBM_Sch2_End_Time_Hr, required-interface=FsftCITR_b_TBM_Sch2_End_Time_Hr
      PokeCITR_K_TBM_Sch2_End_Time_Hr: client-com-spec=PokeCITR_K_TBM_Sch2_End_Time_Hr, required-interface=PokeCITR_K_TBM_Sch2_End_Time_Hr
      FsftCITR_b_TBM_Sch1_End_Time_Min: client-com-spec=FsftCITR_b_TBM_Sch1_End_Time_Min, required-interface=FsftCITR_b_TBM_Sch1_End_Time_Min
      PokeCITR_K_TBM_Sch1_End_Time_Min: client-com-spec=PokeCITR_K_TBM_Sch1_End_Time_Min, required-interface=PokeCITR_K_TBM_Sch1_End_Time_Min
      FsftCITR_b_TBM_Sch2_End_Time_Min: client-com-spec=FsftCITR_b_TBM_Sch2_End_Time_Min, required-interface=FsftCITR_b_TBM_Sch2_End_Time_Min
      PokeCITR_K_TBM_Sch2_End_Time_Min: client-com-spec=PokeCITR_K_TBM_Sch2_End_Time_Min, required-interface=PokeCITR_K_TBM_Sch2_End_Time_Min
      FsftCITR_Pct_TBM_ExtChrgTarget1: client-com-spec=FsftCITR_Pct_TBM_ExtChrgTarget1, required-interface=FsftCITR_Pct_TBM_ExtChrgTarget1
      PokeCITR_Pct_TBM_ExtChrgTarget1: client-com-spec=PokeCITR_Pct_TBM_ExtChrgTarget1, required-interface=PokeCITR_Pct_TBM_ExtChrgTarget1
      FsftCITR_Pct_TBM_ExtChrgTarget2: client-com-spec=FsftCITR_Pct_TBM_ExtChrgTarget2, required-interface=FsftCITR_Pct_TBM_ExtChrgTarget2
      PokeCITR_Pct_TBM_ExtChrgTarget2: client-com-spec=PokeCITR_Pct_TBM_ExtChrgTarget2, required-interface=PokeCITR_Pct_TBM_ExtChrgTarget2
      FsftCITR_Pct_TBM_ImmChrgTarget1: client-com-spec=FsftCITR_Pct_TBM_ImmChrgTarget1, required-interface=FsftCITR_Pct_TBM_ImmChrgTarget1
      PokeCITR_Pct_TBM_ImmChrgTarget1: client-com-spec=PokeCITR_Pct_TBM_ImmChrgTarget1, required-interface=PokeCITR_Pct_TBM_ImmChrgTarget1
      FsftCITR_Pct_TBM_ImmChrgTarget2: client-com-spec=FsftCITR_Pct_TBM_ImmChrgTarget2, required-interface=FsftCITR_Pct_TBM_ImmChrgTarget2
      PokeCITR_Pct_TBM_ImmChrgTarget2: client-com-spec=PokeCITR_Pct_TBM_ImmChrgTarget2, required-interface=PokeCITR_Pct_TBM_ImmChrgTarget2
      FsftCITR_b_TBM_Sch1_Day: client-com-spec=FsftCITR_b_TBM_Sch1_Day, required-interface=FsftCITR_b_TBM_Sch1_Day
      PokeCITR_K_TBM_Sch1_Day: client-com-spec=PokeCITR_K_TBM_Sch1_Day, required-interface=PokeCITR_K_TBM_Sch1_Day
      TmotCITR_b_TBM_Sch1_Day: client-com-spec=TmotCITR_b_TBM_Sch1_Day, required-interface=TmotCITR_b_TBM_Sch1_Day
      FsftCITR_b_TBM_Sch2_Day: client-com-spec=FsftCITR_b_TBM_Sch2_Day, required-interface=FsftCITR_b_TBM_Sch2_Day
      PokeCITR_K_TBM_Sch2_Day: client-com-spec=PokeCITR_K_TBM_Sch2_Day, required-interface=PokeCITR_K_TBM_Sch2_Day
      TmotCITR_b_TBM_Sch2_Day: client-com-spec=TmotCITR_b_TBM_Sch2_Day, required-interface=TmotCITR_b_TBM_Sch2_Day
      FsftCITR_b_TBM_Sch1_Start_Time_Hr: client-com-spec=FsftCITR_b_TBM_Sch1_Start_Time_Hr, required-interface=FsftCITR_b_TBM_Sch1_Start_Time_Hr
      PokeCITR_K_TBM_Sch1_Start_Time_Hr: client-com-spec=PokeCITR_K_TBM_Sch1_Start_Time_Hr, required-interface=PokeCITR_K_TBM_Sch1_Start_Time_Hr
      FsftCITR_b_TBM_Sch2_Start_Time_Hr: client-com-spec=FsftCITR_b_TBM_Sch2_Start_Time_Hr, required-interface=FsftCITR_b_TBM_Sch2_Start_Time_Hr
      PokeCITR_K_TBM_Sch2_Start_Time_Hr: client-com-spec=PokeCITR_K_TBM_Sch2_Start_Time_Hr, required-interface=PokeCITR_K_TBM_Sch2_Start_Time_Hr
      FsftCITR_b_TBM_Sch1_Start_Time_Min: client-com-spec=FsftCITR_b_TBM_Sch1_Start_Time_Min, required-interface=FsftCITR_b_TBM_Sch1_Start_Time_Min
      PokeCITR_K_TBM_Sch1_Start_Time_Min: client-com-spec=PokeCITR_K_TBM_Sch1_Start_Time_Min, required-interface=PokeCITR_K_TBM_Sch1_Start_Time_Min
      FsftCITR_b_TBM_Sch2_Start_Time_Min: client-com-spec=FsftCITR_b_TBM_Sch2_Start_Time_Min, required-interface=FsftCITR_b_TBM_Sch2_Start_Time_Min
      PokeCITR_K_TBM_Sch2_Start_Time_Min: client-com-spec=PokeCITR_K_TBM_Sch2_Start_Time_Min, required-interface=PokeCITR_K_TBM_Sch2_Start_Time_Min
      PokeCITR_b_TBM_Sch1_Submit: client-com-spec=PokeCITR_b_TBM_Sch1_Submit, required-interface=PokeCITR_b_TBM_Sch1_Submit
      PokeCITR_b_TBM_Sch2_Submit: client-com-spec=PokeCITR_b_TBM_Sch2_Submit, required-interface=PokeCITR_b_TBM_Sch2_Submit
      FsftCITR_b_Date_Day1: client-com-spec=FsftCITR_b_Date_Day1, required-interface=FsftCITR_b_Date_Day1
      PokeCITR_K_Date_Day1: client-com-spec=PokeCITR_K_Date_Day1, required-interface=PokeCITR_K_Date_Day1
      TmotCITR_b_Date_Day1: client-com-spec=TmotCITR_b_Date_Day1, required-interface=TmotCITR_b_Date_Day1
      PokeCITR_K_Date_Day2: client-com-spec=PokeCITR_K_Date_Day2, required-interface=PokeCITR_K_Date_Day2
      FsftPLTR_tdy_GPS_Date_Day: client-com-spec=FsftPLTR_tdy_GPS_Date_Day, required-interface=FsftPLTR_tdy_GPS_Date_Day
      PokePLTR_tdy_GPS_Date_Day: client-com-spec=PokePLTR_tdy_GPS_Date_Day, required-interface=PokePLTR_tdy_GPS_Date_Day
      FsftPLTR_tmt_GPS_Date_Month: client-com-spec=FsftPLTR_tmt_GPS_Date_Month, required-interface=FsftPLTR_tmt_GPS_Date_Month
      PokePLTR_tmt_GPS_Date_Month: client-com-spec=PokePLTR_tmt_GPS_Date_Month, required-interface=PokePLTR_tmt_GPS_Date_Month
      FsftPLTR_tyr_GPS_Date_Year: client-com-spec=FsftPLTR_tyr_GPS_Date_Year, required-interface=FsftPLTR_tyr_GPS_Date_Year
      PokePLTR_tyr_GPS_Date_Year: client-com-spec=PokePLTR_tyr_GPS_Date_Year, required-interface=PokePLTR_tyr_GPS_Date_Year
      FsftPLTR_thr_GPS_UTC_Hour: client-com-spec=FsftPLTR_thr_GPS_UTC_Hour, required-interface=FsftPLTR_thr_GPS_UTC_Hour
      PokePLTR_thr_GPS_UTC_Hour: client-com-spec=PokePLTR_thr_GPS_UTC_Hour, required-interface=PokePLTR_thr_GPS_UTC_Hour
      FsftPLTR_tmn_GPS_UTC_Minute: client-com-spec=FsftPLTR_tmn_GPS_UTC_Minute, required-interface=FsftPLTR_tmn_GPS_UTC_Minute
      PokePLTR_tmn_GPS_UTC_Minute: client-com-spec=PokePLTR_tmn_GPS_UTC_Minute, required-interface=PokePLTR_tmn_GPS_UTC_Minute
      FsftPLTR_t_GPS_UTC_Second: client-com-spec=FsftPLTR_t_GPS_UTC_Second, required-interface=FsftPLTR_t_GPS_UTC_Second
      PokePLTR_t_GPS_UTC_Second: client-com-spec=PokePLTR_t_GPS_UTC_Second, required-interface=PokePLTR_t_GPS_UTC_Second
      PokeCITR_K_Time_Hour1: client-com-spec=PokeCITR_K_Time_Hour1, required-interface=PokeCITR_K_Time_Hour1
      PokeCITR_K_Time_Hour2: client-com-spec=PokeCITR_K_Time_Hour2, required-interface=PokeCITR_K_Time_Hour2
      PokeCITR_K_Time_Minute1: client-com-spec=PokeCITR_K_Time_Minute1, required-interface=PokeCITR_K_Time_Minute1
      PokeCITR_K_Time_Minute2: client-com-spec=PokeCITR_K_Time_Minute2, required-interface=PokeCITR_K_Time_Minute2
      PokeCITR_K_Date_Month1: client-com-spec=PokeCITR_K_Date_Month1, required-interface=PokeCITR_K_Date_Month1
      PokeCITR_K_Date_Month2: client-com-spec=PokeCITR_K_Date_Month2, required-interface=PokeCITR_K_Date_Month2
      PokeCITR_K_Date_Year{1..4}: client-com-spec=PokeCITR_K_Date_Year{1..4}, required-interface=PokeCITR_K_Date_Year{1..4}
      PokeDMIR_e_PaddleModeReq: client-com-spec=PokeDMIR_e_PaddleModeReq, required-interface=PokeDMIR_e_PaddleModeReq
      FsftPLTR_y_AUD_LVL: client-com-spec=FsftPLTR_y_AUD_LVL, required-interface=FsftPLTR_y_AUD_LVL
      PokePLTR_y_AUD_LVL: client-com-spec=PokePLTR_y_AUD_LVL, required-interface=PokePLTR_y_AUD_LVL
      PokeTIMR_e_RacePrepOnOffReq: variation-point={short-label=vpPokeTIMR_e_RacePrepOnOffReq, sw-syscond=1}, client-com-spec=PokeTIMR_e_RacePrepOnOffReq, required-interface=PokeTIMR_e_RacePrepOnOffReq
      PokeTIMR_e_RadioCustomMode: client-com-spec=PokeTIMR_e_RadioCustomMode, required-interface=PokeTIMR_e_RadioCustomMode
      PokeCITR_b_ChargeNow: client-com-spec=PokeCITR_b_ChargeNow, required-interface=PokeCITR_b_ChargeNow
      PokeTIMR_e_LaunchIntensity: variation-point={short-label=vpPokeTIMR_e_LaunchIntensity, sw-syscond=1}, client-com-spec=PokeTIMR_e_LaunchIntensity, required-interface=PokeTIMR_e_LaunchIntensity
      PokeTIMR_e_RacePrepRaceTypeReq: variation-point={short-label=vpPokeTIMR_e_RacePrepRaceTypeReq, sw-syscond=1}, client-com-spec=PokeTIMR_e_RacePrepRaceTypeReq, required-interface=PokeTIMR_e_RacePrepRaceTypeReq
      PokeDMIR_e_ECoastingReq: client-com-spec=PokeDMIR_e_ECoastingReq, required-interface=PokeDMIR_e_ECoastingReq
      FsftIDCR_b_PlugAndChargeReq: client-com-spec=FsftIDCR_b_PlugAndChargeReq, required-interface=FsftIDCR_b_PlugAndChargeReq
      PokeIDCR_b_PlugAndChargeReq: client-com-spec=PokeIDCR_b_PlugAndChargeReq, required-interface=PokeIDCR_b_PlugAndChargeReq
      TmotIDCR_b_PlugAndChargeReq: client-com-spec=TmotIDCR_b_PlugAndChargeReq, required-interface=TmotIDCR_b_PlugAndChargeReq
      FsftPLTR_b_Secure_Idle_Req: client-com-spec=FsftPLTR_b_Secure_Idle_Req, required-interface=FsftPLTR_b_Secure_Idle_Req
      PokePLTR_b_Secure_Idle_Req: client-com-spec=PokePLTR_b_Secure_Idle_Req, required-interface=PokePLTR_b_Secure_Idle_Req
      PokeTIMR_e_GlobalDrvMdReq: client-com-spec=PokeTIMR_e_GlobalDrvMdReq, required-interface=PokeTIMR_e_GlobalDrvMdReq
      FsftCITR_b_V2HModeReq: client-com-spec=FsftCITR_b_V2HModeReq, required-interface=FsftCITR_b_V2HModeReq
      PokeCITR_b_V2HModeReq: client-com-spec=PokeCITR_b_V2HModeReq, required-interface=PokeCITR_b_V2HModeReq
      FsftCITR_b_V2HReq: client-com-spec=FsftCITR_b_V2HReq, required-interface=FsftCITR_b_V2HReq
      PokeCITR_b_V2HReq: client-com-spec=PokeCITR_b_V2HReq, required-interface=PokeCITR_b_V2HReq
      FsftCITR_Pct_V2HRsrvBatt: client-com-spec=FsftCITR_Pct_V2HRsrvBatt, required-interface=FsftCITR_Pct_V2HRsrvBatt
      PokeCITR_Pct_V2HRsrvBatt: client-com-spec=PokeCITR_Pct_V2HRsrvBatt, required-interface=PokeCITR_Pct_V2HRsrvBatt
      FsftCITR_b_V2HSubmit: client-com-spec=FsftCITR_b_V2HSubmit, required-interface=FsftCITR_b_V2HSubmit
      PokeCITR_b_V2HSubmit: client-com-spec=PokeCITR_b_V2HSubmit, required-interface=PokeCITR_b_V2HSubmit
      FsftCITR_b_V2L_AllReq: client-com-spec=FsftCITR_b_V2L_AllReq, required-interface=FsftCITR_b_V2L_AllReq
      PokeCITR_b_V2L_AllReq: client-com-spec=PokeCITR_b_V2L_AllReq, required-interface=PokeCITR_b_V2L_AllReq
      FsftCITR_b_V2L_FrunkReq: client-com-spec=FsftCITR_b_V2L_FrunkReq, required-interface=FsftCITR_b_V2L_FrunkReq
      PokeCITR_b_V2L_FrunkReq: client-com-spec=PokeCITR_b_V2L_FrunkReq, required-interface=PokeCITR_b_V2L_FrunkReq
      FsftCITR_b_V2LModeReq: client-com-spec=FsftCITR_b_V2LModeReq, required-interface=FsftCITR_b_V2LModeReq
      PokeCITR_b_V2LModeReq: client-com-spec=PokeCITR_b_V2LModeReq, required-interface=PokeCITR_b_V2LModeReq
      FsftCITR_Pct_V2LRsrvBatt: client-com-spec=FsftCITR_Pct_V2LRsrvBatt, required-interface=FsftCITR_Pct_V2LRsrvBatt
      PokeCITR_Pct_V2LRsrvBatt: client-com-spec=PokeCITR_Pct_V2LRsrvBatt, required-interface=PokeCITR_Pct_V2LRsrvBatt
      FsftCITR_b_V2LSubmit: client-com-spec=FsftCITR_b_V2LSubmit, required-interface=FsftCITR_b_V2LSubmit
      PokeCITR_b_V2LSubmit: client-com-spec=PokeCITR_b_V2LSubmit, required-interface=PokeCITR_b_V2LSubmit
      FsftCITR_b_V2LTrunkReq: client-com-spec=FsftCITR_b_V2LTrunkReq, required-interface=FsftCITR_b_V2LTrunkReq
      PokeCITR_b_V2LTrunkReq: client-com-spec=PokeCITR_b_V2LTrunkReq, required-interface=PokeCITR_b_V2LTrunkReq
      FsftCITR_b_V2VModeReq: client-com-spec=FsftCITR_b_V2VModeReq, required-interface=FsftCITR_b_V2VModeReq
      PokeCITR_b_V2VModeReq: client-com-spec=PokeCITR_b_V2VModeReq, required-interface=PokeCITR_b_V2VModeReq
      FsftCITR_b_V2VReq: client-com-spec=FsftCITR_b_V2VReq, required-interface=FsftCITR_b_V2VReq
      PokeCITR_b_V2VReq: client-com-spec=PokeCITR_b_V2VReq, required-interface=PokeCITR_b_V2VReq
      FsftCITR_Pct_V2VRsrvBatt: client-com-spec=FsftCITR_Pct_V2VRsrvBatt, required-interface=FsftCITR_Pct_V2VRsrvBatt
      PokeCITR_Pct_V2VRsrvBatt: client-com-spec=PokeCITR_Pct_V2VRsrvBatt, required-interface=PokeCITR_Pct_V2VRsrvBatt
      FsftCITR_b_V2VSubmit: client-com-spec=FsftCITR_b_V2VSubmit, required-interface=FsftCITR_b_V2VSubmit
      PokeCITR_b_V2VSubmit: client-com-spec=PokeCITR_b_V2VSubmit, required-interface=PokeCITR_b_V2VSubmit
      FsftPLTR_b_ACC_On: client-com-spec=FsftPLTR_b_ACC_On, required-interface=FsftPLTR_b_ACC_On
      PokePLTR_b_ACC_On: client-com-spec=PokePLTR_b_ACC_On, required-interface=PokePLTR_b_ACC_On
      PokeCCTR_b_CcAccelSts: client-com-spec=PokeCCTR_b_CcAccelSts, required-interface=PokeCCTR_b_CcAccelSts
      PokeCCTR_b_CcFailSts: client-com-spec=PokeCCTR_b_CcFailSts, required-interface=PokeCCTR_b_CcFailSts
      PokeCCTR_b_CcOnOffSts: client-com-spec=PokeCCTR_b_CcOnOffSts, required-interface=PokeCCTR_b_CcOnOffSts
      PokeCCTR_b_CcCancelSw: client-com-spec=PokeCCTR_b_CcCancelSw, required-interface=PokeCCTR_b_CcCancelSw
      PokeCCTR_b_CcDecelSts: client-com-spec=PokeCCTR_b_CcDecelSts, required-interface=PokeCCTR_b_CcDecelSts
      PokeCCTR_b_CcResumeSw: client-com-spec=PokeCCTR_b_CcResumeSw, required-interface=PokeCCTR_b_CcResumeSw
      FsftASLR_b_SpdLmtrOnOffSts: client-com-spec=FsftASLR_b_SpdLmtrOnOffSts, required-interface=FsftASLR_b_SpdLmtrOnOffSts
      PokeASLR_b_SpdLmtrOnOffSts: client-com-spec=PokeASLR_b_SpdLmtrOnOffSts, required-interface=PokeASLR_b_SpdLmtrOnOffSts
      FsftTRIR_b_AHP_EnblReq: client-com-spec=FsftTRIR_b_AHP_EnblReq, required-interface=FsftTRIR_b_AHP_EnblReq
      PokeTRIR_b_AHP_EnblReq: client-com-spec=PokeTRIR_b_AHP_EnblReq, required-interface=PokeTRIR_b_AHP_EnblReq
      PokeTAIR_b_WinshldDfrst: client-com-spec=PokeTAIR_b_WinshldDfrst, required-interface=PokeTAIR_b_WinshldDfrst
      FsftTAIR_Pct_DrvTmpDr_Pos: client-com-spec=FsftTAIR_Pct_DrvTmpDr_Pos, required-interface=FsftTAIR_Pct_DrvTmpDr_Pos
      PokeTAIR_Pct_DrvTmpDr_Pos: client-com-spec=PokeTAIR_Pct_DrvTmpDr_Pos, required-interface=PokeTAIR_Pct_DrvTmpDr_Pos
      FsftTAIR_T_FtEvapTmp_Tgt: client-com-spec=FsftTAIR_T_FtEvapTmp_Tgt, required-interface=FsftTAIR_T_FtEvapTmp_Tgt
      PokeTAIR_T_FtEvapTmp_Tgt: client-com-spec=PokeTAIR_T_FtEvapTmp_Tgt, required-interface=PokeTAIR_T_FtEvapTmp_Tgt
      FsftASLR_b_LaneCenteringOnOffSts: client-com-spec=FsftASLR_b_LaneCenteringOnOffSts, required-interface=FsftASLR_b_LaneCenteringOnOffSts
      PokeASLR_b_LaneCenteringOnOffSts: client-com-spec=PokeASLR_b_LaneCenteringOnOffSts, required-interface=PokeASLR_b_LaneCenteringOnOffSts
      FsftTAIR_Pct_FrtBlwrCmd: client-com-spec=FsftTAIR_Pct_FrtBlwrCmd, required-interface=FsftTAIR_Pct_FrtBlwrCmd
      PokeTAIR_Pct_FrtBlwrCmd: client-com-spec=PokeTAIR_Pct_FrtBlwrCmd, required-interface=PokeTAIR_Pct_FrtBlwrCmd
      FsftTAIR_T_HtrCoreTmp_Tgt: client-com-spec=FsftTAIR_T_HtrCoreTmp_Tgt, required-interface=FsftTAIR_T_HtrCoreTmp_Tgt
      PokeTAIR_T_HtrCoreTmp_Tgt: client-com-spec=PokeTAIR_T_HtrCoreTmp_Tgt, required-interface=PokeTAIR_T_HtrCoreTmp_Tgt
      FsftTAIR_Pct_PasTmpDr_Pos: client-com-spec=FsftTAIR_Pct_PasTmpDr_Pos, required-interface=FsftTAIR_Pct_PasTmpDr_Pos
      PokeTAIR_Pct_PasTmpDr_Pos: client-com-spec=PokeTAIR_Pct_PasTmpDr_Pos, required-interface=PokeTAIR_Pct_PasTmpDr_Pos
      FsftTRIR_Pct_AirHtwPwrTgt: client-com-spec=FsftTRIR_Pct_AirHtwPwrTgt, required-interface=FsftTRIR_Pct_AirHtwPwrTgt
      PokeTRIR_Pct_AirHtwPwrTgt: client-com-spec=PokeTRIR_Pct_AirHtwPwrTgt, required-interface=PokeTRIR_Pct_AirHtwPwrTgt
      FsftTRIR_b_HSW_Sts: client-com-spec=FsftTRIR_b_HSW_Sts, required-interface=FsftTRIR_b_HSW_Sts
      PokeTRIR_e_HSW_Sts: client-com-spec=PokeTRIR_e_HSW_Sts, required-interface=PokeTRIR_e_HSW_Sts
      FsftTAIR_T_VhIntTmp: client-com-spec=FsftTAIR_T_VhIntTmp, required-interface=FsftTAIR_T_VhIntTmp
      PokeTAIR_T_VhIntTmp: client-com-spec=PokeTAIR_T_VhIntTmp, required-interface=PokeTAIR_T_VhIntTmp
      FsftBTQR_M_DrvrIntndedTotBrkTrq: client-com-spec=FsftBTQR_M_DrvrIntndedTotBrkTrq, required-interface=FsftBTQR_M_DrvrIntndedTotBrkTrq
      PokeBTQR_M_DrvrIntndedTotBrkTrq: client-com-spec=PokeBTQR_M_DrvrIntndedTotBrkTrq, required-interface=PokeBTQR_M_DrvrIntndedTotBrkTrq
      FsftBTQR_M_BrkTrq_Driver: client-com-spec=FsftBTQR_M_BrkTrq_Driver, required-interface=FsftBTQR_M_BrkTrq_Driver
      PokeBTQR_M_BrkTrq_Driver: client-com-spec=PokeBTQR_M_BrkTrq_Driver, required-interface=PokeBTQR_M_BrkTrq_Driver
      FsftBRKR_b_BrkTmpSts: variation-point={short-label=vpFsftBRKR_b_BrkTmpSts, sw-syscond=1}, client-com-spec=FsftBRKR_b_BrkTmpSts, required-interface=FsftBRKR_b_BrkTmpSts
      PokeBRKR_b_BrkTmpSts: variation-point={short-label=vpPokeBRKR_b_BrkTmpSts, sw-syscond=1}, client-com-spec=PokeBRKR_b_BrkTmpSts, required-interface=PokeBRKR_b_BrkTmpSts
      FsftBRKR_e_ExtBrkReqOff: client-com-spec=FsftBRKR_e_ExtBrkReqOff, required-interface=FsftBRKR_e_ExtBrkReqOff
      PokeBRKR_e_ExtBrkReqOff: client-com-spec=PokeBRKR_e_ExtBrkReqOff, required-interface=PokeBRKR_e_ExtBrkReqOff
      FsftASLR_b_Hill_Des_Status: client-com-spec=FsftASLR_b_Hill_Des_Status, required-interface=FsftASLR_b_Hill_Des_Status
      PokeASLR_e_Hill_Des_Status: client-com-spec=PokeASLR_e_Hill_Des_Status, required-interface=PokeASLR_e_Hill_Des_Status
      FsftPLTR_e_SelectSpdSts: client-com-spec=FsftPLTR_e_SelectSpdSts, required-interface=FsftPLTR_e_SelectSpdSts
      PokePLTR_e_SelectSpdSts: client-com-spec=PokePLTR_e_SelectSpdSts, required-interface=PokePLTR_e_SelectSpdSts
      FsftBRKR_b_VehicleStandStillSts: variation-point={short-label=vpFsftBRKR_b_VehicleStandStillSts, sw-syscond=1}, client-com-spec=FsftBRKR_b_VehicleStandStillSts, required-interface=FsftBRKR_b_VehicleStandStillSts
      PokeBRKR_b_VehicleStandStillSts: variation-point={short-label=vpPokeBRKR_b_VehicleStandStillSts, sw-syscond=1}, client-com-spec=PokeBRKR_b_VehicleStandStillSts, required-interface=PokeBRKR_b_VehicleStandStillSts
      FsftPLTR_e_eBurn_Stages: client-com-spec=FsftPLTR_e_eBurn_Stages, required-interface=FsftPLTR_e_eBurn_Stages
      PokePLTR_e_eBurn_Stages: client-com-spec=PokePLTR_e_eBurn_Stages, required-interface=PokePLTR_e_eBurn_Stages
      FsftBRKR_b_ABSActive: client-com-spec=FsftBRKR_b_ABSActive, required-interface=FsftBRKR_b_ABSActive
      PokeBRKR_b_ABSActive: client-com-spec=PokeBRKR_b_ABSActive, required-interface=PokeBRKR_b_ABSActive
      FsftBRKR_e_AHH_Ready_Status: client-com-spec=FsftBRKR_e_AHH_Ready_Status, required-interface=FsftBRKR_e_AHH_Ready_Status
      PokeBRKR_e_AHH_Ready_Status: client-com-spec=PokeBRKR_e_AHH_Ready_Status, required-interface=PokeBRKR_e_AHH_Ready_Status
      FsftBRKR_P_BrkPrss: client-com-spec=FsftBRKR_P_BrkPrss, required-interface=FsftBRKR_P_BrkPrss
      PokeBRKR_P_BrkPrss: client-com-spec=PokeBRKR_P_BrkPrss, required-interface=PokeBRKR_P_BrkPrss
      FsftBTQR_b_ESCEvntActv: client-com-spec=FsftBTQR_b_ESCEvntActv, required-interface=FsftBTQR_b_ESCEvntActv
      PokeBTQR_b_ESCEvntActv: client-com-spec=PokeBTQR_b_ESCEvntActv, required-interface=PokeBTQR_b_ESCEvntActv
      FsftBRKR_pbar_BrakePedalPressure: client-com-spec=FsftBRKR_pbar_BrakePedalPressure, required-interface=FsftBRKR_pbar_BrakePedalPressure
      PokeBRKR_pbar_BrakePedalPressure: client-com-spec=PokeBRKR_pbar_BrakePedalPressure, required-interface=PokeBRKR_pbar_BrakePedalPressure
      FsftBRKR_b_AeCoastReady: client-com-spec=FsftBRKR_b_AeCoastReady, required-interface=FsftBRKR_b_AeCoastReady
      PokeBRKR_b_AeCoastReady: client-com-spec=PokeBRKR_b_AeCoastReady, required-interface=PokeBRKR_b_AeCoastReady
      FsftBRKR_b_ESCActive: client-com-spec=FsftBRKR_b_ESCActive, required-interface=FsftBRKR_b_ESCActive
      PokeBRKR_b_ESCActive: client-com-spec=PokeBRKR_b_ESCActive, required-interface=PokeBRKR_b_ESCActive
      PokeBRKR_b_ImpndSkid: client-com-spec=PokeBRKR_b_ImpndSkid, required-interface=PokeBRKR_b_ImpndSkid
      FsftPLTR_a_TransAccel: client-com-spec=FsftPLTR_a_TransAccel, required-interface=FsftPLTR_a_TransAccel
      PokePLTR_a_TransAccel: client-com-spec=PokePLTR_a_TransAccel, required-interface=PokePLTR_a_TransAccel
      FsftPLTR_a_LongAccel: client-com-spec=FsftPLTR_a_LongAccel, required-interface=FsftPLTR_a_LongAccel
      PokePLTR_a_LongAccel: client-com-spec=PokePLTR_a_LongAccel, required-interface=PokePLTR_a_LongAccel
      FsftPLTR_e_ParkingGearShiftReq_BSM: client-com-spec=FsftPLTR_e_ParkingGearShiftReq_BSM, required-interface=FsftPLTR_e_ParkingGearShiftReq_BSM
      PokePLTR_e_ParkingGearShiftReq_BSM: client-com-spec=PokePLTR_e_ParkingGearShiftReq_BSM, required-interface=PokePLTR_e_ParkingGearShiftReq_BSM
      FsftPLTR_Pct_Slope: client-com-spec=FsftPLTR_Pct_Slope, required-interface=FsftPLTR_Pct_Slope
      PokePLTR_Pct_Slope: client-com-spec=PokePLTR_Pct_Slope, required-interface=PokePLTR_Pct_Slope
      FsftCSVR_v_CanSigVehSpd: client-com-spec=FsftCSVR_v_CanSigVehSpd, required-interface=FsftCSVR_v_CanSigVehSpd
      PokeCSVR_v_CanSigVehSpd: client-com-spec=PokeCSVR_v_CanSigVehSpd, required-interface=PokeCSVR_v_CanSigVehSpd
      FsftCSVR_n_LeftFrontWhl: client-com-spec=FsftCSVR_n_LeftFrontWhl, required-interface=FsftCSVR_n_LeftFrontWhl
      PokeCSVR_n_LeftFrontWhl: client-com-spec=PokeCSVR_n_LeftFrontWhl, required-interface=PokeCSVR_n_LeftFrontWhl
      FsftCSVR_e_LeftFrontWhlDir: client-com-spec=FsftCSVR_e_LeftFrontWhlDir, required-interface=FsftCSVR_e_LeftFrontWhlDir
      PokeCSVR_e_LeftFrontWhlDir: client-com-spec=PokeCSVR_e_LeftFrontWhlDir, required-interface=PokeCSVR_e_LeftFrontWhlDir
      PokeCSVR_b_WheelSensorFailStsLHF: client-com-spec=PokeCSVR_b_WheelSensorFailStsLHF, required-interface=PokeCSVR_b_WheelSensorFailStsLHF
      FsftCSVR_n_LeftRearWhl: client-com-spec=FsftCSVR_n_LeftRearWhl, required-interface=FsftCSVR_n_LeftRearWhl
      PokeCSVR_n_LeftRearWhl: client-com-spec=PokeCSVR_n_LeftRearWhl, required-interface=PokeCSVR_n_LeftRearWhl
      FsftCSVR_e_LeftRearWhlDir: client-com-spec=FsftCSVR_e_LeftRearWhlDir, required-interface=FsftCSVR_e_LeftRearWhlDir
      PokeCSVR_e_LeftRearWhlDir: client-com-spec=PokeCSVR_e_LeftRearWhlDir, required-interface=PokeCSVR_e_LeftRearWhlDir
      PokeCSVR_b_WheelSensorFailStsLHR: client-com-spec=PokeCSVR_b_WheelSensorFailStsLHR, required-interface=PokeCSVR_b_WheelSensorFailStsLHR
      FsftCSVR_n_RightFrontWhl: client-com-spec=FsftCSVR_n_RightFrontWhl, required-interface=FsftCSVR_n_RightFrontWhl
      PokeCSVR_n_RightFrontWhl: client-com-spec=PokeCSVR_n_RightFrontWhl, required-interface=PokeCSVR_n_RightFrontWhl
      FsftCSVR_e_RightFrontWhlDir: client-com-spec=FsftCSVR_e_RightFrontWhlDir, required-interface=FsftCSVR_e_RightFrontWhlDir
      PokeCSVR_e_RightFrontWhlDir: client-com-spec=PokeCSVR_e_RightFrontWhlDir, required-interface=PokeCSVR_e_RightFrontWhlDir
      PokeCSVR_b_WheelSensorFailStsRHF: client-com-spec=PokeCSVR_b_WheelSensorFailStsRHF, required-interface=PokeCSVR_b_WheelSensorFailStsRHF
      FsftCSVR_n_RightRearWhl: client-com-spec=FsftCSVR_n_RightRearWhl, required-interface=FsftCSVR_n_RightRearWhl
      PokeCSVR_n_RightRearWhl: client-com-spec=PokeCSVR_n_RightRearWhl, required-interface=PokeCSVR_n_RightRearWhl
      FsftCSVR_e_RightRearWhlDir: client-com-spec=FsftCSVR_e_RightRearWhlDir, required-interface=FsftCSVR_e_RightRearWhlDir
      PokeCSVR_e_RightRearWhlDir: client-com-spec=PokeCSVR_e_RightRearWhlDir, required-interface=PokeCSVR_e_RightRearWhlDir
      PokeCSVR_b_WheelSensorFailStsRHR: client-com-spec=PokeCSVR_b_WheelSensorFailStsRHR, required-interface=PokeCSVR_b_WheelSensorFailStsRHR
      FsftBRKR_b_ASRActive: client-com-spec=FsftBRKR_b_ASRActive, required-interface=FsftBRKR_b_ASRActive
      PokeBRKR_b_ASRActive: client-com-spec=PokeBRKR_b_ASRActive, required-interface=PokeBRKR_b_ASRActive
      FsftPLTR_e_EPBHoldSt: client-com-spec=FsftPLTR_e_EPBHoldSt, required-interface=FsftPLTR_e_EPBHoldSt
      PokePLTR_e_EPBHoldSt: client-com-spec=PokePLTR_e_EPBHoldSt, required-interface=PokePLTR_e_EPBHoldSt
      FsftPLTR_l_TravelDistance: client-com-spec=FsftPLTR_l_TravelDistance, required-interface=FsftPLTR_l_TravelDistance
      PokePLTR_l_TravelDistance: client-com-spec=PokePLTR_l_TravelDistance, required-interface=PokePLTR_l_TravelDistance
      PokeBRKR_b_ABSFailSts: client-com-spec=PokeBRKR_b_ABSFailSts, required-interface=PokeBRKR_b_ABSFailSts
      FsftBRKR_b_ESCFailSts: client-com-spec=FsftBRKR_b_ESCFailSts, required-interface=FsftBRKR_b_ESCFailSts
      PokeBRKR_b_ESCFailSts: client-com-spec=PokeBRKR_b_ESCFailSts, required-interface=PokeBRKR_b_ESCFailSts
      FsftBRKR_b_ESCIntervention: client-com-spec=FsftBRKR_b_ESCIntervention, required-interface=FsftBRKR_b_ESCIntervention
      PokeBRKR_b_ESCIntervention: client-com-spec=PokeBRKR_b_ESCIntervention, required-interface=PokeBRKR_b_ESCIntervention
      PokeBRKR_b_FunctionSts: client-com-spec=PokeBRKR_b_FunctionSts, required-interface=PokeBRKR_b_FunctionSts
      FsftBTQR_M_DrvrIntndedFricBrkTrq: client-com-spec=FsftBTQR_M_DrvrIntndedFricBrkTrq, required-interface=FsftBTQR_M_DrvrIntndedFricBrkTrq
      PokeBTQR_M_DrvrIntndedFricBrkTrq: client-com-spec=PokeBTQR_M_DrvrIntndedFricBrkTrq, required-interface=PokeBTQR_M_DrvrIntndedFricBrkTrq
      PokePLTR_e_BSM_AxleTrq_Enbld: client-com-spec=PokePLTR_e_BSM_AxleTrq_Enbld, required-interface=PokePLTR_e_BSM_AxleTrq_Enbld
      FsftCCTR_M_ACCTrq_BSM: client-com-spec=FsftCCTR_M_ACCTrq_BSM, required-interface=FsftCCTR_M_ACCTrq_BSM
      PokeCCTR_M_ACCTrq_BSM: client-com-spec=PokeCCTR_M_ACCTrq_BSM, required-interface=PokeCCTR_M_ACCTrq_BSM
      FsftSCCR_b_FrntAxlMaxRq: client-com-spec=FsftSCCR_b_FrntAxlMaxRq, required-interface=FsftSCCR_b_FrntAxlMaxRq
      PokeSCCR_b_FrntAxlMaxRq: client-com-spec=PokeSCCR_b_FrntAxlMaxRq, required-interface=PokeSCCR_b_FrntAxlMaxRq
      FsftSCCR_b_FrntAxlMinRq: client-com-spec=FsftSCCR_b_FrntAxlMinRq, required-interface=FsftSCCR_b_FrntAxlMinRq
      PokeSCCR_b_FrntAxlMinRq: client-com-spec=PokeSCCR_b_FrntAxlMinRq, required-interface=PokeSCCR_b_FrntAxlMinRq
      FsftSCCR_M_FrntAxlRq: client-com-spec=FsftSCCR_M_FrntAxlRq, required-interface=FsftSCCR_M_FrntAxlRq
      PokeSCCR_M_FrntAxlRq: client-com-spec=PokeSCCR_M_FrntAxlRq, required-interface=PokeSCCR_M_FrntAxlRq
      FsftBRKR_e_Not_OK_To_Race: variation-point={short-label=vpFsftBRKR_e_Not_OK_To_Race, sw-syscond=1}, client-com-spec=FsftBRKR_e_Not_OK_To_Race, required-interface=FsftBRKR_e_Not_OK_To_Race
      PokeBRKR_e_Not_OK_To_Race: variation-point={short-label=vpPokeBRKR_e_Not_OK_To_Race, sw-syscond=1}, client-com-spec=PokeBRKR_e_Not_OK_To_Race, required-interface=PokeBRKR_e_Not_OK_To_Race
      FsftBRKR_e_OPDHoldStatus: client-com-spec=FsftBRKR_e_OPDHoldStatus, required-interface=FsftBRKR_e_OPDHoldStatus
      PokeBRKR_e_OPDHoldStatus: client-com-spec=PokeBRKR_e_OPDHoldStatus, required-interface=PokeBRKR_e_OPDHoldStatus
      FsftSCCR_b_RrAxlMaxRq: client-com-spec=FsftSCCR_b_RrAxlMaxRq, required-interface=FsftSCCR_b_RrAxlMaxRq
      PokeSCCR_b_RrAxlMaxRq: client-com-spec=PokeSCCR_b_RrAxlMaxRq, required-interface=PokeSCCR_b_RrAxlMaxRq
      FsftSCCR_b_RrAxlMinRq: client-com-spec=FsftSCCR_b_RrAxlMinRq, required-interface=FsftSCCR_b_RrAxlMinRq
      PokeSCCR_b_RrAxlMinRq: client-com-spec=PokeSCCR_b_RrAxlMinRq, required-interface=PokeSCCR_b_RrAxlMinRq
      FsftSCCR_M_RrAxlRq: client-com-spec=FsftSCCR_M_RrAxlRq, required-interface=FsftSCCR_M_RrAxlRq
      PokeSCCR_M_RrAxlRq: client-com-spec=PokeSCCR_M_RrAxlRq, required-interface=PokeSCCR_M_RrAxlRq
      FsftBTQR_M_RegenBrkAxleTrqReq: client-com-spec=FsftBTQR_M_RegenBrkAxleTrqReq, required-interface=FsftBTQR_M_RegenBrkAxleTrqReq
      PokeBTQR_M_RegenBrkAxleTrqReq: client-com-spec=PokeBTQR_M_RegenBrkAxleTrqReq, required-interface=PokeBTQR_M_RegenBrkAxleTrqReq
      FsftADIR_b_BSM_WEDModeReq: client-com-spec=FsftADIR_b_BSM_WEDModeReq, required-interface=FsftADIR_b_BSM_WEDModeReq
      PokeADIR_e_BSM_WEDModeReq: client-com-spec=PokeADIR_e_BSM_WEDModeReq, required-interface=PokeADIR_e_BSM_WEDModeReq
      FsftBRKR_b_BrkTravelSts: client-com-spec=FsftBRKR_b_BrkTravelSts, required-interface=FsftBRKR_b_BrkTravelSts
      PokeBRKR_Pct_BrkTravelSts: client-com-spec=PokeBRKR_Pct_BrkTravelSts, required-interface=PokeBRKR_Pct_BrkTravelSts
      FsftBRKR_b_BrkPdlFlt: client-com-spec=FsftBRKR_b_BrkPdlFlt, required-interface=FsftBRKR_b_BrkPdlFlt
      PokeBRKR_b_BrkPdlFlt: client-com-spec=PokeBRKR_b_BrkPdlFlt, required-interface=PokeBRKR_b_BrkPdlFlt
      FsftBRKR_b_BrkPedalDscrtInpt: client-com-spec=FsftBRKR_b_BrkPedalDscrtInpt, required-interface=FsftBRKR_b_BrkPedalDscrtInpt
      PokeBRKR_e_BrkPedalDscrtInpt: client-com-spec=PokeBRKR_e_BrkPedalDscrtInpt, required-interface=PokeBRKR_e_BrkPedalDscrtInpt
      PokeIMOR_y_CntrlEncdResp: client-com-spec=PokeIMOR_y_CntrlEncdResp, required-interface=PokeIMOR_y_CntrlEncdResp
      FsftPLTR_b_ImmoParkReq: client-com-spec=FsftPLTR_b_ImmoParkReq, required-interface=FsftPLTR_b_ImmoParkReq
      PokePLTR_b_ImmoParkReq: client-com-spec=PokePLTR_b_ImmoParkReq, required-interface=PokePLTR_b_ImmoParkReq
      PokeIMOR_y_MMKey1org21: client-com-spec=PokeIMOR_y_MMKey1org21, required-interface=PokeIMOR_y_MMKey1org21
      PokeIMOR_y_MMKey1org22: client-com-spec=PokeIMOR_y_MMKey1org22, required-interface=PokeIMOR_y_MMKey1org22
      PokeIMOR_y_MMKey_{3..6}: client-com-spec=PokeIMOR_y_MMKey_{3..6}, required-interface=PokeIMOR_y_MMKey_{3..6}
